[part 14 of 22: package /Cluster]
AUTOSAR XML (schema 4-3-0)
package /Cluster  (continued)
  9 x lin cluster, all with baudrate=19200, protocol-name=LIN, protocol-version=2.0:  (continued)
    E3V_SAM_LIN9
      lin physical channel CHNL: comm-connectors=CN_E3V_SAM_LIN9
        frame MasterReq_XIX_E3V_SAM_LIN9: id 0x3C, from SAM, frame-length=8, lin-checksum=CLASSIC
          n pdu MasterReq_XIX_E3V_SAM_LIN9: length=8
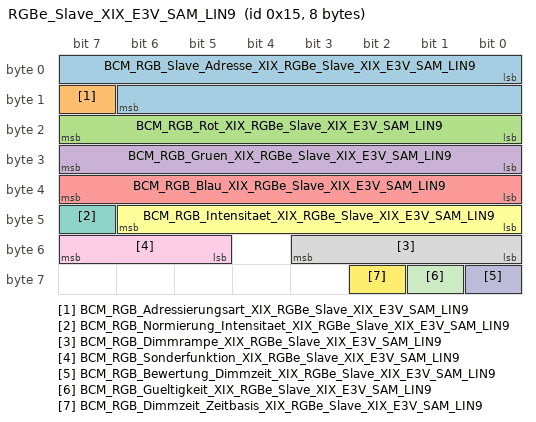
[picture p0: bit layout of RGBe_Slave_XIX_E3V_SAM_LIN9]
        frame RGBe_Slave_XIX_E3V_SAM_LIN9: id 0x15, from SAM, frame-length=8, lin-checksum=ENHANCED
          pdu RGBe_Slave_XIX_E3V_SAM_LIN9: length=8, unused-bit-pattern=0
            signal BCM_RGB_Slave_Adresse_XIX_RGBe_Slave_XIX_E3V_SAM_LIN9: start 0, 15 bit, little-endian, data-type-policy=OVERRIDE, i-signal-type=PRIMITIVE, base-type=BT_BCM_RGB_Slave_Adresse, compu {phys=raw for raw 0..32767; unit Unit_None}, range phys 0..32767 Unit_None, raw 0..32767, unit=Unit_None, transfer-property=PENDING  # Auswahl der Adresse für die RGB-Slaves (Hinweis: Adressierungsart beachten)
            signal BCM_RGB_Adressierungsart_XIX_RGBe_Slave_XIX_E3V_SAM_LIN9: start 15, 1 bit, little-endian, data-type-policy=OVERRIDE, i-signal-type=PRIMITIVE, base-type=BT_BCM_RGB_Adressierungsart, compu {0=Cx0_Einzeladresse (CM_BCM_RGB_Adressierungsart_Cx0_Einzeladresse), 1=Cx1_Gruppenadresse (CM_BCM_RGB_Adressierungsart_Cx1_Gruppenadresse)}, range raw 0..1, transfer-property=PENDING  # Auswahl der Adressierungsart für die RGB-Slaves: 0 = Einzeladadresse (Wertecodierung) 1 = Gruppenadresse
            signal BCM_RGB_Rot_XIX_RGBe_Slave_XIX_E3V_SAM_LIN9: start 16, 8 bit, little-endian, data-type-policy=OVERRIDE, i-signal-type=PRIMITIVE, base-type=BT_BCM_RGB_Rot, compu {phys=raw for raw 0..255}, range phys 0..255, raw 0..255, transfer-property=PENDING  # Farbanteil "Rot"
            signal BCM_RGB_Gruen_XIX_RGBe_Slave_XIX_E3V_SAM_LIN9: start 24, 8 bit, little-endian, data-type-policy=OVERRIDE, i-signal-type=PRIMITIVE, base-type=BT_BCM_RGB_Gruen, compu {phys=raw for raw 0..255}, range phys 0..255, raw 0..255, transfer-property=PENDING  # Farbanteil "Grün"
            signal BCM_RGB_Blau_XIX_RGBe_Slave_XIX_E3V_SAM_LIN9: start 32, 8 bit, little-endian, data-type-policy=OVERRIDE, i-signal-type=PRIMITIVE, base-type=BT_BCM_RGB_Blau, compu {phys=raw for raw 0..255}, range phys 0..255, raw 0..255, transfer-property=PENDING  # Farbanteil "Blau"
            signal BCM_RGB_Intensitaet_XIX_RGBe_Slave_XIX_E3V_SAM_LIN9: start 40, 7 bit, little-endian, data-type-policy=OVERRIDE, i-signal-type=PRIMITIVE, init-value=126, base-type=BT_BCM_RGB_Intensitaet, invalid-value=Invalid_BCM_RGB_Intensitaet_XIX_RGBe_Slave_XIX_E3V_SAM_LIN9:127, compu {phys=raw for raw 0..100, 126=Cx7e_Init (CM_BCM_RGB_Intensitaet_Cx7e_Init), 127=Cx7f_Fehler (CM_BCM_RGB_Intensitaet_Cx7f_Fehler); unit Unit_PerCent}, range phys 0..100 Unit_PerCent, raw 0..127, unit=Unit_PerCent, transfer-property=PENDING  # Intensität für RGB-Slave
            signal BCM_RGB_Normierung_Intensitaet_XIX_RGBe_Slave_XIX_E3V_SAM_LIN9: start 47, 1 bit, little-endian, data-type-policy=OVERRIDE, i-signal-type=PRIMITIVE, base-type=BT_BCM_RGB_Normierung_Intensitaet, compu {0=Cx0_ohne_Normierung (CM_BCM_RGB_Normierung_Intensitaet_Cx0_ohne_Normierung) (ohne Normierung), 1=Cx1_Normierung_der_Intensitaet (CM_BCM_RGB_Normierung_Intensitaet_Cx1_Normierung_der_Intensitaet) (Normierung der Intensität)}, range raw 0..1, transfer-property=PENDING  # Normierung der Intensität für die RGB-Slaves: 0 = keine Normierung 1 = Normierung
            signal BCM_RGB_Dimmrampe_XIX_RGBe_Slave_XIX_E3V_SAM_LIN9: start 48, 4 bit, little-endian, data-type-policy=OVERRIDE, i-signal-type=PRIMITIVE, base-type=BT_BCM_RGB_Dimmrampe, compu {phys=raw*0.25 for raw 0..15; unit Unit_Secon}, range phys 0..3.75 Unit_Secon, raw 0..15, unit=Unit_Secon, transfer-property=PENDING  # Vorgabe "Dimmzeit" für RGB-Slave
            signal BCM_RGB_Sonderfunktion_XIX_RGBe_Slave_XIX_E3V_SAM_LIN9: start 53, 3 bit, little-endian, data-type-policy=OVERRIDE, i-signal-type=PRIMITIVE, init-value=0, base-type=BT_BCM_RGB_Sonderfunktion, compu {0=Cx0_keine_Sonderfunktion (CM_BCM_RGB_Sonderfunktion_Cx0_keine_Sonderfunktion) (keine Sonderfunktion), 1=Cx1_Crash (CM_BCM_RGB_Sonderfunktion_Cx1_Crash), 2=Cx2_Showroommodus (CM_BCM_RGB_Sonderfunktion_Cx2_Showroommodus), 3=Cx3_Stellgliedtest (CM_BCM_RGB_Sonderfunktion_Cx3_Stellgliedtest), 4=Cx4_Vorhalt_z_B_FAS_Warnung (CM_BCM_RGB_Sonderfunktion_Cx4_Vorhalt_z_B_FAS_Warnung) (Vorhalt (z.B. FAS-Warnung)), 5=Cx5_Vorhalt (CM_BCM_RGB_Sonderfunktion_Cx5_Vorhalt), 6=Cx6_Lauflicht_Rueckwaerts (CM_BCM_RGB_Sonderfunktion_Cx6_Lauflicht_Rueckwaerts), 7=Cx7_Lauflicht_Vorwaerts (CM_BCM_RGB_Sonderfunktion_Cx7_Lauflicht_Vorwaerts)}, range raw 0..7, transfer-property=PENDING  # Aktivierung "Sonderfunktionen" im RGB-Slave
            signal BCM_RGB_Bewertung_Dimmzeit_XIX_RGBe_Slave_XIX_E3V_SAM_LIN9: start 56, 1 bit, little-endian, data-type-policy=OVERRIDE, i-signal-type=PRIMITIVE, base-type=BT_BCM_RGB_Bewertung_Dimmzeit, compu {0=Cx0_Dimmzeit_absolut (CM_BCM_RGB_Bewertung_Dimmzeit_Cx0_Dimmzeit_absolut), 1=Cx1_Dimmzeit_relativ (CM_BCM_RGB_Bewertung_Dimmzeit_Cx1_Dimmzeit_relativ)}, range raw 0..1, transfer-property=PENDING  # Interpretation der Dimmzeit im Slave: 0 - absolute Dimmzeit (von 0% auf 100%) 1 - relative Dimmzeit (von Ist- auf die Soll-Helligkeit)
            signal BCM_RGB_Gueltigkeit_XIX_RGBe_Slave_XIX_E3V_SAM_LIN9: start 57, 1 bit, little-endian, data-type-policy=OVERRIDE, i-signal-type=PRIMITIVE, base-type=BT_BCM_RGB_Gueltigkeit, compu {0=Cx0_ungueltig (CM_BCM_RGB_Gueltigkeit_Cx0_ungueltig), 1=Cx1_gueltig (CM_BCM_RGB_Gueltigkeit_Cx1_gueltig)}, range raw 0..1, transfer-property=PENDING  # Qualifizierungsinformation (notwendig bei der Übertragung "relativer" Dimmzeiten) 0 - Signale werden vom LIN-Slave ignoriert 1 - Signale sind vom LIN-Slave umzusetzen
            signal BCM_RGB_Dimmzeit_Zeitbasis_XIX_RGBe_Slave_XIX_E3V_SAM_LIN9: start 58, 1 bit, little-endian, data-type-policy=OVERRIDE, i-signal-type=PRIMITIVE, init-value=0, base-type=BT_BCM_RGB_Dimmzeit_Zeitbasis, compu {0=Cx0_Zeitbasis_50ms (CM_BCM_RGB_Dimmzeit_Zeitbasis_Cx0_Zeitbasis_50ms), 1=Cx1_Zeitbasis_250ms (CM_BCM_RGB_Dimmzeit_Zeitbasis_Cx1_Zeitbasis_250ms)}, range raw 0..1, transfer-property=PENDING  # Umschaltung der Zeitbasis für die Berechnung der Dimmzeit zwischen 250ms (Altwert, log. Signalwert: 1) und 50ms (log. Signalwert: 0)
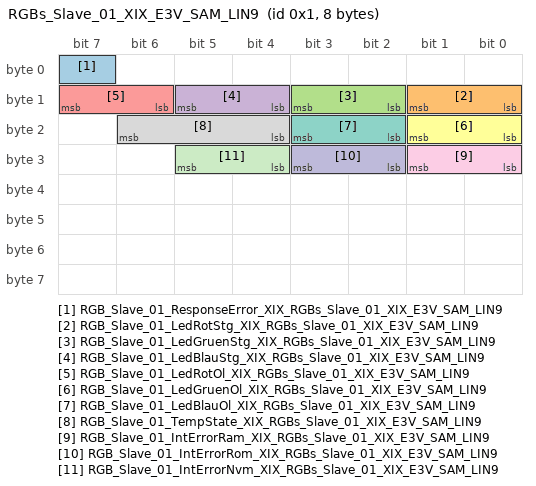
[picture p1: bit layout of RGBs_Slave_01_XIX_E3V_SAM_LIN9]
        frame RGBs_Slave_01_XIX_E3V_SAM_LIN9: id 0x1, to SAM, frame-length=8, lin-checksum=ENHANCED
          pdu RGBs_Slave_01_XIX_E3V_SAM_LIN9: length=8, unused-bit-pattern=0
            signal RGB_Slave_01_ResponseError_XIX_RGBs_Slave_01_XIX_E3V_SAM_LIN9: start 7, 1 bit, little-endian, data-type-policy=OVERRIDE, i-signal-type=PRIMITIVE, init-value=0, base-type=BT_RGB_Slave_01_ResponseError, invalid-value=Invalid_RGB_Slave_01_ResponseError_XIX_RGBs_Slave_01_XIX_E3V_SAM_LIN9:1, compu {0=Cx0_normal (CM_RGB_Slave_01_ResponseError_Cx0_normal), 1=Cx1_Fehler (CM_RGB_Slave_01_ResponseError_Cx1_Fehler)}, range raw 0..1, transfer-property=PENDING, to SAM(timeout 3.5 s)  # siehe LIN2.0-Specification (Darf nicht über ein Fehlergueltigkeitsbit abgesichtert werden!)
            signal RGB_Slave_01_LedRotStg_XIX_RGBs_Slave_01_XIX_E3V_SAM_LIN9: start 8, 2 bit, little-endian, data-type-policy=OVERRIDE, i-signal-type=PRIMITIVE, init-value=0, base-type=BT_RGB_Slave_01_LedRotStg, invalid-value=Invalid_RGB_Slave_01_LedRotStg_XIX_RGBs_Slave_01_XIX_E3V_SAM_LIN9:3, compu {0=Cx0_Init (CM_RGB_Slave_01_LedRotStg_Cx0_Init), 1=Cx1_nicht_erlaubt (CM_RGB_Slave_01_LedRotStg_Cx1_nicht_erlaubt), 2=Cx2_kein_Fehler (CM_RGB_Slave_01_LedRotStg_Cx2_kein_Fehler), 3=Cx3_Fehler (CM_RGB_Slave_01_LedRotStg_Cx3_Fehler)}, range raw 0..3, transfer-property=PENDING, to SAM(timeout 3.5 s)  # Short To Ground für Rote LED
            signal RGB_Slave_01_LedGruenStg_XIX_RGBs_Slave_01_XIX_E3V_SAM_LIN9: start 10, 2 bit, little-endian, data-type-policy=OVERRIDE, i-signal-type=PRIMITIVE, init-value=0, base-type=BT_RGB_Slave_01_LedGruenStg, invalid-value=Invalid_RGB_Slave_01_LedGruenStg_XIX_RGBs_Slave_01_XIX_E3V_SAM_LIN9:3, compu {0=Cx0_Init (CM_RGB_Slave_01_LedGruenStg_Cx0_Init), 1=Cx1_nicht_erlaubt (CM_RGB_Slave_01_LedGruenStg_Cx1_nicht_erlaubt), 2=Cx2_kein_Fehler (CM_RGB_Slave_01_LedGruenStg_Cx2_kein_Fehler), 3=Cx3_Fehler (CM_RGB_Slave_01_LedGruenStg_Cx3_Fehler)}, range raw 0..3, transfer-property=PENDING, to SAM(timeout 3.5 s)  # Short To Ground für Grüne LED
            signal RGB_Slave_01_LedBlauStg_XIX_RGBs_Slave_01_XIX_E3V_SAM_LIN9: start 12, 2 bit, little-endian, data-type-policy=OVERRIDE, i-signal-type=PRIMITIVE, init-value=0, base-type=BT_RGB_Slave_01_LedBlauStg, invalid-value=Invalid_RGB_Slave_01_LedBlauStg_XIX_RGBs_Slave_01_XIX_E3V_SAM_LIN9:3, compu {0=Cx0_Init (CM_RGB_Slave_01_LedBlauStg_Cx0_Init), 1=Cx1_nicht_erlaubt (CM_RGB_Slave_01_LedBlauStg_Cx1_nicht_erlaubt), 2=Cx2_kein_Fehler (CM_RGB_Slave_01_LedBlauStg_Cx2_kein_Fehler), 3=Cx3_Fehler (CM_RGB_Slave_01_LedBlauStg_Cx3_Fehler)}, range raw 0..3, transfer-property=PENDING, to SAM(timeout 3.5 s)  # Short To Ground für Blaue LED
            signal RGB_Slave_01_LedRotOl_XIX_RGBs_Slave_01_XIX_E3V_SAM_LIN9: start 14, 2 bit, little-endian, data-type-policy=OVERRIDE, i-signal-type=PRIMITIVE, init-value=0, base-type=BT_RGB_Slave_01_LedRotOl, invalid-value=Invalid_RGB_Slave_01_LedRotOl_XIX_RGBs_Slave_01_XIX_E3V_SAM_LIN9:3, compu {0=Cx0_Init (CM_RGB_Slave_01_LedRotOl_Cx0_Init), 1=Cx1_nicht_erlaubt (CM_RGB_Slave_01_LedRotOl_Cx1_nicht_erlaubt), 2=Cx2_kein_Fehler (CM_RGB_Slave_01_LedRotOl_Cx2_kein_Fehler), 3=Cx3_Fehler (CM_RGB_Slave_01_LedRotOl_Cx3_Fehler)}, range raw 0..3, transfer-property=PENDING, to SAM(timeout 3.5 s)  # OpenLoad für Rote LED
            signal RGB_Slave_01_LedGruenOl_XIX_RGBs_Slave_01_XIX_E3V_SAM_LIN9: start 16, 2 bit, little-endian, data-type-policy=OVERRIDE, i-signal-type=PRIMITIVE, init-value=0, base-type=BT_RGB_Slave_01_LedGruenOl, invalid-value=Invalid_RGB_Slave_01_LedGruenOl_XIX_RGBs_Slave_01_XIX_E3V_SAM_LIN9:3, compu {0=Cx0_Init (CM_RGB_Slave_01_LedGruenOl_Cx0_Init), 1=Cx1_nicht_erlaubt (CM_RGB_Slave_01_LedGruenOl_Cx1_nicht_erlaubt), 2=Cx2_kein_Fehler (CM_RGB_Slave_01_LedGruenOl_Cx2_kein_Fehler), 3=Cx3_Fehler (CM_RGB_Slave_01_LedGruenOl_Cx3_Fehler)}, range raw 0..3, transfer-property=PENDING, to SAM(timeout 3.5 s)  # OpenLoad für Rote LED
            signal RGB_Slave_01_LedBlauOl_XIX_RGBs_Slave_01_XIX_E3V_SAM_LIN9: start 18, 2 bit, little-endian, data-type-policy=OVERRIDE, i-signal-type=PRIMITIVE, init-value=0, base-type=BT_RGB_Slave_01_LedBlauOl, invalid-value=Invalid_RGB_Slave_01_LedBlauOl_XIX_RGBs_Slave_01_XIX_E3V_SAM_LIN9:3, compu {0=Cx0_Init (CM_RGB_Slave_01_LedBlauOl_Cx0_Init), 1=Cx1_nicht_erlaubt (CM_RGB_Slave_01_LedBlauOl_Cx1_nicht_erlaubt), 2=Cx2_kein_Fehler (CM_RGB_Slave_01_LedBlauOl_Cx2_kein_Fehler), 3=Cx3_Fehler (CM_RGB_Slave_01_LedBlauOl_Cx3_Fehler)}, range raw 0..3, transfer-property=PENDING, to SAM(timeout 3.5 s)  # OpenLoad für Blaue LED
            signal RGB_Slave_01_TempState_XIX_RGBs_Slave_01_XIX_E3V_SAM_LIN9: start 20, 3 bit, little-endian, data-type-policy=OVERRIDE, i-signal-type=PRIMITIVE, base-type=BT_RGB_Slave_01_TempState, compu {0=Cx0_keine_Temperaturregelung (CM_RGB_Slave_01_TempState_Cx0_keine_Temperaturregelung), 1=Cx1_Regelstufe_1 (CM_RGB_Slave_01_TempState_Cx1_Regelstufe_1), 2=Cx2_Regelstufe_2 (CM_RGB_Slave_01_TempState_Cx2_Regelstufe_2), 3=Cx3_Regelstufe_3 (CM_RGB_Slave_01_TempState_Cx3_Regelstufe_3), 4=Cx4_Regelstufe_4 (CM_RGB_Slave_01_TempState_Cx4_Regelstufe_4), 5=Cx5_Regelstufe_5 (CM_RGB_Slave_01_TempState_Cx5_Regelstufe_5), 6=Cx6_Regelstufe_6 (CM_RGB_Slave_01_TempState_Cx6_Regelstufe_6), 7=Cx7_Regelstufe_7 (CM_RGB_Slave_01_TempState_Cx7_Regelstufe_7)}, range raw 0..7, transfer-property=PENDING, to SAM(timeout 3.5 s)  # Status Temperaturregelung
            signal RGB_Slave_01_IntErrorRam_XIX_RGBs_Slave_01_XIX_E3V_SAM_LIN9: start 24, 2 bit, little-endian, data-type-policy=OVERRIDE, i-signal-type=PRIMITIVE, init-value=0, base-type=BT_RGB_Slave_01_IntErrorRam, invalid-value=Invalid_RGB_Slave_01_IntErrorRam_XIX_RGBs_Slave_01_XIX_E3V_SAM_LIN9:3, compu {0=Cx0_Init (CM_RGB_Slave_01_IntErrorRam_Cx0_Init), 1=Cx1_nicht_erlaubt (CM_RGB_Slave_01_IntErrorRam_Cx1_nicht_erlaubt), 2=Cx2_kein_Fehler (CM_RGB_Slave_01_IntErrorRam_Cx2_kein_Fehler), 3=Cx3_Fehler (CM_RGB_Slave_01_IntErrorRam_Cx3_Fehler)}, range raw 0..3, transfer-property=PENDING, to SAM(timeout 3.5 s)  # Fehler im RAM
            signal RGB_Slave_01_IntErrorRom_XIX_RGBs_Slave_01_XIX_E3V_SAM_LIN9: start 26, 2 bit, little-endian, data-type-policy=OVERRIDE, i-signal-type=PRIMITIVE, init-value=0, base-type=BT_RGB_Slave_01_IntErrorRom, invalid-value=Invalid_RGB_Slave_01_IntErrorRom_XIX_RGBs_Slave_01_XIX_E3V_SAM_LIN9:3, compu {0=Cx0_Init (CM_RGB_Slave_01_IntErrorRom_Cx0_Init), 1=Cx1_nicht_erlaubt (CM_RGB_Slave_01_IntErrorRom_Cx1_nicht_erlaubt), 2=Cx2_kein_Fehler (CM_RGB_Slave_01_IntErrorRom_Cx2_kein_Fehler), 3=Cx3_Fehler (CM_RGB_Slave_01_IntErrorRom_Cx3_Fehler)}, range raw 0..3, transfer-property=PENDING, to SAM(timeout 3.5 s)  # Fehler im ROM
            signal RGB_Slave_01_IntErrorNvm_XIX_RGBs_Slave_01_XIX_E3V_SAM_LIN9: start 28, 2 bit, little-endian, data-type-policy=OVERRIDE, i-signal-type=PRIMITIVE, init-value=0, base-type=BT_RGB_Slave_01_IntErrorNvm, invalid-value=Invalid_RGB_Slave_01_IntErrorNvm_XIX_RGBs_Slave_01_XIX_E3V_SAM_LIN9:3, compu {0=Cx0_Init (CM_RGB_Slave_01_IntErrorNvm_Cx0_Init), 1=Cx1_nicht_erlaubt (CM_RGB_Slave_01_IntErrorNvm_Cx1_nicht_erlaubt), 2=Cx2_kein_Fehler (CM_RGB_Slave_01_IntErrorNvm_Cx2_kein_Fehler), 3=Cx3_Fehler (CM_RGB_Slave_01_IntErrorNvm_Cx3_Fehler)}, range raw 0..3, transfer-property=PENDING, to SAM(timeout 3.5 s)  # Fehler im NVM
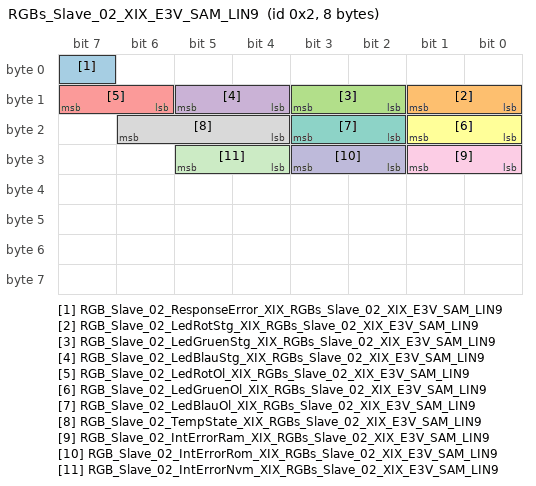
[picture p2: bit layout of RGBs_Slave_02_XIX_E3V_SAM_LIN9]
        frame RGBs_Slave_02_XIX_E3V_SAM_LIN9: id 0x2, to SAM, frame-length=8, lin-checksum=ENHANCED
          pdu RGBs_Slave_02_XIX_E3V_SAM_LIN9: length=8, unused-bit-pattern=0
            signal RGB_Slave_02_ResponseError_XIX_RGBs_Slave_02_XIX_E3V_SAM_LIN9: start 7, 1 bit, little-endian, data-type-policy=OVERRIDE, i-signal-type=PRIMITIVE, init-value=0, base-type=BT_RGB_Slave_02_ResponseError, invalid-value=Invalid_RGB_Slave_02_ResponseError_XIX_RGBs_Slave_02_XIX_E3V_SAM_LIN9:1, compu {0=Cx0_normal (CM_RGB_Slave_02_ResponseError_Cx0_normal), 1=Cx1_Fehler (CM_RGB_Slave_02_ResponseError_Cx1_Fehler)}, range raw 0..1, transfer-property=PENDING, to SAM(timeout 3.5 s)  # siehe LIN2.0-Specification (Darf nicht über ein Fehlergueltigkeitsbit abgesichtert werden!)
            signal RGB_Slave_02_LedRotStg_XIX_RGBs_Slave_02_XIX_E3V_SAM_LIN9: start 8, 2 bit, little-endian, data-type-policy=OVERRIDE, i-signal-type=PRIMITIVE, init-value=0, base-type=BT_RGB_Slave_02_LedRotStg, invalid-value=Invalid_RGB_Slave_02_LedRotStg_XIX_RGBs_Slave_02_XIX_E3V_SAM_LIN9:3, compu {0=Cx0_Init (CM_RGB_Slave_02_LedRotStg_Cx0_Init), 1=Cx1_nicht_erlaubt (CM_RGB_Slave_02_LedRotStg_Cx1_nicht_erlaubt), 2=Cx2_kein_Fehler (CM_RGB_Slave_02_LedRotStg_Cx2_kein_Fehler), 3=Cx3_Fehler (CM_RGB_Slave_02_LedRotStg_Cx3_Fehler)}, range raw 0..3, transfer-property=PENDING, to SAM(timeout 3.5 s)  # Short To Ground für Rote LED
            signal RGB_Slave_02_LedGruenStg_XIX_RGBs_Slave_02_XIX_E3V_SAM_LIN9: start 10, 2 bit, little-endian, data-type-policy=OVERRIDE, i-signal-type=PRIMITIVE, init-value=0, base-type=BT_RGB_Slave_02_LedGruenStg, invalid-value=Invalid_RGB_Slave_02_LedGruenStg_XIX_RGBs_Slave_02_XIX_E3V_SAM_LIN9:3, compu {0=Cx0_Init (CM_RGB_Slave_02_LedGruenStg_Cx0_Init), 1=Cx1_nicht_erlaubt (CM_RGB_Slave_02_LedGruenStg_Cx1_nicht_erlaubt), 2=Cx2_kein_Fehler (CM_RGB_Slave_02_LedGruenStg_Cx2_kein_Fehler), 3=Cx3_Fehler (CM_RGB_Slave_02_LedGruenStg_Cx3_Fehler)}, range raw 0..3, transfer-property=PENDING, to SAM(timeout 3.5 s)  # Short To Ground für Grüne LED
            signal RGB_Slave_02_LedBlauStg_XIX_RGBs_Slave_02_XIX_E3V_SAM_LIN9: start 12, 2 bit, little-endian, data-type-policy=OVERRIDE, i-signal-type=PRIMITIVE, init-value=0, base-type=BT_RGB_Slave_02_LedBlauStg, invalid-value=Invalid_RGB_Slave_02_LedBlauStg_XIX_RGBs_Slave_02_XIX_E3V_SAM_LIN9:3, compu {0=Cx0_Init (CM_RGB_Slave_02_LedBlauStg_Cx0_Init), 1=Cx1_nicht_erlaubt (CM_RGB_Slave_02_LedBlauStg_Cx1_nicht_erlaubt), 2=Cx2_kein_Fehler (CM_RGB_Slave_02_LedBlauStg_Cx2_kein_Fehler), 3=Cx3_Fehler (CM_RGB_Slave_02_LedBlauStg_Cx3_Fehler)}, range raw 0..3, transfer-property=PENDING, to SAM(timeout 3.5 s)  # Short To Ground für Blaue LED
            signal RGB_Slave_02_LedRotOl_XIX_RGBs_Slave_02_XIX_E3V_SAM_LIN9: start 14, 2 bit, little-endian, data-type-policy=OVERRIDE, i-signal-type=PRIMITIVE, init-value=0, base-type=BT_RGB_Slave_02_LedRotOl, invalid-value=Invalid_RGB_Slave_02_LedRotOl_XIX_RGBs_Slave_02_XIX_E3V_SAM_LIN9:3, compu {0=Cx0_Init (CM_RGB_Slave_02_LedRotOl_Cx0_Init), 1=Cx1_nicht_erlaubt (CM_RGB_Slave_02_LedRotOl_Cx1_nicht_erlaubt), 2=Cx2_kein_Fehler (CM_RGB_Slave_02_LedRotOl_Cx2_kein_Fehler), 3=Cx3_Fehler (CM_RGB_Slave_02_LedRotOl_Cx3_Fehler)}, range raw 0..3, transfer-property=PENDING, to SAM(timeout 3.5 s)  # OpenLoad für Rote LED
            signal RGB_Slave_02_LedGruenOl_XIX_RGBs_Slave_02_XIX_E3V_SAM_LIN9: start 16, 2 bit, little-endian, data-type-policy=OVERRIDE, i-signal-type=PRIMITIVE, init-value=0, base-type=BT_RGB_Slave_02_LedGruenOl, invalid-value=Invalid_RGB_Slave_02_LedGruenOl_XIX_RGBs_Slave_02_XIX_E3V_SAM_LIN9:3, compu {0=Cx0_Init (CM_RGB_Slave_02_LedGruenOl_Cx0_Init), 1=Cx1_nicht_erlaubt (CM_RGB_Slave_02_LedGruenOl_Cx1_nicht_erlaubt), 2=Cx2_kein_Fehler (CM_RGB_Slave_02_LedGruenOl_Cx2_kein_Fehler), 3=Cx3_Fehler (CM_RGB_Slave_02_LedGruenOl_Cx3_Fehler)}, range raw 0..3, transfer-property=PENDING, to SAM(timeout 3.5 s)  # OpenLoad für Rote LED
            signal RGB_Slave_02_LedBlauOl_XIX_RGBs_Slave_02_XIX_E3V_SAM_LIN9: start 18, 2 bit, little-endian, data-type-policy=OVERRIDE, i-signal-type=PRIMITIVE, init-value=0, base-type=BT_RGB_Slave_02_LedBlauOl, invalid-value=Invalid_RGB_Slave_02_LedBlauOl_XIX_RGBs_Slave_02_XIX_E3V_SAM_LIN9:3, compu {0=Cx0_Init (CM_RGB_Slave_02_LedBlauOl_Cx0_Init), 1=Cx1_nicht_erlaubt (CM_RGB_Slave_02_LedBlauOl_Cx1_nicht_erlaubt), 2=Cx2_kein_Fehler (CM_RGB_Slave_02_LedBlauOl_Cx2_kein_Fehler), 3=Cx3_Fehler (CM_RGB_Slave_02_LedBlauOl_Cx3_Fehler)}, range raw 0..3, transfer-property=PENDING, to SAM(timeout 3.5 s)  # OpenLoad für Blaue LED
            signal RGB_Slave_02_TempState_XIX_RGBs_Slave_02_XIX_E3V_SAM_LIN9: start 20, 3 bit, little-endian, data-type-policy=OVERRIDE, i-signal-type=PRIMITIVE, base-type=BT_RGB_Slave_02_TempState, compu {0=Cx0_keine_Temperaturregelung (CM_RGB_Slave_02_TempState_Cx0_keine_Temperaturregelung), 1=Cx1_Regelstufe_1 (CM_RGB_Slave_02_TempState_Cx1_Regelstufe_1), 2=Cx2_Regelstufe_2 (CM_RGB_Slave_02_TempState_Cx2_Regelstufe_2), 3=Cx3_Regelstufe_3 (CM_RGB_Slave_02_TempState_Cx3_Regelstufe_3), 4=Cx4_Regelstufe_4 (CM_RGB_Slave_02_TempState_Cx4_Regelstufe_4), 5=Cx5_Regelstufe_5 (CM_RGB_Slave_02_TempState_Cx5_Regelstufe_5), 6=Cx6_Regelstufe_6 (CM_RGB_Slave_02_TempState_Cx6_Regelstufe_6), 7=Cx7_Regelstufe_7 (CM_RGB_Slave_02_TempState_Cx7_Regelstufe_7)}, range raw 0..7, transfer-property=PENDING, to SAM(timeout 3.5 s)  # Status Temperaturregelung
            signal RGB_Slave_02_IntErrorRam_XIX_RGBs_Slave_02_XIX_E3V_SAM_LIN9: start 24, 2 bit, little-endian, data-type-policy=OVERRIDE, i-signal-type=PRIMITIVE, init-value=0, base-type=BT_RGB_Slave_02_IntErrorRam, invalid-value=Invalid_RGB_Slave_02_IntErrorRam_XIX_RGBs_Slave_02_XIX_E3V_SAM_LIN9:3, compu {0=Cx0_Init (CM_RGB_Slave_02_IntErrorRam_Cx0_Init), 1=Cx1_nicht_erlaubt (CM_RGB_Slave_02_IntErrorRam_Cx1_nicht_erlaubt), 2=Cx2_kein_Fehler (CM_RGB_Slave_02_IntErrorRam_Cx2_kein_Fehler), 3=Cx3_Fehler (CM_RGB_Slave_02_IntErrorRam_Cx3_Fehler)}, range raw 0..3, transfer-property=PENDING, to SAM(timeout 3.5 s)  # Fehler im RAM
            signal RGB_Slave_02_IntErrorRom_XIX_RGBs_Slave_02_XIX_E3V_SAM_LIN9: start 26, 2 bit, little-endian, data-type-policy=OVERRIDE, i-signal-type=PRIMITIVE, init-value=0, base-type=BT_RGB_Slave_02_IntErrorRom, invalid-value=Invalid_RGB_Slave_02_IntErrorRom_XIX_RGBs_Slave_02_XIX_E3V_SAM_LIN9:3, compu {0=Cx0_Init (CM_RGB_Slave_02_IntErrorRom_Cx0_Init), 1=Cx1_nicht_erlaubt (CM_RGB_Slave_02_IntErrorRom_Cx1_nicht_erlaubt), 2=Cx2_kein_Fehler (CM_RGB_Slave_02_IntErrorRom_Cx2_kein_Fehler), 3=Cx3_Fehler (CM_RGB_Slave_02_IntErrorRom_Cx3_Fehler)}, range raw 0..3, transfer-property=PENDING, to SAM(timeout 3.5 s)  # Fehler im ROM
            signal RGB_Slave_02_IntErrorNvm_XIX_RGBs_Slave_02_XIX_E3V_SAM_LIN9: start 28, 2 bit, little-endian, data-type-policy=OVERRIDE, i-signal-type=PRIMITIVE, init-value=0, base-type=BT_RGB_Slave_02_IntErrorNvm, invalid-value=Invalid_RGB_Slave_02_IntErrorNvm_XIX_RGBs_Slave_02_XIX_E3V_SAM_LIN9:3, compu {0=Cx0_Init (CM_RGB_Slave_02_IntErrorNvm_Cx0_Init), 1=Cx1_nicht_erlaubt (CM_RGB_Slave_02_IntErrorNvm_Cx1_nicht_erlaubt), 2=Cx2_kein_Fehler (CM_RGB_Slave_02_IntErrorNvm_Cx2_kein_Fehler), 3=Cx3_Fehler (CM_RGB_Slave_02_IntErrorNvm_Cx3_Fehler)}, range raw 0..3, transfer-property=PENDING, to SAM(timeout 3.5 s)  # Fehler im NVM
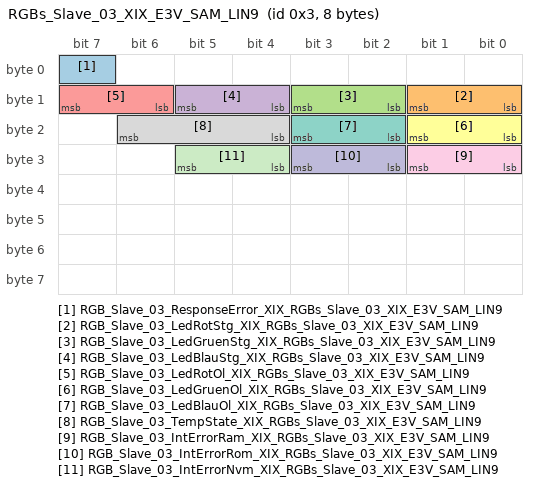
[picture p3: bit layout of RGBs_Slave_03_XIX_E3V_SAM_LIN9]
        frame RGBs_Slave_03_XIX_E3V_SAM_LIN9: id 0x3, to SAM, frame-length=8, lin-checksum=ENHANCED
          pdu RGBs_Slave_03_XIX_E3V_SAM_LIN9: length=8, unused-bit-pattern=0
            signal RGB_Slave_03_ResponseError_XIX_RGBs_Slave_03_XIX_E3V_SAM_LIN9: start 7, 1 bit, little-endian, data-type-policy=OVERRIDE, i-signal-type=PRIMITIVE, init-value=0, base-type=BT_RGB_Slave_03_ResponseError, invalid-value=Invalid_RGB_Slave_03_ResponseError_XIX_RGBs_Slave_03_XIX_E3V_SAM_LIN9:1, compu {0=Cx0_normal (CM_RGB_Slave_03_ResponseError_Cx0_normal), 1=Cx1_Fehler (CM_RGB_Slave_03_ResponseError_Cx1_Fehler)}, range raw 0..1, transfer-property=PENDING, to SAM(timeout 3.5 s)  # siehe LIN2.0-Specification (Darf nicht über ein Fehlergueltigkeitsbit abgesichtert werden!)
            signal RGB_Slave_03_LedRotStg_XIX_RGBs_Slave_03_XIX_E3V_SAM_LIN9: start 8, 2 bit, little-endian, data-type-policy=OVERRIDE, i-signal-type=PRIMITIVE, init-value=0, base-type=BT_RGB_Slave_03_LedRotStg, invalid-value=Invalid_RGB_Slave_03_LedRotStg_XIX_RGBs_Slave_03_XIX_E3V_SAM_LIN9:3, compu {0=Cx0_Init (CM_RGB_Slave_03_LedRotStg_Cx0_Init), 1=Cx1_nicht_erlaubt (CM_RGB_Slave_03_LedRotStg_Cx1_nicht_erlaubt), 2=Cx2_kein_Fehler (CM_RGB_Slave_03_LedRotStg_Cx2_kein_Fehler), 3=Cx3_Fehler (CM_RGB_Slave_03_LedRotStg_Cx3_Fehler)}, range raw 0..3, transfer-property=PENDING, to SAM(timeout 3.5 s)  # Short To Ground für Rote LED
            signal RGB_Slave_03_LedGruenStg_XIX_RGBs_Slave_03_XIX_E3V_SAM_LIN9: start 10, 2 bit, little-endian, data-type-policy=OVERRIDE, i-signal-type=PRIMITIVE, init-value=0, base-type=BT_RGB_Slave_03_LedGruenStg, invalid-value=Invalid_RGB_Slave_03_LedGruenStg_XIX_RGBs_Slave_03_XIX_E3V_SAM_LIN9:3, compu {0=Cx0_Init (CM_RGB_Slave_03_LedGruenStg_Cx0_Init), 1=Cx1_nicht_erlaubt (CM_RGB_Slave_03_LedGruenStg_Cx1_nicht_erlaubt), 2=Cx2_kein_Fehler (CM_RGB_Slave_03_LedGruenStg_Cx2_kein_Fehler), 3=Cx3_Fehler (CM_RGB_Slave_03_LedGruenStg_Cx3_Fehler)}, range raw 0..3, transfer-property=PENDING, to SAM(timeout 3.5 s)  # Short To Ground für Grüne LED
            signal RGB_Slave_03_LedBlauStg_XIX_RGBs_Slave_03_XIX_E3V_SAM_LIN9: start 12, 2 bit, little-endian, data-type-policy=OVERRIDE, i-signal-type=PRIMITIVE, init-value=0, base-type=BT_RGB_Slave_03_LedBlauStg, invalid-value=Invalid_RGB_Slave_03_LedBlauStg_XIX_RGBs_Slave_03_XIX_E3V_SAM_LIN9:3, compu {0=Cx0_Init (CM_RGB_Slave_03_LedBlauStg_Cx0_Init), 1=Cx1_nicht_erlaubt (CM_RGB_Slave_03_LedBlauStg_Cx1_nicht_erlaubt), 2=Cx2_kein_Fehler (CM_RGB_Slave_03_LedBlauStg_Cx2_kein_Fehler), 3=Cx3_Fehler (CM_RGB_Slave_03_LedBlauStg_Cx3_Fehler)}, range raw 0..3, transfer-property=PENDING, to SAM(timeout 3.5 s)  # Short To Ground für Blaue LED
            signal RGB_Slave_03_LedRotOl_XIX_RGBs_Slave_03_XIX_E3V_SAM_LIN9: start 14, 2 bit, little-endian, data-type-policy=OVERRIDE, i-signal-type=PRIMITIVE, init-value=0, base-type=BT_RGB_Slave_03_LedRotOl, invalid-value=Invalid_RGB_Slave_03_LedRotOl_XIX_RGBs_Slave_03_XIX_E3V_SAM_LIN9:3, compu {0=Cx0_Init (CM_RGB_Slave_03_LedRotOl_Cx0_Init), 1=Cx1_nicht_erlaubt (CM_RGB_Slave_03_LedRotOl_Cx1_nicht_erlaubt), 2=Cx2_kein_Fehler (CM_RGB_Slave_03_LedRotOl_Cx2_kein_Fehler), 3=Cx3_Fehler (CM_RGB_Slave_03_LedRotOl_Cx3_Fehler)}, range raw 0..3, transfer-property=PENDING, to SAM(timeout 3.5 s)  # OpenLoad für Rote LED
            signal RGB_Slave_03_LedGruenOl_XIX_RGBs_Slave_03_XIX_E3V_SAM_LIN9: start 16, 2 bit, little-endian, data-type-policy=OVERRIDE, i-signal-type=PRIMITIVE, init-value=0, base-type=BT_RGB_Slave_03_LedGruenOl, invalid-value=Invalid_RGB_Slave_03_LedGruenOl_XIX_RGBs_Slave_03_XIX_E3V_SAM_LIN9:3, compu {0=Cx0_Init (CM_RGB_Slave_03_LedGruenOl_Cx0_Init), 1=Cx1_nicht_erlaubt (CM_RGB_Slave_03_LedGruenOl_Cx1_nicht_erlaubt), 2=Cx2_kein_Fehler (CM_RGB_Slave_03_LedGruenOl_Cx2_kein_Fehler), 3=Cx3_Fehler (CM_RGB_Slave_03_LedGruenOl_Cx3_Fehler)}, range raw 0..3, transfer-property=PENDING, to SAM(timeout 3.5 s)  # OpenLoad für Rote LED
            signal RGB_Slave_03_LedBlauOl_XIX_RGBs_Slave_03_XIX_E3V_SAM_LIN9: start 18, 2 bit, little-endian, data-type-policy=OVERRIDE, i-signal-type=PRIMITIVE, init-value=0, base-type=BT_RGB_Slave_03_LedBlauOl, invalid-value=Invalid_RGB_Slave_03_LedBlauOl_XIX_RGBs_Slave_03_XIX_E3V_SAM_LIN9:3, compu {0=Cx0_Init (CM_RGB_Slave_03_LedBlauOl_Cx0_Init), 1=Cx1_nicht_erlaubt (CM_RGB_Slave_03_LedBlauOl_Cx1_nicht_erlaubt), 2=Cx2_kein_Fehler (CM_RGB_Slave_03_LedBlauOl_Cx2_kein_Fehler), 3=Cx3_Fehler (CM_RGB_Slave_03_LedBlauOl_Cx3_Fehler)}, range raw 0..3, transfer-property=PENDING, to SAM(timeout 3.5 s)  # OpenLoad für Blaue LED
            signal RGB_Slave_03_TempState_XIX_RGBs_Slave_03_XIX_E3V_SAM_LIN9: start 20, 3 bit, little-endian, data-type-policy=OVERRIDE, i-signal-type=PRIMITIVE, base-type=BT_RGB_Slave_03_TempState, compu {0=Cx0_keine_Temperaturregelung (CM_RGB_Slave_03_TempState_Cx0_keine_Temperaturregelung), 1=Cx1_Regelstufe_1 (CM_RGB_Slave_03_TempState_Cx1_Regelstufe_1), 2=Cx2_Regelstufe_2 (CM_RGB_Slave_03_TempState_Cx2_Regelstufe_2), 3=Cx3_Regelstufe_3 (CM_RGB_Slave_03_TempState_Cx3_Regelstufe_3), 4=Cx4_Regelstufe_4 (CM_RGB_Slave_03_TempState_Cx4_Regelstufe_4), 5=Cx5_Regelstufe_5 (CM_RGB_Slave_03_TempState_Cx5_Regelstufe_5), 6=Cx6_Regelstufe_6 (CM_RGB_Slave_03_TempState_Cx6_Regelstufe_6), 7=Cx7_Regelstufe_7 (CM_RGB_Slave_03_TempState_Cx7_Regelstufe_7)}, range raw 0..7, transfer-property=PENDING, to SAM(timeout 3.5 s)  # Status Temperaturregelung
            signal RGB_Slave_03_IntErrorRam_XIX_RGBs_Slave_03_XIX_E3V_SAM_LIN9: start 24, 2 bit, little-endian, data-type-policy=OVERRIDE, i-signal-type=PRIMITIVE, init-value=0, base-type=BT_RGB_Slave_03_IntErrorRam, invalid-value=Invalid_RGB_Slave_03_IntErrorRam_XIX_RGBs_Slave_03_XIX_E3V_SAM_LIN9:3, compu {0=Cx0_Init (CM_RGB_Slave_03_IntErrorRam_Cx0_Init), 1=Cx1_nicht_erlaubt (CM_RGB_Slave_03_IntErrorRam_Cx1_nicht_erlaubt), 2=Cx2_kein_Fehler (CM_RGB_Slave_03_IntErrorRam_Cx2_kein_Fehler), 3=Cx3_Fehler (CM_RGB_Slave_03_IntErrorRam_Cx3_Fehler)}, range raw 0..3, transfer-property=PENDING, to SAM(timeout 3.5 s)  # Fehler im RAM
            signal RGB_Slave_03_IntErrorRom_XIX_RGBs_Slave_03_XIX_E3V_SAM_LIN9: start 26, 2 bit, little-endian, data-type-policy=OVERRIDE, i-signal-type=PRIMITIVE, init-value=0, base-type=BT_RGB_Slave_03_IntErrorRom, invalid-value=Invalid_RGB_Slave_03_IntErrorRom_XIX_RGBs_Slave_03_XIX_E3V_SAM_LIN9:3, compu {0=Cx0_Init (CM_RGB_Slave_03_IntErrorRom_Cx0_Init), 1=Cx1_nicht_erlaubt (CM_RGB_Slave_03_IntErrorRom_Cx1_nicht_erlaubt), 2=Cx2_kein_Fehler (CM_RGB_Slave_03_IntErrorRom_Cx2_kein_Fehler), 3=Cx3_Fehler (CM_RGB_Slave_03_IntErrorRom_Cx3_Fehler)}, range raw 0..3, transfer-property=PENDING, to SAM(timeout 3.5 s)  # Fehler im ROM
            signal RGB_Slave_03_IntErrorNvm_XIX_RGBs_Slave_03_XIX_E3V_SAM_LIN9: start 28, 2 bit, little-endian, data-type-policy=OVERRIDE, i-signal-type=PRIMITIVE, init-value=0, base-type=BT_RGB_Slave_03_IntErrorNvm, invalid-value=Invalid_RGB_Slave_03_IntErrorNvm_XIX_RGBs_Slave_03_XIX_E3V_SAM_LIN9:3, compu {0=Cx0_Init (CM_RGB_Slave_03_IntErrorNvm_Cx0_Init), 1=Cx1_nicht_erlaubt (CM_RGB_Slave_03_IntErrorNvm_Cx1_nicht_erlaubt), 2=Cx2_kein_Fehler (CM_RGB_Slave_03_IntErrorNvm_Cx2_kein_Fehler), 3=Cx3_Fehler (CM_RGB_Slave_03_IntErrorNvm_Cx3_Fehler)}, range raw 0..3, transfer-property=PENDING, to SAM(timeout 3.5 s)  # Fehler im NVM
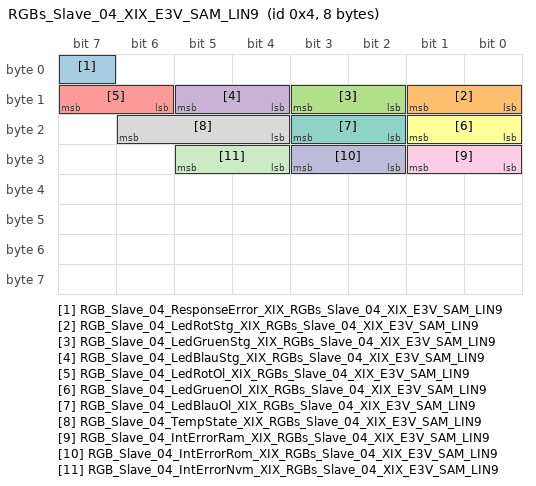
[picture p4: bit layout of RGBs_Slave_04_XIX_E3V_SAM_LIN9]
        frame RGBs_Slave_04_XIX_E3V_SAM_LIN9: id 0x4, to SAM, frame-length=8, lin-checksum=ENHANCED
          pdu RGBs_Slave_04_XIX_E3V_SAM_LIN9: length=8, unused-bit-pattern=0
            signal RGB_Slave_04_ResponseError_XIX_RGBs_Slave_04_XIX_E3V_SAM_LIN9: start 7, 1 bit, little-endian, data-type-policy=OVERRIDE, i-signal-type=PRIMITIVE, init-value=0, base-type=BT_RGB_Slave_04_ResponseError, invalid-value=Invalid_RGB_Slave_04_ResponseError_XIX_RGBs_Slave_04_XIX_E3V_SAM_LIN9:1, compu {0=Cx0_normal (CM_RGB_Slave_04_ResponseError_Cx0_normal), 1=Cx1_Fehler (CM_RGB_Slave_04_ResponseError_Cx1_Fehler)}, range raw 0..1, transfer-property=PENDING, to SAM(timeout 3.5 s)  # siehe LIN2.0-Specification (Darf nicht über ein Fehlergueltigkeitsbit abgesichtert werden!)
            signal RGB_Slave_04_LedRotStg_XIX_RGBs_Slave_04_XIX_E3V_SAM_LIN9: start 8, 2 bit, little-endian, data-type-policy=OVERRIDE, i-signal-type=PRIMITIVE, init-value=0, base-type=BT_RGB_Slave_04_LedRotStg, invalid-value=Invalid_RGB_Slave_04_LedRotStg_XIX_RGBs_Slave_04_XIX_E3V_SAM_LIN9:3, compu {0=Cx0_Init (CM_RGB_Slave_04_LedRotStg_Cx0_Init), 1=Cx1_nicht_erlaubt (CM_RGB_Slave_04_LedRotStg_Cx1_nicht_erlaubt), 2=Cx2_kein_Fehler (CM_RGB_Slave_04_LedRotStg_Cx2_kein_Fehler), 3=Cx3_Fehler (CM_RGB_Slave_04_LedRotStg_Cx3_Fehler)}, range raw 0..3, transfer-property=PENDING, to SAM(timeout 3.5 s)  # Short To Ground für Rote LED
            signal RGB_Slave_04_LedGruenStg_XIX_RGBs_Slave_04_XIX_E3V_SAM_LIN9: start 10, 2 bit, little-endian, data-type-policy=OVERRIDE, i-signal-type=PRIMITIVE, init-value=0, base-type=BT_RGB_Slave_04_LedGruenStg, invalid-value=Invalid_RGB_Slave_04_LedGruenStg_XIX_RGBs_Slave_04_XIX_E3V_SAM_LIN9:3, compu {0=Cx0_Init (CM_RGB_Slave_04_LedGruenStg_Cx0_Init), 1=Cx1_nicht_erlaubt (CM_RGB_Slave_04_LedGruenStg_Cx1_nicht_erlaubt), 2=Cx2_kein_Fehler (CM_RGB_Slave_04_LedGruenStg_Cx2_kein_Fehler), 3=Cx3_Fehler (CM_RGB_Slave_04_LedGruenStg_Cx3_Fehler)}, range raw 0..3, transfer-property=PENDING, to SAM(timeout 3.5 s)  # Short To Ground für Grüne LED
            signal RGB_Slave_04_LedBlauStg_XIX_RGBs_Slave_04_XIX_E3V_SAM_LIN9: start 12, 2 bit, little-endian, data-type-policy=OVERRIDE, i-signal-type=PRIMITIVE, init-value=0, base-type=BT_RGB_Slave_04_LedBlauStg, invalid-value=Invalid_RGB_Slave_04_LedBlauStg_XIX_RGBs_Slave_04_XIX_E3V_SAM_LIN9:3, compu {0=Cx0_Init (CM_RGB_Slave_04_LedBlauStg_Cx0_Init), 1=Cx1_nicht_erlaubt (CM_RGB_Slave_04_LedBlauStg_Cx1_nicht_erlaubt), 2=Cx2_kein_Fehler (CM_RGB_Slave_04_LedBlauStg_Cx2_kein_Fehler), 3=Cx3_Fehler (CM_RGB_Slave_04_LedBlauStg_Cx3_Fehler)}, range raw 0..3, transfer-property=PENDING, to SAM(timeout 3.5 s)  # Short To Ground für Blaue LED
            signal RGB_Slave_04_LedRotOl_XIX_RGBs_Slave_04_XIX_E3V_SAM_LIN9: start 14, 2 bit, little-endian, data-type-policy=OVERRIDE, i-signal-type=PRIMITIVE, init-value=0, base-type=BT_RGB_Slave_04_LedRotOl, invalid-value=Invalid_RGB_Slave_04_LedRotOl_XIX_RGBs_Slave_04_XIX_E3V_SAM_LIN9:3, compu {0=Cx0_Init (CM_RGB_Slave_04_LedRotOl_Cx0_Init), 1=Cx1_nicht_erlaubt (CM_RGB_Slave_04_LedRotOl_Cx1_nicht_erlaubt), 2=Cx2_kein_Fehler (CM_RGB_Slave_04_LedRotOl_Cx2_kein_Fehler), 3=Cx3_Fehler (CM_RGB_Slave_04_LedRotOl_Cx3_Fehler)}, range raw 0..3, transfer-property=PENDING, to SAM(timeout 3.5 s)  # OpenLoad für Rote LED
            signal RGB_Slave_04_LedGruenOl_XIX_RGBs_Slave_04_XIX_E3V_SAM_LIN9: start 16, 2 bit, little-endian, data-type-policy=OVERRIDE, i-signal-type=PRIMITIVE, init-value=0, base-type=BT_RGB_Slave_04_LedGruenOl, invalid-value=Invalid_RGB_Slave_04_LedGruenOl_XIX_RGBs_Slave_04_XIX_E3V_SAM_LIN9:3, compu {0=Cx0_Init (CM_RGB_Slave_04_LedGruenOl_Cx0_Init), 1=Cx1_nicht_erlaubt (CM_RGB_Slave_04_LedGruenOl_Cx1_nicht_erlaubt), 2=Cx2_kein_Fehler (CM_RGB_Slave_04_LedGruenOl_Cx2_kein_Fehler), 3=Cx3_Fehler (CM_RGB_Slave_04_LedGruenOl_Cx3_Fehler)}, range raw 0..3, transfer-property=PENDING, to SAM(timeout 3.5 s)  # OpenLoad für Rote LED
            signal RGB_Slave_04_LedBlauOl_XIX_RGBs_Slave_04_XIX_E3V_SAM_LIN9: start 18, 2 bit, little-endian, data-type-policy=OVERRIDE, i-signal-type=PRIMITIVE, init-value=0, base-type=BT_RGB_Slave_04_LedBlauOl, invalid-value=Invalid_RGB_Slave_04_LedBlauOl_XIX_RGBs_Slave_04_XIX_E3V_SAM_LIN9:3, compu {0=Cx0_Init (CM_RGB_Slave_04_LedBlauOl_Cx0_Init), 1=Cx1_nicht_erlaubt (CM_RGB_Slave_04_LedBlauOl_Cx1_nicht_erlaubt), 2=Cx2_kein_Fehler (CM_RGB_Slave_04_LedBlauOl_Cx2_kein_Fehler), 3=Cx3_Fehler (CM_RGB_Slave_04_LedBlauOl_Cx3_Fehler)}, range raw 0..3, transfer-property=PENDING, to SAM(timeout 3.5 s)  # OpenLoad für Blaue LED
            signal RGB_Slave_04_TempState_XIX_RGBs_Slave_04_XIX_E3V_SAM_LIN9: start 20, 3 bit, little-endian, data-type-policy=OVERRIDE, i-signal-type=PRIMITIVE, base-type=BT_RGB_Slave_04_TempState, compu {0=Cx0_keine_Temperaturregelung (CM_RGB_Slave_04_TempState_Cx0_keine_Temperaturregelung), 1=Cx1_Regelstufe_1 (CM_RGB_Slave_04_TempState_Cx1_Regelstufe_1), 2=Cx2_Regelstufe_2 (CM_RGB_Slave_04_TempState_Cx2_Regelstufe_2), 3=Cx3_Regelstufe_3 (CM_RGB_Slave_04_TempState_Cx3_Regelstufe_3), 4=Cx4_Regelstufe_4 (CM_RGB_Slave_04_TempState_Cx4_Regelstufe_4), 5=Cx5_Regelstufe_5 (CM_RGB_Slave_04_TempState_Cx5_Regelstufe_5), 6=Cx6_Regelstufe_6 (CM_RGB_Slave_04_TempState_Cx6_Regelstufe_6), 7=Cx7_Regelstufe_7 (CM_RGB_Slave_04_TempState_Cx7_Regelstufe_7)}, range raw 0..7, transfer-property=PENDING, to SAM(timeout 3.5 s)  # Status Temperaturregelung
            signal RGB_Slave_04_IntErrorRam_XIX_RGBs_Slave_04_XIX_E3V_SAM_LIN9: start 24, 2 bit, little-endian, data-type-policy=OVERRIDE, i-signal-type=PRIMITIVE, init-value=0, base-type=BT_RGB_Slave_04_IntErrorRam, invalid-value=Invalid_RGB_Slave_04_IntErrorRam_XIX_RGBs_Slave_04_XIX_E3V_SAM_LIN9:3, compu {0=Cx0_Init (CM_RGB_Slave_04_IntErrorRam_Cx0_Init), 1=Cx1_nicht_erlaubt (CM_RGB_Slave_04_IntErrorRam_Cx1_nicht_erlaubt), 2=Cx2_kein_Fehler (CM_RGB_Slave_04_IntErrorRam_Cx2_kein_Fehler), 3=Cx3_Fehler (CM_RGB_Slave_04_IntErrorRam_Cx3_Fehler)}, range raw 0..3, transfer-property=PENDING, to SAM(timeout 3.5 s)  # Fehler im RAM
            signal RGB_Slave_04_IntErrorRom_XIX_RGBs_Slave_04_XIX_E3V_SAM_LIN9: start 26, 2 bit, little-endian, data-type-policy=OVERRIDE, i-signal-type=PRIMITIVE, init-value=0, base-type=BT_RGB_Slave_04_IntErrorRom, invalid-value=Invalid_RGB_Slave_04_IntErrorRom_XIX_RGBs_Slave_04_XIX_E3V_SAM_LIN9:3, compu {0=Cx0_Init (CM_RGB_Slave_04_IntErrorRom_Cx0_Init), 1=Cx1_nicht_erlaubt (CM_RGB_Slave_04_IntErrorRom_Cx1_nicht_erlaubt), 2=Cx2_kein_Fehler (CM_RGB_Slave_04_IntErrorRom_Cx2_kein_Fehler), 3=Cx3_Fehler (CM_RGB_Slave_04_IntErrorRom_Cx3_Fehler)}, range raw 0..3, transfer-property=PENDING, to SAM(timeout 3.5 s)  # Fehler im ROM
            signal RGB_Slave_04_IntErrorNvm_XIX_RGBs_Slave_04_XIX_E3V_SAM_LIN9: start 28, 2 bit, little-endian, data-type-policy=OVERRIDE, i-signal-type=PRIMITIVE, init-value=0, base-type=BT_RGB_Slave_04_IntErrorNvm, invalid-value=Invalid_RGB_Slave_04_IntErrorNvm_XIX_RGBs_Slave_04_XIX_E3V_SAM_LIN9:3, compu {0=Cx0_Init (CM_RGB_Slave_04_IntErrorNvm_Cx0_Init), 1=Cx1_nicht_erlaubt (CM_RGB_Slave_04_IntErrorNvm_Cx1_nicht_erlaubt), 2=Cx2_kein_Fehler (CM_RGB_Slave_04_IntErrorNvm_Cx2_kein_Fehler), 3=Cx3_Fehler (CM_RGB_Slave_04_IntErrorNvm_Cx3_Fehler)}, range raw 0..3, transfer-property=PENDING, to SAM(timeout 3.5 s)  # Fehler im NVM
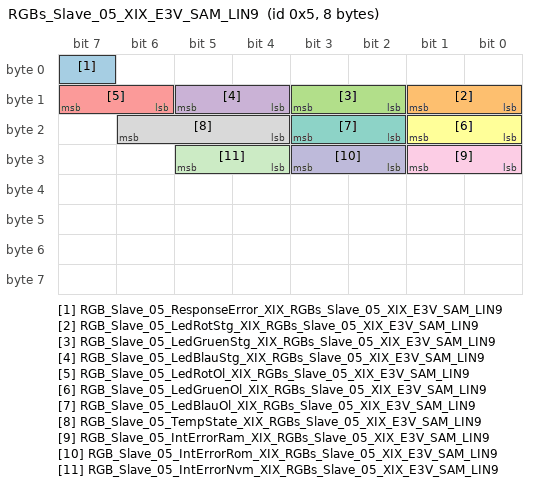
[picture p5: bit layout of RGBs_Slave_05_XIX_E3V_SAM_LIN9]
        frame RGBs_Slave_05_XIX_E3V_SAM_LIN9: id 0x5, to SAM, frame-length=8, lin-checksum=ENHANCED
          pdu RGBs_Slave_05_XIX_E3V_SAM_LIN9: length=8, unused-bit-pattern=0
            signal RGB_Slave_05_ResponseError_XIX_RGBs_Slave_05_XIX_E3V_SAM_LIN9: start 7, 1 bit, little-endian, data-type-policy=OVERRIDE, i-signal-type=PRIMITIVE, init-value=0, base-type=BT_RGB_Slave_05_ResponseError, invalid-value=Invalid_RGB_Slave_05_ResponseError_XIX_RGBs_Slave_05_XIX_E3V_SAM_LIN9:1, compu {0=Cx0_normal (CM_RGB_Slave_05_ResponseError_Cx0_normal), 1=Cx1_Fehler (CM_RGB_Slave_05_ResponseError_Cx1_Fehler)}, range raw 0..1, transfer-property=PENDING, to SAM(timeout 3.5 s)  # siehe LIN2.0-Specification (Darf nicht über ein Fehlergueltigkeitsbit abgesichtert werden!)
            signal RGB_Slave_05_LedRotStg_XIX_RGBs_Slave_05_XIX_E3V_SAM_LIN9: start 8, 2 bit, little-endian, data-type-policy=OVERRIDE, i-signal-type=PRIMITIVE, init-value=0, base-type=BT_RGB_Slave_05_LedRotStg, invalid-value=Invalid_RGB_Slave_05_LedRotStg_XIX_RGBs_Slave_05_XIX_E3V_SAM_LIN9:3, compu {0=Cx0_Init (CM_RGB_Slave_05_LedRotStg_Cx0_Init), 1=Cx1_nicht_erlaubt (CM_RGB_Slave_05_LedRotStg_Cx1_nicht_erlaubt), 2=Cx2_kein_Fehler (CM_RGB_Slave_05_LedRotStg_Cx2_kein_Fehler), 3=Cx3_Fehler (CM_RGB_Slave_05_LedRotStg_Cx3_Fehler)}, range raw 0..3, transfer-property=PENDING, to SAM(timeout 3.5 s)  # Short To Ground für Rote LED
            signal RGB_Slave_05_LedGruenStg_XIX_RGBs_Slave_05_XIX_E3V_SAM_LIN9: start 10, 2 bit, little-endian, data-type-policy=OVERRIDE, i-signal-type=PRIMITIVE, init-value=0, base-type=BT_RGB_Slave_05_LedGruenStg, invalid-value=Invalid_RGB_Slave_05_LedGruenStg_XIX_RGBs_Slave_05_XIX_E3V_SAM_LIN9:3, compu {0=Cx0_Init (CM_RGB_Slave_05_LedGruenStg_Cx0_Init), 1=Cx1_nicht_erlaubt (CM_RGB_Slave_05_LedGruenStg_Cx1_nicht_erlaubt), 2=Cx2_kein_Fehler (CM_RGB_Slave_05_LedGruenStg_Cx2_kein_Fehler), 3=Cx3_Fehler (CM_RGB_Slave_05_LedGruenStg_Cx3_Fehler)}, range raw 0..3, transfer-property=PENDING, to SAM(timeout 3.5 s)  # Short To Ground für Grüne LED
            signal RGB_Slave_05_LedBlauStg_XIX_RGBs_Slave_05_XIX_E3V_SAM_LIN9: start 12, 2 bit, little-endian, data-type-policy=OVERRIDE, i-signal-type=PRIMITIVE, init-value=0, base-type=BT_RGB_Slave_05_LedBlauStg, invalid-value=Invalid_RGB_Slave_05_LedBlauStg_XIX_RGBs_Slave_05_XIX_E3V_SAM_LIN9:3, compu {0=Cx0_Init (CM_RGB_Slave_05_LedBlauStg_Cx0_Init), 1=Cx1_nicht_erlaubt (CM_RGB_Slave_05_LedBlauStg_Cx1_nicht_erlaubt), 2=Cx2_kein_Fehler (CM_RGB_Slave_05_LedBlauStg_Cx2_kein_Fehler), 3=Cx3_Fehler (CM_RGB_Slave_05_LedBlauStg_Cx3_Fehler)}, range raw 0..3, transfer-property=PENDING, to SAM(timeout 3.5 s)  # Short To Ground für Blaue LED
            signal RGB_Slave_05_LedRotOl_XIX_RGBs_Slave_05_XIX_E3V_SAM_LIN9: start 14, 2 bit, little-endian, data-type-policy=OVERRIDE, i-signal-type=PRIMITIVE, init-value=0, base-type=BT_RGB_Slave_05_LedRotOl, invalid-value=Invalid_RGB_Slave_05_LedRotOl_XIX_RGBs_Slave_05_XIX_E3V_SAM_LIN9:3, compu {0=Cx0_Init (CM_RGB_Slave_05_LedRotOl_Cx0_Init), 1=Cx1_nicht_erlaubt (CM_RGB_Slave_05_LedRotOl_Cx1_nicht_erlaubt), 2=Cx2_kein_Fehler (CM_RGB_Slave_05_LedRotOl_Cx2_kein_Fehler), 3=Cx3_Fehler (CM_RGB_Slave_05_LedRotOl_Cx3_Fehler)}, range raw 0..3, transfer-property=PENDING, to SAM(timeout 3.5 s)  # OpenLoad für Rote LED
            signal RGB_Slave_05_LedGruenOl_XIX_RGBs_Slave_05_XIX_E3V_SAM_LIN9: start 16, 2 bit, little-endian, data-type-policy=OVERRIDE, i-signal-type=PRIMITIVE, init-value=0, base-type=BT_RGB_Slave_05_LedGruenOl, invalid-value=Invalid_RGB_Slave_05_LedGruenOl_XIX_RGBs_Slave_05_XIX_E3V_SAM_LIN9:3, compu {0=Cx0_Init (CM_RGB_Slave_05_LedGruenOl_Cx0_Init), 1=Cx1_nicht_erlaubt (CM_RGB_Slave_05_LedGruenOl_Cx1_nicht_erlaubt), 2=Cx2_kein_Fehler (CM_RGB_Slave_05_LedGruenOl_Cx2_kein_Fehler), 3=Cx3_Fehler (CM_RGB_Slave_05_LedGruenOl_Cx3_Fehler)}, range raw 0..3, transfer-property=PENDING, to SAM(timeout 3.5 s)  # OpenLoad für Rote LED
            signal RGB_Slave_05_LedBlauOl_XIX_RGBs_Slave_05_XIX_E3V_SAM_LIN9: start 18, 2 bit, little-endian, data-type-policy=OVERRIDE, i-signal-type=PRIMITIVE, init-value=0, base-type=BT_RGB_Slave_05_LedBlauOl, invalid-value=Invalid_RGB_Slave_05_LedBlauOl_XIX_RGBs_Slave_05_XIX_E3V_SAM_LIN9:3, compu {0=Cx0_Init (CM_RGB_Slave_05_LedBlauOl_Cx0_Init), 1=Cx1_nicht_erlaubt (CM_RGB_Slave_05_LedBlauOl_Cx1_nicht_erlaubt), 2=Cx2_kein_Fehler (CM_RGB_Slave_05_LedBlauOl_Cx2_kein_Fehler), 3=Cx3_Fehler (CM_RGB_Slave_05_LedBlauOl_Cx3_Fehler)}, range raw 0..3, transfer-property=PENDING, to SAM(timeout 3.5 s)  # OpenLoad für Blaue LED
            signal RGB_Slave_05_TempState_XIX_RGBs_Slave_05_XIX_E3V_SAM_LIN9: start 20, 3 bit, little-endian, data-type-policy=OVERRIDE, i-signal-type=PRIMITIVE, base-type=BT_RGB_Slave_05_TempState, compu {0=Cx0_keine_Temperaturregelung (CM_RGB_Slave_05_TempState_Cx0_keine_Temperaturregelung), 1=Cx1_Regelstufe_1 (CM_RGB_Slave_05_TempState_Cx1_Regelstufe_1), 2=Cx2_Regelstufe_2 (CM_RGB_Slave_05_TempState_Cx2_Regelstufe_2), 3=Cx3_Regelstufe_3 (CM_RGB_Slave_05_TempState_Cx3_Regelstufe_3), 4=Cx4_Regelstufe_4 (CM_RGB_Slave_05_TempState_Cx4_Regelstufe_4), 5=Cx5_Regelstufe_5 (CM_RGB_Slave_05_TempState_Cx5_Regelstufe_5), 6=Cx6_Regelstufe_6 (CM_RGB_Slave_05_TempState_Cx6_Regelstufe_6), 7=Cx7_Regelstufe_7 (CM_RGB_Slave_05_TempState_Cx7_Regelstufe_7)}, range raw 0..7, transfer-property=PENDING, to SAM(timeout 3.5 s)  # Status Temperaturregelung
            signal RGB_Slave_05_IntErrorRam_XIX_RGBs_Slave_05_XIX_E3V_SAM_LIN9: start 24, 2 bit, little-endian, data-type-policy=OVERRIDE, i-signal-type=PRIMITIVE, init-value=0, base-type=BT_RGB_Slave_05_IntErrorRam, invalid-value=Invalid_RGB_Slave_05_IntErrorRam_XIX_RGBs_Slave_05_XIX_E3V_SAM_LIN9:3, compu {0=Cx0_Init (CM_RGB_Slave_05_IntErrorRam_Cx0_Init), 1=Cx1_nicht_erlaubt (CM_RGB_Slave_05_IntErrorRam_Cx1_nicht_erlaubt), 2=Cx2_kein_Fehler (CM_RGB_Slave_05_IntErrorRam_Cx2_kein_Fehler), 3=Cx3_Fehler (CM_RGB_Slave_05_IntErrorRam_Cx3_Fehler)}, range raw 0..3, transfer-property=PENDING, to SAM(timeout 3.5 s)  # Fehler im RAM
            signal RGB_Slave_05_IntErrorRom_XIX_RGBs_Slave_05_XIX_E3V_SAM_LIN9: start 26, 2 bit, little-endian, data-type-policy=OVERRIDE, i-signal-type=PRIMITIVE, init-value=0, base-type=BT_RGB_Slave_05_IntErrorRom, invalid-value=Invalid_RGB_Slave_05_IntErrorRom_XIX_RGBs_Slave_05_XIX_E3V_SAM_LIN9:3, compu {0=Cx0_Init (CM_RGB_Slave_05_IntErrorRom_Cx0_Init), 1=Cx1_nicht_erlaubt (CM_RGB_Slave_05_IntErrorRom_Cx1_nicht_erlaubt), 2=Cx2_kein_Fehler (CM_RGB_Slave_05_IntErrorRom_Cx2_kein_Fehler), 3=Cx3_Fehler (CM_RGB_Slave_05_IntErrorRom_Cx3_Fehler)}, range raw 0..3, transfer-property=PENDING, to SAM(timeout 3.5 s)  # Fehler im ROM
            signal RGB_Slave_05_IntErrorNvm_XIX_RGBs_Slave_05_XIX_E3V_SAM_LIN9: start 28, 2 bit, little-endian, data-type-policy=OVERRIDE, i-signal-type=PRIMITIVE, init-value=0, base-type=BT_RGB_Slave_05_IntErrorNvm, invalid-value=Invalid_RGB_Slave_05_IntErrorNvm_XIX_RGBs_Slave_05_XIX_E3V_SAM_LIN9:3, compu {0=Cx0_Init (CM_RGB_Slave_05_IntErrorNvm_Cx0_Init), 1=Cx1_nicht_erlaubt (CM_RGB_Slave_05_IntErrorNvm_Cx1_nicht_erlaubt), 2=Cx2_kein_Fehler (CM_RGB_Slave_05_IntErrorNvm_Cx2_kein_Fehler), 3=Cx3_Fehler (CM_RGB_Slave_05_IntErrorNvm_Cx3_Fehler)}, range raw 0..3, transfer-property=PENDING, to SAM(timeout 3.5 s)  # Fehler im NVM
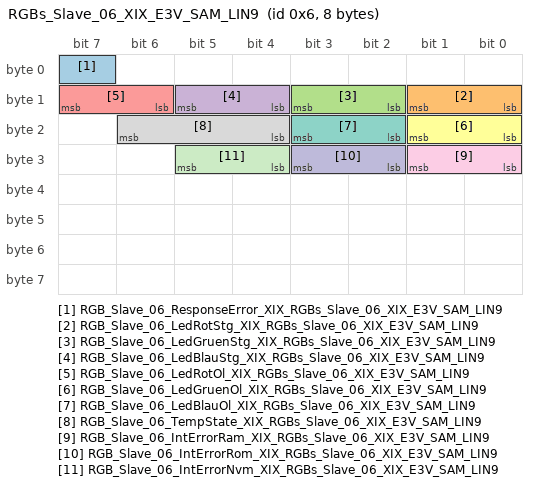
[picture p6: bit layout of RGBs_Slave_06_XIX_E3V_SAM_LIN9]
        frame RGBs_Slave_06_XIX_E3V_SAM_LIN9: id 0x6, to SAM, frame-length=8, lin-checksum=ENHANCED
          pdu RGBs_Slave_06_XIX_E3V_SAM_LIN9: length=8, unused-bit-pattern=0
            signal RGB_Slave_06_ResponseError_XIX_RGBs_Slave_06_XIX_E3V_SAM_LIN9: start 7, 1 bit, little-endian, data-type-policy=OVERRIDE, i-signal-type=PRIMITIVE, init-value=0, base-type=BT_RGB_Slave_06_ResponseError, invalid-value=Invalid_RGB_Slave_06_ResponseError_XIX_RGBs_Slave_06_XIX_E3V_SAM_LIN9:1, compu {0=Cx0_normal (CM_RGB_Slave_06_ResponseError_Cx0_normal), 1=Cx1_Fehler (CM_RGB_Slave_06_ResponseError_Cx1_Fehler)}, range raw 0..1, transfer-property=PENDING, to SAM(timeout 3.5 s)  # siehe LIN2.0-Specification (Darf nicht über ein Fehlergueltigkeitsbit abgesichtert werden!)
            signal RGB_Slave_06_LedRotStg_XIX_RGBs_Slave_06_XIX_E3V_SAM_LIN9: start 8, 2 bit, little-endian, data-type-policy=OVERRIDE, i-signal-type=PRIMITIVE, init-value=0, base-type=BT_RGB_Slave_06_LedRotStg, invalid-value=Invalid_RGB_Slave_06_LedRotStg_XIX_RGBs_Slave_06_XIX_E3V_SAM_LIN9:3, compu {0=Cx0_Init (CM_RGB_Slave_06_LedRotStg_Cx0_Init), 1=Cx1_nicht_erlaubt (CM_RGB_Slave_06_LedRotStg_Cx1_nicht_erlaubt), 2=Cx2_kein_Fehler (CM_RGB_Slave_06_LedRotStg_Cx2_kein_Fehler), 3=Cx3_Fehler (CM_RGB_Slave_06_LedRotStg_Cx3_Fehler)}, range raw 0..3, transfer-property=PENDING, to SAM(timeout 3.5 s)  # Short To Ground für Rote LED
            signal RGB_Slave_06_LedGruenStg_XIX_RGBs_Slave_06_XIX_E3V_SAM_LIN9: start 10, 2 bit, little-endian, data-type-policy=OVERRIDE, i-signal-type=PRIMITIVE, init-value=0, base-type=BT_RGB_Slave_06_LedGruenStg, invalid-value=Invalid_RGB_Slave_06_LedGruenStg_XIX_RGBs_Slave_06_XIX_E3V_SAM_LIN9:3, compu {0=Cx0_Init (CM_RGB_Slave_06_LedGruenStg_Cx0_Init), 1=Cx1_nicht_erlaubt (CM_RGB_Slave_06_LedGruenStg_Cx1_nicht_erlaubt), 2=Cx2_kein_Fehler (CM_RGB_Slave_06_LedGruenStg_Cx2_kein_Fehler), 3=Cx3_Fehler (CM_RGB_Slave_06_LedGruenStg_Cx3_Fehler)}, range raw 0..3, transfer-property=PENDING, to SAM(timeout 3.5 s)  # Short To Ground für Grüne LED
            signal RGB_Slave_06_LedBlauStg_XIX_RGBs_Slave_06_XIX_E3V_SAM_LIN9: start 12, 2 bit, little-endian, data-type-policy=OVERRIDE, i-signal-type=PRIMITIVE, init-value=0, base-type=BT_RGB_Slave_06_LedBlauStg, invalid-value=Invalid_RGB_Slave_06_LedBlauStg_XIX_RGBs_Slave_06_XIX_E3V_SAM_LIN9:3, compu {0=Cx0_Init (CM_RGB_Slave_06_LedBlauStg_Cx0_Init), 1=Cx1_nicht_erlaubt (CM_RGB_Slave_06_LedBlauStg_Cx1_nicht_erlaubt), 2=Cx2_kein_Fehler (CM_RGB_Slave_06_LedBlauStg_Cx2_kein_Fehler), 3=Cx3_Fehler (CM_RGB_Slave_06_LedBlauStg_Cx3_Fehler)}, range raw 0..3, transfer-property=PENDING, to SAM(timeout 3.5 s)  # Short To Ground für Blaue LED
            signal RGB_Slave_06_LedRotOl_XIX_RGBs_Slave_06_XIX_E3V_SAM_LIN9: start 14, 2 bit, little-endian, data-type-policy=OVERRIDE, i-signal-type=PRIMITIVE, init-value=0, base-type=BT_RGB_Slave_06_LedRotOl, invalid-value=Invalid_RGB_Slave_06_LedRotOl_XIX_RGBs_Slave_06_XIX_E3V_SAM_LIN9:3, compu {0=Cx0_Init (CM_RGB_Slave_06_LedRotOl_Cx0_Init), 1=Cx1_nicht_erlaubt (CM_RGB_Slave_06_LedRotOl_Cx1_nicht_erlaubt), 2=Cx2_kein_Fehler (CM_RGB_Slave_06_LedRotOl_Cx2_kein_Fehler), 3=Cx3_Fehler (CM_RGB_Slave_06_LedRotOl_Cx3_Fehler)}, range raw 0..3, transfer-property=PENDING, to SAM(timeout 3.5 s)  # OpenLoad für Rote LED
            signal RGB_Slave_06_LedGruenOl_XIX_RGBs_Slave_06_XIX_E3V_SAM_LIN9: start 16, 2 bit, little-endian, data-type-policy=OVERRIDE, i-signal-type=PRIMITIVE, init-value=0, base-type=BT_RGB_Slave_06_LedGruenOl, invalid-value=Invalid_RGB_Slave_06_LedGruenOl_XIX_RGBs_Slave_06_XIX_E3V_SAM_LIN9:3, compu {0=Cx0_Init (CM_RGB_Slave_06_LedGruenOl_Cx0_Init), 1=Cx1_nicht_erlaubt (CM_RGB_Slave_06_LedGruenOl_Cx1_nicht_erlaubt), 2=Cx2_kein_Fehler (CM_RGB_Slave_06_LedGruenOl_Cx2_kein_Fehler), 3=Cx3_Fehler (CM_RGB_Slave_06_LedGruenOl_Cx3_Fehler)}, range raw 0..3, transfer-property=PENDING, to SAM(timeout 3.5 s)  # OpenLoad für Rote LED
            signal RGB_Slave_06_LedBlauOl_XIX_RGBs_Slave_06_XIX_E3V_SAM_LIN9: start 18, 2 bit, little-endian, data-type-policy=OVERRIDE, i-signal-type=PRIMITIVE, init-value=0, base-type=BT_RGB_Slave_06_LedBlauOl, invalid-value=Invalid_RGB_Slave_06_LedBlauOl_XIX_RGBs_Slave_06_XIX_E3V_SAM_LIN9:3, compu {0=Cx0_Init (CM_RGB_Slave_06_LedBlauOl_Cx0_Init), 1=Cx1_nicht_erlaubt (CM_RGB_Slave_06_LedBlauOl_Cx1_nicht_erlaubt), 2=Cx2_kein_Fehler (CM_RGB_Slave_06_LedBlauOl_Cx2_kein_Fehler), 3=Cx3_Fehler (CM_RGB_Slave_06_LedBlauOl_Cx3_Fehler)}, range raw 0..3, transfer-property=PENDING, to SAM(timeout 3.5 s)  # OpenLoad für Blaue LED
            signal RGB_Slave_06_TempState_XIX_RGBs_Slave_06_XIX_E3V_SAM_LIN9: start 20, 3 bit, little-endian, data-type-policy=OVERRIDE, i-signal-type=PRIMITIVE, base-type=BT_RGB_Slave_06_TempState, compu {0=Cx0_keine_Temperaturregelung (CM_RGB_Slave_06_TempState_Cx0_keine_Temperaturregelung), 1=Cx1_Regelstufe_1 (CM_RGB_Slave_06_TempState_Cx1_Regelstufe_1), 2=Cx2_Regelstufe_2 (CM_RGB_Slave_06_TempState_Cx2_Regelstufe_2), 3=Cx3_Regelstufe_3 (CM_RGB_Slave_06_TempState_Cx3_Regelstufe_3), 4=Cx4_Regelstufe_4 (CM_RGB_Slave_06_TempState_Cx4_Regelstufe_4), 5=Cx5_Regelstufe_5 (CM_RGB_Slave_06_TempState_Cx5_Regelstufe_5), 6=Cx6_Regelstufe_6 (CM_RGB_Slave_06_TempState_Cx6_Regelstufe_6), 7=Cx7_Regelstufe_7 (CM_RGB_Slave_06_TempState_Cx7_Regelstufe_7)}, range raw 0..7, transfer-property=PENDING, to SAM(timeout 3.5 s)  # Status Temperaturregelung
            signal RGB_Slave_06_IntErrorRam_XIX_RGBs_Slave_06_XIX_E3V_SAM_LIN9: start 24, 2 bit, little-endian, data-type-policy=OVERRIDE, i-signal-type=PRIMITIVE, init-value=0, base-type=BT_RGB_Slave_06_IntErrorRam, invalid-value=Invalid_RGB_Slave_06_IntErrorRam_XIX_RGBs_Slave_06_XIX_E3V_SAM_LIN9:3, compu {0=Cx0_Init (CM_RGB_Slave_06_IntErrorRam_Cx0_Init), 1=Cx1_nicht_erlaubt (CM_RGB_Slave_06_IntErrorRam_Cx1_nicht_erlaubt), 2=Cx2_kein_Fehler (CM_RGB_Slave_06_IntErrorRam_Cx2_kein_Fehler), 3=Cx3_Fehler (CM_RGB_Slave_06_IntErrorRam_Cx3_Fehler)}, range raw 0..3, transfer-property=PENDING, to SAM(timeout 3.5 s)  # Fehler im RAM
            signal RGB_Slave_06_IntErrorRom_XIX_RGBs_Slave_06_XIX_E3V_SAM_LIN9: start 26, 2 bit, little-endian, data-type-policy=OVERRIDE, i-signal-type=PRIMITIVE, init-value=0, base-type=BT_RGB_Slave_06_IntErrorRom, invalid-value=Invalid_RGB_Slave_06_IntErrorRom_XIX_RGBs_Slave_06_XIX_E3V_SAM_LIN9:3, compu {0=Cx0_Init (CM_RGB_Slave_06_IntErrorRom_Cx0_Init), 1=Cx1_nicht_erlaubt (CM_RGB_Slave_06_IntErrorRom_Cx1_nicht_erlaubt), 2=Cx2_kein_Fehler (CM_RGB_Slave_06_IntErrorRom_Cx2_kein_Fehler), 3=Cx3_Fehler (CM_RGB_Slave_06_IntErrorRom_Cx3_Fehler)}, range raw 0..3, transfer-property=PENDING, to SAM(timeout 3.5 s)  # Fehler im ROM
            signal RGB_Slave_06_IntErrorNvm_XIX_RGBs_Slave_06_XIX_E3V_SAM_LIN9: start 28, 2 bit, little-endian, data-type-policy=OVERRIDE, i-signal-type=PRIMITIVE, init-value=0, base-type=BT_RGB_Slave_06_IntErrorNvm, invalid-value=Invalid_RGB_Slave_06_IntErrorNvm_XIX_RGBs_Slave_06_XIX_E3V_SAM_LIN9:3, compu {0=Cx0_Init (CM_RGB_Slave_06_IntErrorNvm_Cx0_Init), 1=Cx1_nicht_erlaubt (CM_RGB_Slave_06_IntErrorNvm_Cx1_nicht_erlaubt), 2=Cx2_kein_Fehler (CM_RGB_Slave_06_IntErrorNvm_Cx2_kein_Fehler), 3=Cx3_Fehler (CM_RGB_Slave_06_IntErrorNvm_Cx3_Fehler)}, range raw 0..3, transfer-property=PENDING, to SAM(timeout 3.5 s)  # Fehler im NVM
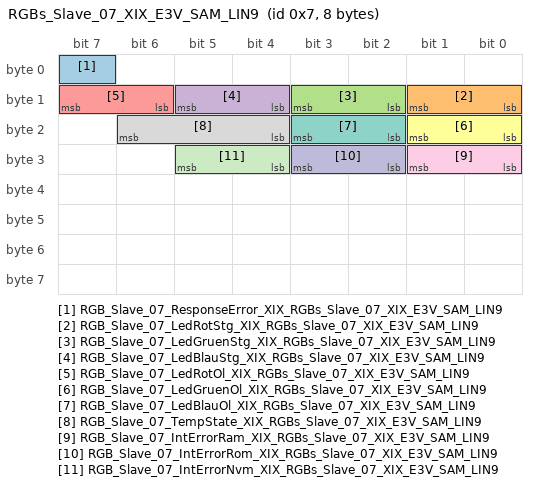
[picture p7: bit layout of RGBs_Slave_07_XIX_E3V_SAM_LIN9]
        frame RGBs_Slave_07_XIX_E3V_SAM_LIN9: id 0x7, to SAM, frame-length=8, lin-checksum=ENHANCED
          pdu RGBs_Slave_07_XIX_E3V_SAM_LIN9: length=8, unused-bit-pattern=0
            signal RGB_Slave_07_ResponseError_XIX_RGBs_Slave_07_XIX_E3V_SAM_LIN9: start 7, 1 bit, little-endian, data-type-policy=OVERRIDE, i-signal-type=PRIMITIVE, init-value=0, base-type=BT_RGB_Slave_07_ResponseError, invalid-value=Invalid_RGB_Slave_07_ResponseError_XIX_RGBs_Slave_07_XIX_E3V_SAM_LIN9:1, compu {0=Cx0_normal (CM_RGB_Slave_07_ResponseError_Cx0_normal), 1=Cx1_Fehler (CM_RGB_Slave_07_ResponseError_Cx1_Fehler)}, range raw 0..1, transfer-property=PENDING, to SAM(timeout 3.5 s)  # siehe LIN2.0-Specification (Darf nicht über ein Fehlergueltigkeitsbit abgesichtert werden!)
            signal RGB_Slave_07_LedRotStg_XIX_RGBs_Slave_07_XIX_E3V_SAM_LIN9: start 8, 2 bit, little-endian, data-type-policy=OVERRIDE, i-signal-type=PRIMITIVE, init-value=0, base-type=BT_RGB_Slave_07_LedRotStg, invalid-value=Invalid_RGB_Slave_07_LedRotStg_XIX_RGBs_Slave_07_XIX_E3V_SAM_LIN9:3, compu {0=Cx0_Init (CM_RGB_Slave_07_LedRotStg_Cx0_Init), 1=Cx1_nicht_erlaubt (CM_RGB_Slave_07_LedRotStg_Cx1_nicht_erlaubt), 2=Cx2_kein_Fehler (CM_RGB_Slave_07_LedRotStg_Cx2_kein_Fehler), 3=Cx3_Fehler (CM_RGB_Slave_07_LedRotStg_Cx3_Fehler)}, range raw 0..3, transfer-property=PENDING, to SAM(timeout 3.5 s)  # Short To Ground für Rote LED
            signal RGB_Slave_07_LedGruenStg_XIX_RGBs_Slave_07_XIX_E3V_SAM_LIN9: start 10, 2 bit, little-endian, data-type-policy=OVERRIDE, i-signal-type=PRIMITIVE, init-value=0, base-type=BT_RGB_Slave_07_LedGruenStg, invalid-value=Invalid_RGB_Slave_07_LedGruenStg_XIX_RGBs_Slave_07_XIX_E3V_SAM_LIN9:3, compu {0=Cx0_Init (CM_RGB_Slave_07_LedGruenStg_Cx0_Init), 1=Cx1_nicht_erlaubt (CM_RGB_Slave_07_LedGruenStg_Cx1_nicht_erlaubt), 2=Cx2_kein_Fehler (CM_RGB_Slave_07_LedGruenStg_Cx2_kein_Fehler), 3=Cx3_Fehler (CM_RGB_Slave_07_LedGruenStg_Cx3_Fehler)}, range raw 0..3, transfer-property=PENDING, to SAM(timeout 3.5 s)  # Short To Ground für Grüne LED
            signal RGB_Slave_07_LedBlauStg_XIX_RGBs_Slave_07_XIX_E3V_SAM_LIN9: start 12, 2 bit, little-endian, data-type-policy=OVERRIDE, i-signal-type=PRIMITIVE, init-value=0, base-type=BT_RGB_Slave_07_LedBlauStg, invalid-value=Invalid_RGB_Slave_07_LedBlauStg_XIX_RGBs_Slave_07_XIX_E3V_SAM_LIN9:3, compu {0=Cx0_Init (CM_RGB_Slave_07_LedBlauStg_Cx0_Init), 1=Cx1_nicht_erlaubt (CM_RGB_Slave_07_LedBlauStg_Cx1_nicht_erlaubt), 2=Cx2_kein_Fehler (CM_RGB_Slave_07_LedBlauStg_Cx2_kein_Fehler), 3=Cx3_Fehler (CM_RGB_Slave_07_LedBlauStg_Cx3_Fehler)}, range raw 0..3, transfer-property=PENDING, to SAM(timeout 3.5 s)  # Short To Ground für Blaue LED
            signal RGB_Slave_07_LedRotOl_XIX_RGBs_Slave_07_XIX_E3V_SAM_LIN9: start 14, 2 bit, little-endian, data-type-policy=OVERRIDE, i-signal-type=PRIMITIVE, init-value=0, base-type=BT_RGB_Slave_07_LedRotOl, invalid-value=Invalid_RGB_Slave_07_LedRotOl_XIX_RGBs_Slave_07_XIX_E3V_SAM_LIN9:3, compu {0=Cx0_Init (CM_RGB_Slave_07_LedRotOl_Cx0_Init), 1=Cx1_nicht_erlaubt (CM_RGB_Slave_07_LedRotOl_Cx1_nicht_erlaubt), 2=Cx2_kein_Fehler (CM_RGB_Slave_07_LedRotOl_Cx2_kein_Fehler), 3=Cx3_Fehler (CM_RGB_Slave_07_LedRotOl_Cx3_Fehler)}, range raw 0..3, transfer-property=PENDING, to SAM(timeout 3.5 s)  # OpenLoad für Rote LED
            signal RGB_Slave_07_LedGruenOl_XIX_RGBs_Slave_07_XIX_E3V_SAM_LIN9: start 16, 2 bit, little-endian, data-type-policy=OVERRIDE, i-signal-type=PRIMITIVE, init-value=0, base-type=BT_RGB_Slave_07_LedGruenOl, invalid-value=Invalid_RGB_Slave_07_LedGruenOl_XIX_RGBs_Slave_07_XIX_E3V_SAM_LIN9:3, compu {0=Cx0_Init (CM_RGB_Slave_07_LedGruenOl_Cx0_Init), 1=Cx1_nicht_erlaubt (CM_RGB_Slave_07_LedGruenOl_Cx1_nicht_erlaubt), 2=Cx2_kein_Fehler (CM_RGB_Slave_07_LedGruenOl_Cx2_kein_Fehler), 3=Cx3_Fehler (CM_RGB_Slave_07_LedGruenOl_Cx3_Fehler)}, range raw 0..3, transfer-property=PENDING, to SAM(timeout 3.5 s)  # OpenLoad für Rote LED
            signal RGB_Slave_07_LedBlauOl_XIX_RGBs_Slave_07_XIX_E3V_SAM_LIN9: start 18, 2 bit, little-endian, data-type-policy=OVERRIDE, i-signal-type=PRIMITIVE, init-value=0, base-type=BT_RGB_Slave_07_LedBlauOl, invalid-value=Invalid_RGB_Slave_07_LedBlauOl_XIX_RGBs_Slave_07_XIX_E3V_SAM_LIN9:3, compu {0=Cx0_Init (CM_RGB_Slave_07_LedBlauOl_Cx0_Init), 1=Cx1_nicht_erlaubt (CM_RGB_Slave_07_LedBlauOl_Cx1_nicht_erlaubt), 2=Cx2_kein_Fehler (CM_RGB_Slave_07_LedBlauOl_Cx2_kein_Fehler), 3=Cx3_Fehler (CM_RGB_Slave_07_LedBlauOl_Cx3_Fehler)}, range raw 0..3, transfer-property=PENDING, to SAM(timeout 3.5 s)  # OpenLoad für Blaue LED
            signal RGB_Slave_07_TempState_XIX_RGBs_Slave_07_XIX_E3V_SAM_LIN9: start 20, 3 bit, little-endian, data-type-policy=OVERRIDE, i-signal-type=PRIMITIVE, base-type=BT_RGB_Slave_07_TempState, compu {0=Cx0_keine_Temperaturregelung (CM_RGB_Slave_07_TempState_Cx0_keine_Temperaturregelung), 1=Cx1_Regelstufe_1 (CM_RGB_Slave_07_TempState_Cx1_Regelstufe_1), 2=Cx2_Regelstufe_2 (CM_RGB_Slave_07_TempState_Cx2_Regelstufe_2), 3=Cx3_Regelstufe_3 (CM_RGB_Slave_07_TempState_Cx3_Regelstufe_3), 4=Cx4_Regelstufe_4 (CM_RGB_Slave_07_TempState_Cx4_Regelstufe_4), 5=Cx5_Regelstufe_5 (CM_RGB_Slave_07_TempState_Cx5_Regelstufe_5), 6=Cx6_Regelstufe_6 (CM_RGB_Slave_07_TempState_Cx6_Regelstufe_6), 7=Cx7_Regelstufe_7 (CM_RGB_Slave_07_TempState_Cx7_Regelstufe_7)}, range raw 0..7, transfer-property=PENDING, to SAM(timeout 3.5 s)  # Status Temperaturregelung
            signal RGB_Slave_07_IntErrorRam_XIX_RGBs_Slave_07_XIX_E3V_SAM_LIN9: start 24, 2 bit, little-endian, data-type-policy=OVERRIDE, i-signal-type=PRIMITIVE, init-value=0, base-type=BT_RGB_Slave_07_IntErrorRam, invalid-value=Invalid_RGB_Slave_07_IntErrorRam_XIX_RGBs_Slave_07_XIX_E3V_SAM_LIN9:3, compu {0=Cx0_Init (CM_RGB_Slave_07_IntErrorRam_Cx0_Init), 1=Cx1_nicht_erlaubt (CM_RGB_Slave_07_IntErrorRam_Cx1_nicht_erlaubt), 2=Cx2_kein_Fehler (CM_RGB_Slave_07_IntErrorRam_Cx2_kein_Fehler), 3=Cx3_Fehler (CM_RGB_Slave_07_IntErrorRam_Cx3_Fehler)}, range raw 0..3, transfer-property=PENDING, to SAM(timeout 3.5 s)  # Fehler im RAM
            signal RGB_Slave_07_IntErrorRom_XIX_RGBs_Slave_07_XIX_E3V_SAM_LIN9: start 26, 2 bit, little-endian, data-type-policy=OVERRIDE, i-signal-type=PRIMITIVE, init-value=0, base-type=BT_RGB_Slave_07_IntErrorRom, invalid-value=Invalid_RGB_Slave_07_IntErrorRom_XIX_RGBs_Slave_07_XIX_E3V_SAM_LIN9:3, compu {0=Cx0_Init (CM_RGB_Slave_07_IntErrorRom_Cx0_Init), 1=Cx1_nicht_erlaubt (CM_RGB_Slave_07_IntErrorRom_Cx1_nicht_erlaubt), 2=Cx2_kein_Fehler (CM_RGB_Slave_07_IntErrorRom_Cx2_kein_Fehler), 3=Cx3_Fehler (CM_RGB_Slave_07_IntErrorRom_Cx3_Fehler)}, range raw 0..3, transfer-property=PENDING, to SAM(timeout 3.5 s)  # Fehler im ROM
            signal RGB_Slave_07_IntErrorNvm_XIX_RGBs_Slave_07_XIX_E3V_SAM_LIN9: start 28, 2 bit, little-endian, data-type-policy=OVERRIDE, i-signal-type=PRIMITIVE, init-value=0, base-type=BT_RGB_Slave_07_IntErrorNvm, invalid-value=Invalid_RGB_Slave_07_IntErrorNvm_XIX_RGBs_Slave_07_XIX_E3V_SAM_LIN9:3, compu {0=Cx0_Init (CM_RGB_Slave_07_IntErrorNvm_Cx0_Init), 1=Cx1_nicht_erlaubt (CM_RGB_Slave_07_IntErrorNvm_Cx1_nicht_erlaubt), 2=Cx2_kein_Fehler (CM_RGB_Slave_07_IntErrorNvm_Cx2_kein_Fehler), 3=Cx3_Fehler (CM_RGB_Slave_07_IntErrorNvm_Cx3_Fehler)}, range raw 0..3, transfer-property=PENDING, to SAM(timeout 3.5 s)  # Fehler im NVM
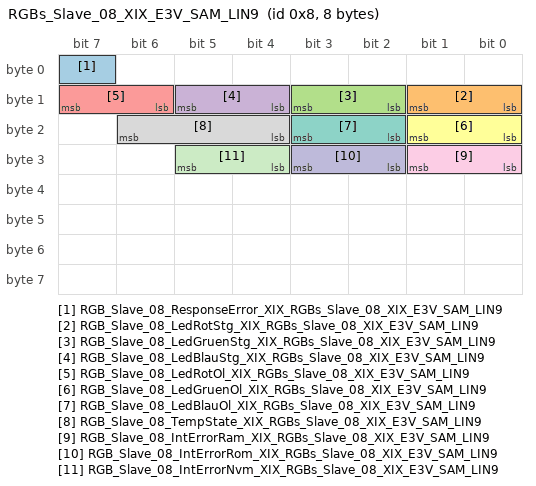
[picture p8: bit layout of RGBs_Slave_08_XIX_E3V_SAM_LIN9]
        frame RGBs_Slave_08_XIX_E3V_SAM_LIN9: id 0x8, to SAM, frame-length=8, lin-checksum=ENHANCED
          pdu RGBs_Slave_08_XIX_E3V_SAM_LIN9: length=8, unused-bit-pattern=0
            signal RGB_Slave_08_ResponseError_XIX_RGBs_Slave_08_XIX_E3V_SAM_LIN9: start 7, 1 bit, little-endian, data-type-policy=OVERRIDE, i-signal-type=PRIMITIVE, init-value=0, base-type=BT_RGB_Slave_08_ResponseError, invalid-value=Invalid_RGB_Slave_08_ResponseError_XIX_RGBs_Slave_08_XIX_E3V_SAM_LIN9:1, compu {0=Cx0_normal (CM_RGB_Slave_08_ResponseError_Cx0_normal), 1=Cx1_Fehler (CM_RGB_Slave_08_ResponseError_Cx1_Fehler)}, range raw 0..1, transfer-property=PENDING, to SAM(timeout 3.5 s)  # siehe LIN2.0-Specification (Darf nicht über ein Fehlergueltigkeitsbit abgesichtert werden!)
            signal RGB_Slave_08_LedRotStg_XIX_RGBs_Slave_08_XIX_E3V_SAM_LIN9: start 8, 2 bit, little-endian, data-type-policy=OVERRIDE, i-signal-type=PRIMITIVE, init-value=0, base-type=BT_RGB_Slave_08_LedRotStg, invalid-value=Invalid_RGB_Slave_08_LedRotStg_XIX_RGBs_Slave_08_XIX_E3V_SAM_LIN9:3, compu {0=Cx0_Init (CM_RGB_Slave_08_LedRotStg_Cx0_Init), 1=Cx1_nicht_erlaubt (CM_RGB_Slave_08_LedRotStg_Cx1_nicht_erlaubt), 2=Cx2_kein_Fehler (CM_RGB_Slave_08_LedRotStg_Cx2_kein_Fehler), 3=Cx3_Fehler (CM_RGB_Slave_08_LedRotStg_Cx3_Fehler)}, range raw 0..3, transfer-property=PENDING, to SAM(timeout 3.5 s)  # Short To Ground für Rote LED
            signal RGB_Slave_08_LedGruenStg_XIX_RGBs_Slave_08_XIX_E3V_SAM_LIN9: start 10, 2 bit, little-endian, data-type-policy=OVERRIDE, i-signal-type=PRIMITIVE, init-value=0, base-type=BT_RGB_Slave_08_LedGruenStg, invalid-value=Invalid_RGB_Slave_08_LedGruenStg_XIX_RGBs_Slave_08_XIX_E3V_SAM_LIN9:3, compu {0=Cx0_Init (CM_RGB_Slave_08_LedGruenStg_Cx0_Init), 1=Cx1_nicht_erlaubt (CM_RGB_Slave_08_LedGruenStg_Cx1_nicht_erlaubt), 2=Cx2_kein_Fehler (CM_RGB_Slave_08_LedGruenStg_Cx2_kein_Fehler), 3=Cx3_Fehler (CM_RGB_Slave_08_LedGruenStg_Cx3_Fehler)}, range raw 0..3, transfer-property=PENDING, to SAM(timeout 3.5 s)  # Short To Ground für Grüne LED
            signal RGB_Slave_08_LedBlauStg_XIX_RGBs_Slave_08_XIX_E3V_SAM_LIN9: start 12, 2 bit, little-endian, data-type-policy=OVERRIDE, i-signal-type=PRIMITIVE, init-value=0, base-type=BT_RGB_Slave_08_LedBlauStg, invalid-value=Invalid_RGB_Slave_08_LedBlauStg_XIX_RGBs_Slave_08_XIX_E3V_SAM_LIN9:3, compu {0=Cx0_Init (CM_RGB_Slave_08_LedBlauStg_Cx0_Init), 1=Cx1_nicht_erlaubt (CM_RGB_Slave_08_LedBlauStg_Cx1_nicht_erlaubt), 2=Cx2_kein_Fehler (CM_RGB_Slave_08_LedBlauStg_Cx2_kein_Fehler), 3=Cx3_Fehler (CM_RGB_Slave_08_LedBlauStg_Cx3_Fehler)}, range raw 0..3, transfer-property=PENDING, to SAM(timeout 3.5 s)  # Short To Ground für Blaue LED
            signal RGB_Slave_08_LedRotOl_XIX_RGBs_Slave_08_XIX_E3V_SAM_LIN9: start 14, 2 bit, little-endian, data-type-policy=OVERRIDE, i-signal-type=PRIMITIVE, init-value=0, base-type=BT_RGB_Slave_08_LedRotOl, invalid-value=Invalid_RGB_Slave_08_LedRotOl_XIX_RGBs_Slave_08_XIX_E3V_SAM_LIN9:3, compu {0=Cx0_Init (CM_RGB_Slave_08_LedRotOl_Cx0_Init), 1=Cx1_nicht_erlaubt (CM_RGB_Slave_08_LedRotOl_Cx1_nicht_erlaubt), 2=Cx2_kein_Fehler (CM_RGB_Slave_08_LedRotOl_Cx2_kein_Fehler), 3=Cx3_Fehler (CM_RGB_Slave_08_LedRotOl_Cx3_Fehler)}, range raw 0..3, transfer-property=PENDING, to SAM(timeout 3.5 s)  # OpenLoad für Rote LED
            signal RGB_Slave_08_LedGruenOl_XIX_RGBs_Slave_08_XIX_E3V_SAM_LIN9: start 16, 2 bit, little-endian, data-type-policy=OVERRIDE, i-signal-type=PRIMITIVE, init-value=0, base-type=BT_RGB_Slave_08_LedGruenOl, invalid-value=Invalid_RGB_Slave_08_LedGruenOl_XIX_RGBs_Slave_08_XIX_E3V_SAM_LIN9:3, compu {0=Cx0_Init (CM_RGB_Slave_08_LedGruenOl_Cx0_Init), 1=Cx1_nicht_erlaubt (CM_RGB_Slave_08_LedGruenOl_Cx1_nicht_erlaubt), 2=Cx2_kein_Fehler (CM_RGB_Slave_08_LedGruenOl_Cx2_kein_Fehler), 3=Cx3_Fehler (CM_RGB_Slave_08_LedGruenOl_Cx3_Fehler)}, range raw 0..3, transfer-property=PENDING, to SAM(timeout 3.5 s)  # OpenLoad für Rote LED
            signal RGB_Slave_08_LedBlauOl_XIX_RGBs_Slave_08_XIX_E3V_SAM_LIN9: start 18, 2 bit, little-endian, data-type-policy=OVERRIDE, i-signal-type=PRIMITIVE, init-value=0, base-type=BT_RGB_Slave_08_LedBlauOl, invalid-value=Invalid_RGB_Slave_08_LedBlauOl_XIX_RGBs_Slave_08_XIX_E3V_SAM_LIN9:3, compu {0=Cx0_Init (CM_RGB_Slave_08_LedBlauOl_Cx0_Init), 1=Cx1_nicht_erlaubt (CM_RGB_Slave_08_LedBlauOl_Cx1_nicht_erlaubt), 2=Cx2_kein_Fehler (CM_RGB_Slave_08_LedBlauOl_Cx2_kein_Fehler), 3=Cx3_Fehler (CM_RGB_Slave_08_LedBlauOl_Cx3_Fehler)}, range raw 0..3, transfer-property=PENDING, to SAM(timeout 3.5 s)  # OpenLoad für Blaue LED
            signal RGB_Slave_08_TempState_XIX_RGBs_Slave_08_XIX_E3V_SAM_LIN9: start 20, 3 bit, little-endian, data-type-policy=OVERRIDE, i-signal-type=PRIMITIVE, base-type=BT_RGB_Slave_08_TempState, compu {0=Cx0_keine_Temperaturregelung (CM_RGB_Slave_08_TempState_Cx0_keine_Temperaturregelung), 1=Cx1_Regelstufe_1 (CM_RGB_Slave_08_TempState_Cx1_Regelstufe_1), 2=Cx2_Regelstufe_2 (CM_RGB_Slave_08_TempState_Cx2_Regelstufe_2), 3=Cx3_Regelstufe_3 (CM_RGB_Slave_08_TempState_Cx3_Regelstufe_3), 4=Cx4_Regelstufe_4 (CM_RGB_Slave_08_TempState_Cx4_Regelstufe_4), 5=Cx5_Regelstufe_5 (CM_RGB_Slave_08_TempState_Cx5_Regelstufe_5), 6=Cx6_Regelstufe_6 (CM_RGB_Slave_08_TempState_Cx6_Regelstufe_6), 7=Cx7_Regelstufe_7 (CM_RGB_Slave_08_TempState_Cx7_Regelstufe_7)}, range raw 0..7, transfer-property=PENDING, to SAM(timeout 3.5 s)  # Status Temperaturregelung
            signal RGB_Slave_08_IntErrorRam_XIX_RGBs_Slave_08_XIX_E3V_SAM_LIN9: start 24, 2 bit, little-endian, data-type-policy=OVERRIDE, i-signal-type=PRIMITIVE, init-value=0, base-type=BT_RGB_Slave_08_IntErrorRam, invalid-value=Invalid_RGB_Slave_08_IntErrorRam_XIX_RGBs_Slave_08_XIX_E3V_SAM_LIN9:3, compu {0=Cx0_Init (CM_RGB_Slave_08_IntErrorRam_Cx0_Init), 1=Cx1_nicht_erlaubt (CM_RGB_Slave_08_IntErrorRam_Cx1_nicht_erlaubt), 2=Cx2_kein_Fehler (CM_RGB_Slave_08_IntErrorRam_Cx2_kein_Fehler), 3=Cx3_Fehler (CM_RGB_Slave_08_IntErrorRam_Cx3_Fehler)}, range raw 0..3, transfer-property=PENDING, to SAM(timeout 3.5 s)  # Fehler im RAM
            signal RGB_Slave_08_IntErrorRom_XIX_RGBs_Slave_08_XIX_E3V_SAM_LIN9: start 26, 2 bit, little-endian, data-type-policy=OVERRIDE, i-signal-type=PRIMITIVE, init-value=0, base-type=BT_RGB_Slave_08_IntErrorRom, invalid-value=Invalid_RGB_Slave_08_IntErrorRom_XIX_RGBs_Slave_08_XIX_E3V_SAM_LIN9:3, compu {0=Cx0_Init (CM_RGB_Slave_08_IntErrorRom_Cx0_Init), 1=Cx1_nicht_erlaubt (CM_RGB_Slave_08_IntErrorRom_Cx1_nicht_erlaubt), 2=Cx2_kein_Fehler (CM_RGB_Slave_08_IntErrorRom_Cx2_kein_Fehler), 3=Cx3_Fehler (CM_RGB_Slave_08_IntErrorRom_Cx3_Fehler)}, range raw 0..3, transfer-property=PENDING, to SAM(timeout 3.5 s)  # Fehler im ROM
            signal RGB_Slave_08_IntErrorNvm_XIX_RGBs_Slave_08_XIX_E3V_SAM_LIN9: start 28, 2 bit, little-endian, data-type-policy=OVERRIDE, i-signal-type=PRIMITIVE, init-value=0, base-type=BT_RGB_Slave_08_IntErrorNvm, invalid-value=Invalid_RGB_Slave_08_IntErrorNvm_XIX_RGBs_Slave_08_XIX_E3V_SAM_LIN9:3, compu {0=Cx0_Init (CM_RGB_Slave_08_IntErrorNvm_Cx0_Init), 1=Cx1_nicht_erlaubt (CM_RGB_Slave_08_IntErrorNvm_Cx1_nicht_erlaubt), 2=Cx2_kein_Fehler (CM_RGB_Slave_08_IntErrorNvm_Cx2_kein_Fehler), 3=Cx3_Fehler (CM_RGB_Slave_08_IntErrorNvm_Cx3_Fehler)}, range raw 0..3, transfer-property=PENDING, to SAM(timeout 3.5 s)  # Fehler im NVM
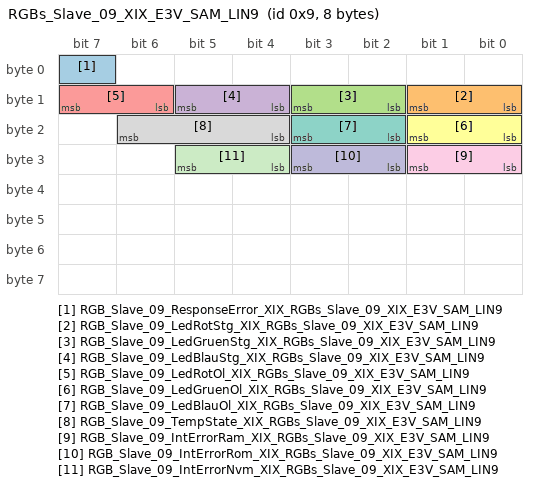
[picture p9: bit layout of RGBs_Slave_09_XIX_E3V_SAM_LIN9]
        frame RGBs_Slave_09_XIX_E3V_SAM_LIN9: id 0x9, to SAM, frame-length=8, lin-checksum=ENHANCED
          pdu RGBs_Slave_09_XIX_E3V_SAM_LIN9: length=8, unused-bit-pattern=0
            signal RGB_Slave_09_ResponseError_XIX_RGBs_Slave_09_XIX_E3V_SAM_LIN9: start 7, 1 bit, little-endian, data-type-policy=OVERRIDE, i-signal-type=PRIMITIVE, init-value=0, base-type=BT_RGB_Slave_09_ResponseError, invalid-value=Invalid_RGB_Slave_09_ResponseError_XIX_RGBs_Slave_09_XIX_E3V_SAM_LIN9:1, compu {0=Cx0_normal (CM_RGB_Slave_09_ResponseError_Cx0_normal), 1=Cx1_Fehler (CM_RGB_Slave_09_ResponseError_Cx1_Fehler)}, range raw 0..1, transfer-property=PENDING, to SAM(timeout 3.5 s)  # siehe LIN2.0-Specification (Darf nicht über ein Fehlergueltigkeitsbit abgesichtert werden!)
            signal RGB_Slave_09_LedRotStg_XIX_RGBs_Slave_09_XIX_E3V_SAM_LIN9: start 8, 2 bit, little-endian, data-type-policy=OVERRIDE, i-signal-type=PRIMITIVE, init-value=0, base-type=BT_RGB_Slave_09_LedRotStg, invalid-value=Invalid_RGB_Slave_09_LedRotStg_XIX_RGBs_Slave_09_XIX_E3V_SAM_LIN9:3, compu {0=Cx0_Init (CM_RGB_Slave_09_LedRotStg_Cx0_Init), 1=Cx1_nicht_erlaubt (CM_RGB_Slave_09_LedRotStg_Cx1_nicht_erlaubt), 2=Cx2_kein_Fehler (CM_RGB_Slave_09_LedRotStg_Cx2_kein_Fehler), 3=Cx3_Fehler (CM_RGB_Slave_09_LedRotStg_Cx3_Fehler)}, range raw 0..3, transfer-property=PENDING, to SAM(timeout 3.5 s)  # Short To Ground für Rote LED
            signal RGB_Slave_09_LedGruenStg_XIX_RGBs_Slave_09_XIX_E3V_SAM_LIN9: start 10, 2 bit, little-endian, data-type-policy=OVERRIDE, i-signal-type=PRIMITIVE, init-value=0, base-type=BT_RGB_Slave_09_LedGruenStg, invalid-value=Invalid_RGB_Slave_09_LedGruenStg_XIX_RGBs_Slave_09_XIX_E3V_SAM_LIN9:3, compu {0=Cx0_Init (CM_RGB_Slave_09_LedGruenStg_Cx0_Init), 1=Cx1_nicht_erlaubt (CM_RGB_Slave_09_LedGruenStg_Cx1_nicht_erlaubt), 2=Cx2_kein_Fehler (CM_RGB_Slave_09_LedGruenStg_Cx2_kein_Fehler), 3=Cx3_Fehler (CM_RGB_Slave_09_LedGruenStg_Cx3_Fehler)}, range raw 0..3, transfer-property=PENDING, to SAM(timeout 3.5 s)  # Short To Ground für Grüne LED
            signal RGB_Slave_09_LedBlauStg_XIX_RGBs_Slave_09_XIX_E3V_SAM_LIN9: start 12, 2 bit, little-endian, data-type-policy=OVERRIDE, i-signal-type=PRIMITIVE, init-value=0, base-type=BT_RGB_Slave_09_LedBlauStg, invalid-value=Invalid_RGB_Slave_09_LedBlauStg_XIX_RGBs_Slave_09_XIX_E3V_SAM_LIN9:3, compu {0=Cx0_Init (CM_RGB_Slave_09_LedBlauStg_Cx0_Init), 1=Cx1_nicht_erlaubt (CM_RGB_Slave_09_LedBlauStg_Cx1_nicht_erlaubt), 2=Cx2_kein_Fehler (CM_RGB_Slave_09_LedBlauStg_Cx2_kein_Fehler), 3=Cx3_Fehler (CM_RGB_Slave_09_LedBlauStg_Cx3_Fehler)}, range raw 0..3, transfer-property=PENDING, to SAM(timeout 3.5 s)  # Short To Ground für Blaue LED
            signal RGB_Slave_09_LedRotOl_XIX_RGBs_Slave_09_XIX_E3V_SAM_LIN9: start 14, 2 bit, little-endian, data-type-policy=OVERRIDE, i-signal-type=PRIMITIVE, init-value=0, base-type=BT_RGB_Slave_09_LedRotOl, invalid-value=Invalid_RGB_Slave_09_LedRotOl_XIX_RGBs_Slave_09_XIX_E3V_SAM_LIN9:3, compu {0=Cx0_Init (CM_RGB_Slave_09_LedRotOl_Cx0_Init), 1=Cx1_nicht_erlaubt (CM_RGB_Slave_09_LedRotOl_Cx1_nicht_erlaubt), 2=Cx2_kein_Fehler (CM_RGB_Slave_09_LedRotOl_Cx2_kein_Fehler), 3=Cx3_Fehler (CM_RGB_Slave_09_LedRotOl_Cx3_Fehler)}, range raw 0..3, transfer-property=PENDING, to SAM(timeout 3.5 s)  # OpenLoad für Rote LED
            signal RGB_Slave_09_LedGruenOl_XIX_RGBs_Slave_09_XIX_E3V_SAM_LIN9: start 16, 2 bit, little-endian, data-type-policy=OVERRIDE, i-signal-type=PRIMITIVE, init-value=0, base-type=BT_RGB_Slave_09_LedGruenOl, invalid-value=Invalid_RGB_Slave_09_LedGruenOl_XIX_RGBs_Slave_09_XIX_E3V_SAM_LIN9:3, compu {0=Cx0_Init (CM_RGB_Slave_09_LedGruenOl_Cx0_Init), 1=Cx1_nicht_erlaubt (CM_RGB_Slave_09_LedGruenOl_Cx1_nicht_erlaubt), 2=Cx2_kein_Fehler (CM_RGB_Slave_09_LedGruenOl_Cx2_kein_Fehler), 3=Cx3_Fehler (CM_RGB_Slave_09_LedGruenOl_Cx3_Fehler)}, range raw 0..3, transfer-property=PENDING, to SAM(timeout 3.5 s)  # OpenLoad für Rote LED
            signal RGB_Slave_09_LedBlauOl_XIX_RGBs_Slave_09_XIX_E3V_SAM_LIN9: start 18, 2 bit, little-endian, data-type-policy=OVERRIDE, i-signal-type=PRIMITIVE, init-value=0, base-type=BT_RGB_Slave_09_LedBlauOl, invalid-value=Invalid_RGB_Slave_09_LedBlauOl_XIX_RGBs_Slave_09_XIX_E3V_SAM_LIN9:3, compu {0=Cx0_Init (CM_RGB_Slave_09_LedBlauOl_Cx0_Init), 1=Cx1_nicht_erlaubt (CM_RGB_Slave_09_LedBlauOl_Cx1_nicht_erlaubt), 2=Cx2_kein_Fehler (CM_RGB_Slave_09_LedBlauOl_Cx2_kein_Fehler), 3=Cx3_Fehler (CM_RGB_Slave_09_LedBlauOl_Cx3_Fehler)}, range raw 0..3, transfer-property=PENDING, to SAM(timeout 3.5 s)  # OpenLoad für Blaue LED
            signal RGB_Slave_09_TempState_XIX_RGBs_Slave_09_XIX_E3V_SAM_LIN9: start 20, 3 bit, little-endian, data-type-policy=OVERRIDE, i-signal-type=PRIMITIVE, base-type=BT_RGB_Slave_09_TempState, compu {0=Cx0_keine_Temperaturregelung (CM_RGB_Slave_09_TempState_Cx0_keine_Temperaturregelung), 1=Cx1_Regelstufe_1 (CM_RGB_Slave_09_TempState_Cx1_Regelstufe_1), 2=Cx2_Regelstufe_2 (CM_RGB_Slave_09_TempState_Cx2_Regelstufe_2), 3=Cx3_Regelstufe_3 (CM_RGB_Slave_09_TempState_Cx3_Regelstufe_3), 4=Cx4_Regelstufe_4 (CM_RGB_Slave_09_TempState_Cx4_Regelstufe_4), 5=Cx5_Regelstufe_5 (CM_RGB_Slave_09_TempState_Cx5_Regelstufe_5), 6=Cx6_Regelstufe_6 (CM_RGB_Slave_09_TempState_Cx6_Regelstufe_6), 7=Cx7_Regelstufe_7 (CM_RGB_Slave_09_TempState_Cx7_Regelstufe_7)}, range raw 0..7, transfer-property=PENDING, to SAM(timeout 3.5 s)  # Status Temperaturregelung
            signal RGB_Slave_09_IntErrorRam_XIX_RGBs_Slave_09_XIX_E3V_SAM_LIN9: start 24, 2 bit, little-endian, data-type-policy=OVERRIDE, i-signal-type=PRIMITIVE, init-value=0, base-type=BT_RGB_Slave_09_IntErrorRam, invalid-value=Invalid_RGB_Slave_09_IntErrorRam_XIX_RGBs_Slave_09_XIX_E3V_SAM_LIN9:3, compu {0=Cx0_Init (CM_RGB_Slave_09_IntErrorRam_Cx0_Init), 1=Cx1_nicht_erlaubt (CM_RGB_Slave_09_IntErrorRam_Cx1_nicht_erlaubt), 2=Cx2_kein_Fehler (CM_RGB_Slave_09_IntErrorRam_Cx2_kein_Fehler), 3=Cx3_Fehler (CM_RGB_Slave_09_IntErrorRam_Cx3_Fehler)}, range raw 0..3, transfer-property=PENDING, to SAM(timeout 3.5 s)  # Fehler im RAM
            signal RGB_Slave_09_IntErrorRom_XIX_RGBs_Slave_09_XIX_E3V_SAM_LIN9: start 26, 2 bit, little-endian, data-type-policy=OVERRIDE, i-signal-type=PRIMITIVE, init-value=0, base-type=BT_RGB_Slave_09_IntErrorRom, invalid-value=Invalid_RGB_Slave_09_IntErrorRom_XIX_RGBs_Slave_09_XIX_E3V_SAM_LIN9:3, compu {0=Cx0_Init (CM_RGB_Slave_09_IntErrorRom_Cx0_Init), 1=Cx1_nicht_erlaubt (CM_RGB_Slave_09_IntErrorRom_Cx1_nicht_erlaubt), 2=Cx2_kein_Fehler (CM_RGB_Slave_09_IntErrorRom_Cx2_kein_Fehler), 3=Cx3_Fehler (CM_RGB_Slave_09_IntErrorRom_Cx3_Fehler)}, range raw 0..3, transfer-property=PENDING, to SAM(timeout 3.5 s)  # Fehler im ROM
            signal RGB_Slave_09_IntErrorNvm_XIX_RGBs_Slave_09_XIX_E3V_SAM_LIN9: start 28, 2 bit, little-endian, data-type-policy=OVERRIDE, i-signal-type=PRIMITIVE, init-value=0, base-type=BT_RGB_Slave_09_IntErrorNvm, invalid-value=Invalid_RGB_Slave_09_IntErrorNvm_XIX_RGBs_Slave_09_XIX_E3V_SAM_LIN9:3, compu {0=Cx0_Init (CM_RGB_Slave_09_IntErrorNvm_Cx0_Init), 1=Cx1_nicht_erlaubt (CM_RGB_Slave_09_IntErrorNvm_Cx1_nicht_erlaubt), 2=Cx2_kein_Fehler (CM_RGB_Slave_09_IntErrorNvm_Cx2_kein_Fehler), 3=Cx3_Fehler (CM_RGB_Slave_09_IntErrorNvm_Cx3_Fehler)}, range raw 0..3, transfer-property=PENDING, to SAM(timeout 3.5 s)  # Fehler im NVM
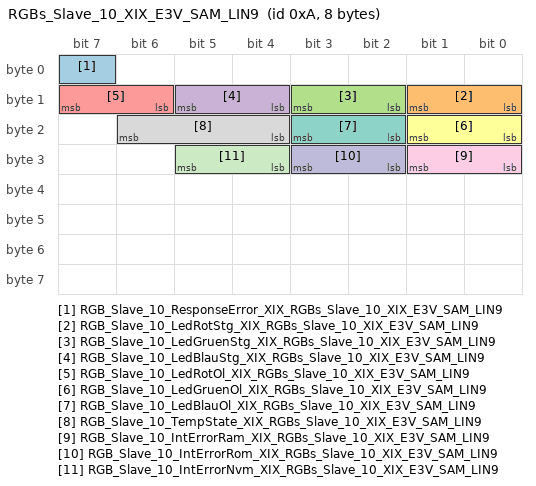
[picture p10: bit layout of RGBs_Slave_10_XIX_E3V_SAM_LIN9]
        frame RGBs_Slave_10_XIX_E3V_SAM_LIN9: id 0xA, to SAM, frame-length=8, lin-checksum=ENHANCED
          pdu RGBs_Slave_10_XIX_E3V_SAM_LIN9: length=8, unused-bit-pattern=0
            signal RGB_Slave_10_ResponseError_XIX_RGBs_Slave_10_XIX_E3V_SAM_LIN9: start 7, 1 bit, little-endian, data-type-policy=OVERRIDE, i-signal-type=PRIMITIVE, init-value=0, base-type=BT_RGB_Slave_10_ResponseError, invalid-value=Invalid_RGB_Slave_10_ResponseError_XIX_RGBs_Slave_10_XIX_E3V_SAM_LIN9:1, compu {0=Cx0_normal (CM_RGB_Slave_10_ResponseError_Cx0_normal), 1=Cx1_Fehler (CM_RGB_Slave_10_ResponseError_Cx1_Fehler)}, range raw 0..1, transfer-property=PENDING, to SAM(timeout 3.5 s)  # siehe LIN2.0-Specification (Darf nicht über ein Fehlergueltigkeitsbit abgesichtert werden!)
            signal RGB_Slave_10_LedRotStg_XIX_RGBs_Slave_10_XIX_E3V_SAM_LIN9: start 8, 2 bit, little-endian, data-type-policy=OVERRIDE, i-signal-type=PRIMITIVE, init-value=0, base-type=BT_RGB_Slave_10_LedRotStg, invalid-value=Invalid_RGB_Slave_10_LedRotStg_XIX_RGBs_Slave_10_XIX_E3V_SAM_LIN9:3, compu {0=Cx0_Init (CM_RGB_Slave_10_LedRotStg_Cx0_Init), 1=Cx1_nicht_erlaubt (CM_RGB_Slave_10_LedRotStg_Cx1_nicht_erlaubt), 2=Cx2_kein_Fehler (CM_RGB_Slave_10_LedRotStg_Cx2_kein_Fehler), 3=Cx3_Fehler (CM_RGB_Slave_10_LedRotStg_Cx3_Fehler)}, range raw 0..3, transfer-property=PENDING, to SAM(timeout 3.5 s)  # Short To Ground für Rote LED
            signal RGB_Slave_10_LedGruenStg_XIX_RGBs_Slave_10_XIX_E3V_SAM_LIN9: start 10, 2 bit, little-endian, data-type-policy=OVERRIDE, i-signal-type=PRIMITIVE, init-value=0, base-type=BT_RGB_Slave_10_LedGruenStg, invalid-value=Invalid_RGB_Slave_10_LedGruenStg_XIX_RGBs_Slave_10_XIX_E3V_SAM_LIN9:3, compu {0=Cx0_Init (CM_RGB_Slave_10_LedGruenStg_Cx0_Init), 1=Cx1_nicht_erlaubt (CM_RGB_Slave_10_LedGruenStg_Cx1_nicht_erlaubt), 2=Cx2_kein_Fehler (CM_RGB_Slave_10_LedGruenStg_Cx2_kein_Fehler), 3=Cx3_Fehler (CM_RGB_Slave_10_LedGruenStg_Cx3_Fehler)}, range raw 0..3, transfer-property=PENDING, to SAM(timeout 3.5 s)  # Short To Ground für Grüne LED
            signal RGB_Slave_10_LedBlauStg_XIX_RGBs_Slave_10_XIX_E3V_SAM_LIN9: start 12, 2 bit, little-endian, data-type-policy=OVERRIDE, i-signal-type=PRIMITIVE, init-value=0, base-type=BT_RGB_Slave_10_LedBlauStg, invalid-value=Invalid_RGB_Slave_10_LedBlauStg_XIX_RGBs_Slave_10_XIX_E3V_SAM_LIN9:3, compu {0=Cx0_Init (CM_RGB_Slave_10_LedBlauStg_Cx0_Init), 1=Cx1_nicht_erlaubt (CM_RGB_Slave_10_LedBlauStg_Cx1_nicht_erlaubt), 2=Cx2_kein_Fehler (CM_RGB_Slave_10_LedBlauStg_Cx2_kein_Fehler), 3=Cx3_Fehler (CM_RGB_Slave_10_LedBlauStg_Cx3_Fehler)}, range raw 0..3, transfer-property=PENDING, to SAM(timeout 3.5 s)  # Short To Ground für Blaue LED
            signal RGB_Slave_10_LedRotOl_XIX_RGBs_Slave_10_XIX_E3V_SAM_LIN9: start 14, 2 bit, little-endian, data-type-policy=OVERRIDE, i-signal-type=PRIMITIVE, init-value=0, base-type=BT_RGB_Slave_10_LedRotOl, invalid-value=Invalid_RGB_Slave_10_LedRotOl_XIX_RGBs_Slave_10_XIX_E3V_SAM_LIN9:3, compu {0=Cx0_Init (CM_RGB_Slave_10_LedRotOl_Cx0_Init), 1=Cx1_nicht_erlaubt (CM_RGB_Slave_10_LedRotOl_Cx1_nicht_erlaubt), 2=Cx2_kein_Fehler (CM_RGB_Slave_10_LedRotOl_Cx2_kein_Fehler), 3=Cx3_Fehler (CM_RGB_Slave_10_LedRotOl_Cx3_Fehler)}, range raw 0..3, transfer-property=PENDING, to SAM(timeout 3.5 s)  # OpenLoad für Rote LED
            signal RGB_Slave_10_LedGruenOl_XIX_RGBs_Slave_10_XIX_E3V_SAM_LIN9: start 16, 2 bit, little-endian, data-type-policy=OVERRIDE, i-signal-type=PRIMITIVE, init-value=0, base-type=BT_RGB_Slave_10_LedGruenOl, invalid-value=Invalid_RGB_Slave_10_LedGruenOl_XIX_RGBs_Slave_10_XIX_E3V_SAM_LIN9:3, compu {0=Cx0_Init (CM_RGB_Slave_10_LedGruenOl_Cx0_Init), 1=Cx1_nicht_erlaubt (CM_RGB_Slave_10_LedGruenOl_Cx1_nicht_erlaubt), 2=Cx2_kein_Fehler (CM_RGB_Slave_10_LedGruenOl_Cx2_kein_Fehler), 3=Cx3_Fehler (CM_RGB_Slave_10_LedGruenOl_Cx3_Fehler)}, range raw 0..3, transfer-property=PENDING, to SAM(timeout 3.5 s)  # OpenLoad für Rote LED
            signal RGB_Slave_10_LedBlauOl_XIX_RGBs_Slave_10_XIX_E3V_SAM_LIN9: start 18, 2 bit, little-endian, data-type-policy=OVERRIDE, i-signal-type=PRIMITIVE, init-value=0, base-type=BT_RGB_Slave_10_LedBlauOl, invalid-value=Invalid_RGB_Slave_10_LedBlauOl_XIX_RGBs_Slave_10_XIX_E3V_SAM_LIN9:3, compu {0=Cx0_Init (CM_RGB_Slave_10_LedBlauOl_Cx0_Init), 1=Cx1_nicht_erlaubt (CM_RGB_Slave_10_LedBlauOl_Cx1_nicht_erlaubt), 2=Cx2_kein_Fehler (CM_RGB_Slave_10_LedBlauOl_Cx2_kein_Fehler), 3=Cx3_Fehler (CM_RGB_Slave_10_LedBlauOl_Cx3_Fehler)}, range raw 0..3, transfer-property=PENDING, to SAM(timeout 3.5 s)  # OpenLoad für Blaue LED
            signal RGB_Slave_10_TempState_XIX_RGBs_Slave_10_XIX_E3V_SAM_LIN9: start 20, 3 bit, little-endian, data-type-policy=OVERRIDE, i-signal-type=PRIMITIVE, base-type=BT_RGB_Slave_10_TempState, compu {0=Cx0_keine_Temperaturregelung (CM_RGB_Slave_10_TempState_Cx0_keine_Temperaturregelung), 1=Cx1_Regelstufe_1 (CM_RGB_Slave_10_TempState_Cx1_Regelstufe_1), 2=Cx2_Regelstufe_2 (CM_RGB_Slave_10_TempState_Cx2_Regelstufe_2), 3=Cx3_Regelstufe_3 (CM_RGB_Slave_10_TempState_Cx3_Regelstufe_3), 4=Cx4_Regelstufe_4 (CM_RGB_Slave_10_TempState_Cx4_Regelstufe_4), 5=Cx5_Regelstufe_5 (CM_RGB_Slave_10_TempState_Cx5_Regelstufe_5), 6=Cx6_Regelstufe_6 (CM_RGB_Slave_10_TempState_Cx6_Regelstufe_6), 7=Cx7_Regelstufe_7 (CM_RGB_Slave_10_TempState_Cx7_Regelstufe_7)}, range raw 0..7, transfer-property=PENDING, to SAM(timeout 3.5 s)  # Status Temperaturregelung
            signal RGB_Slave_10_IntErrorRam_XIX_RGBs_Slave_10_XIX_E3V_SAM_LIN9: start 24, 2 bit, little-endian, data-type-policy=OVERRIDE, i-signal-type=PRIMITIVE, init-value=0, base-type=BT_RGB_Slave_10_IntErrorRam, invalid-value=Invalid_RGB_Slave_10_IntErrorRam_XIX_RGBs_Slave_10_XIX_E3V_SAM_LIN9:3, compu {0=Cx0_Init (CM_RGB_Slave_10_IntErrorRam_Cx0_Init), 1=Cx1_nicht_erlaubt (CM_RGB_Slave_10_IntErrorRam_Cx1_nicht_erlaubt), 2=Cx2_kein_Fehler (CM_RGB_Slave_10_IntErrorRam_Cx2_kein_Fehler), 3=Cx3_Fehler (CM_RGB_Slave_10_IntErrorRam_Cx3_Fehler)}, range raw 0..3, transfer-property=PENDING, to SAM(timeout 3.5 s)  # Fehler im RAM
            signal RGB_Slave_10_IntErrorRom_XIX_RGBs_Slave_10_XIX_E3V_SAM_LIN9: start 26, 2 bit, little-endian, data-type-policy=OVERRIDE, i-signal-type=PRIMITIVE, init-value=0, base-type=BT_RGB_Slave_10_IntErrorRom, invalid-value=Invalid_RGB_Slave_10_IntErrorRom_XIX_RGBs_Slave_10_XIX_E3V_SAM_LIN9:3, compu {0=Cx0_Init (CM_RGB_Slave_10_IntErrorRom_Cx0_Init), 1=Cx1_nicht_erlaubt (CM_RGB_Slave_10_IntErrorRom_Cx1_nicht_erlaubt), 2=Cx2_kein_Fehler (CM_RGB_Slave_10_IntErrorRom_Cx2_kein_Fehler), 3=Cx3_Fehler (CM_RGB_Slave_10_IntErrorRom_Cx3_Fehler)}, range raw 0..3, transfer-property=PENDING, to SAM(timeout 3.5 s)  # Fehler im ROM
            signal RGB_Slave_10_IntErrorNvm_XIX_RGBs_Slave_10_XIX_E3V_SAM_LIN9: start 28, 2 bit, little-endian, data-type-policy=OVERRIDE, i-signal-type=PRIMITIVE, init-value=0, base-type=BT_RGB_Slave_10_IntErrorNvm, invalid-value=Invalid_RGB_Slave_10_IntErrorNvm_XIX_RGBs_Slave_10_XIX_E3V_SAM_LIN9:3, compu {0=Cx0_Init (CM_RGB_Slave_10_IntErrorNvm_Cx0_Init), 1=Cx1_nicht_erlaubt (CM_RGB_Slave_10_IntErrorNvm_Cx1_nicht_erlaubt), 2=Cx2_kein_Fehler (CM_RGB_Slave_10_IntErrorNvm_Cx2_kein_Fehler), 3=Cx3_Fehler (CM_RGB_Slave_10_IntErrorNvm_Cx3_Fehler)}, range raw 0..3, transfer-property=PENDING, to SAM(timeout 3.5 s)  # Fehler im NVM
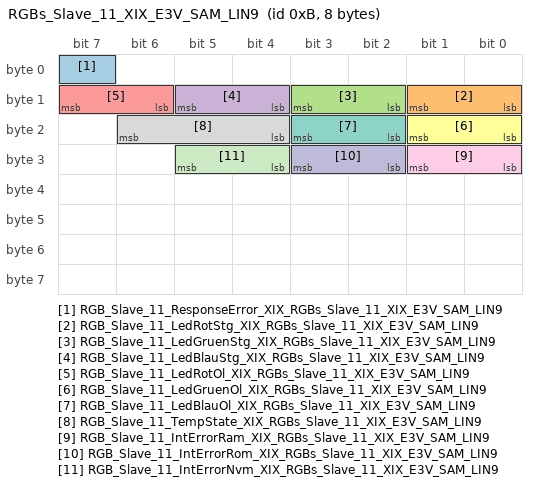
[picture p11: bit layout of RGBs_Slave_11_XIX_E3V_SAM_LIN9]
        frame RGBs_Slave_11_XIX_E3V_SAM_LIN9: id 0xB, to SAM, frame-length=8, lin-checksum=ENHANCED
          pdu RGBs_Slave_11_XIX_E3V_SAM_LIN9: length=8, unused-bit-pattern=0
            signal RGB_Slave_11_ResponseError_XIX_RGBs_Slave_11_XIX_E3V_SAM_LIN9: start 7, 1 bit, little-endian, data-type-policy=OVERRIDE, i-signal-type=PRIMITIVE, init-value=0, base-type=BT_RGB_Slave_11_ResponseError, invalid-value=Invalid_RGB_Slave_11_ResponseError_XIX_RGBs_Slave_11_XIX_E3V_SAM_LIN9:1, compu {0=Cx0_normal (CM_RGB_Slave_11_ResponseError_Cx0_normal), 1=Cx1_Fehler (CM_RGB_Slave_11_ResponseError_Cx1_Fehler)}, range raw 0..1, transfer-property=PENDING, to SAM(timeout 3.5 s)  # siehe LIN2.0-Specification (Darf nicht über ein Fehlergueltigkeitsbit abgesichtert werden!)
            signal RGB_Slave_11_LedRotStg_XIX_RGBs_Slave_11_XIX_E3V_SAM_LIN9: start 8, 2 bit, little-endian, data-type-policy=OVERRIDE, i-signal-type=PRIMITIVE, init-value=0, base-type=BT_RGB_Slave_11_LedRotStg, invalid-value=Invalid_RGB_Slave_11_LedRotStg_XIX_RGBs_Slave_11_XIX_E3V_SAM_LIN9:3, compu {0=Cx0_Init (CM_RGB_Slave_11_LedRotStg_Cx0_Init), 1=Cx1_nicht_erlaubt (CM_RGB_Slave_11_LedRotStg_Cx1_nicht_erlaubt), 2=Cx2_kein_Fehler (CM_RGB_Slave_11_LedRotStg_Cx2_kein_Fehler), 3=Cx3_Fehler (CM_RGB_Slave_11_LedRotStg_Cx3_Fehler)}, range raw 0..3, transfer-property=PENDING, to SAM(timeout 3.5 s)  # Short To Ground für Rote LED
            signal RGB_Slave_11_LedGruenStg_XIX_RGBs_Slave_11_XIX_E3V_SAM_LIN9: start 10, 2 bit, little-endian, data-type-policy=OVERRIDE, i-signal-type=PRIMITIVE, init-value=0, base-type=BT_RGB_Slave_11_LedGruenStg, invalid-value=Invalid_RGB_Slave_11_LedGruenStg_XIX_RGBs_Slave_11_XIX_E3V_SAM_LIN9:3, compu {0=Cx0_Init (CM_RGB_Slave_11_LedGruenStg_Cx0_Init), 1=Cx1_nicht_erlaubt (CM_RGB_Slave_11_LedGruenStg_Cx1_nicht_erlaubt), 2=Cx2_kein_Fehler (CM_RGB_Slave_11_LedGruenStg_Cx2_kein_Fehler), 3=Cx3_Fehler (CM_RGB_Slave_11_LedGruenStg_Cx3_Fehler)}, range raw 0..3, transfer-property=PENDING, to SAM(timeout 3.5 s)  # Short To Ground für Grüne LED
            signal RGB_Slave_11_LedBlauStg_XIX_RGBs_Slave_11_XIX_E3V_SAM_LIN9: start 12, 2 bit, little-endian, data-type-policy=OVERRIDE, i-signal-type=PRIMITIVE, init-value=0, base-type=BT_RGB_Slave_11_LedBlauStg, invalid-value=Invalid_RGB_Slave_11_LedBlauStg_XIX_RGBs_Slave_11_XIX_E3V_SAM_LIN9:3, compu {0=Cx0_Init (CM_RGB_Slave_11_LedBlauStg_Cx0_Init), 1=Cx1_nicht_erlaubt (CM_RGB_Slave_11_LedBlauStg_Cx1_nicht_erlaubt), 2=Cx2_kein_Fehler (CM_RGB_Slave_11_LedBlauStg_Cx2_kein_Fehler), 3=Cx3_Fehler (CM_RGB_Slave_11_LedBlauStg_Cx3_Fehler)}, range raw 0..3, transfer-property=PENDING, to SAM(timeout 3.5 s)  # Short To Ground für Blaue LED
            signal RGB_Slave_11_LedRotOl_XIX_RGBs_Slave_11_XIX_E3V_SAM_LIN9: start 14, 2 bit, little-endian, data-type-policy=OVERRIDE, i-signal-type=PRIMITIVE, init-value=0, base-type=BT_RGB_Slave_11_LedRotOl, invalid-value=Invalid_RGB_Slave_11_LedRotOl_XIX_RGBs_Slave_11_XIX_E3V_SAM_LIN9:3, compu {0=Cx0_Init (CM_RGB_Slave_11_LedRotOl_Cx0_Init), 1=Cx1_nicht_erlaubt (CM_RGB_Slave_11_LedRotOl_Cx1_nicht_erlaubt), 2=Cx2_kein_Fehler (CM_RGB_Slave_11_LedRotOl_Cx2_kein_Fehler), 3=Cx3_Fehler (CM_RGB_Slave_11_LedRotOl_Cx3_Fehler)}, range raw 0..3, transfer-property=PENDING, to SAM(timeout 3.5 s)  # OpenLoad für Rote LED
            signal RGB_Slave_11_LedGruenOl_XIX_RGBs_Slave_11_XIX_E3V_SAM_LIN9: start 16, 2 bit, little-endian, data-type-policy=OVERRIDE, i-signal-type=PRIMITIVE, init-value=0, base-type=BT_RGB_Slave_11_LedGruenOl, invalid-value=Invalid_RGB_Slave_11_LedGruenOl_XIX_RGBs_Slave_11_XIX_E3V_SAM_LIN9:3, compu {0=Cx0_Init (CM_RGB_Slave_11_LedGruenOl_Cx0_Init), 1=Cx1_nicht_erlaubt (CM_RGB_Slave_11_LedGruenOl_Cx1_nicht_erlaubt), 2=Cx2_kein_Fehler (CM_RGB_Slave_11_LedGruenOl_Cx2_kein_Fehler), 3=Cx3_Fehler (CM_RGB_Slave_11_LedGruenOl_Cx3_Fehler)}, range raw 0..3, transfer-property=PENDING, to SAM(timeout 3.5 s)  # OpenLoad für Rote LED
            signal RGB_Slave_11_LedBlauOl_XIX_RGBs_Slave_11_XIX_E3V_SAM_LIN9: start 18, 2 bit, little-endian, data-type-policy=OVERRIDE, i-signal-type=PRIMITIVE, init-value=0, base-type=BT_RGB_Slave_11_LedBlauOl, invalid-value=Invalid_RGB_Slave_11_LedBlauOl_XIX_RGBs_Slave_11_XIX_E3V_SAM_LIN9:3, compu {0=Cx0_Init (CM_RGB_Slave_11_LedBlauOl_Cx0_Init), 1=Cx1_nicht_erlaubt (CM_RGB_Slave_11_LedBlauOl_Cx1_nicht_erlaubt), 2=Cx2_kein_Fehler (CM_RGB_Slave_11_LedBlauOl_Cx2_kein_Fehler), 3=Cx3_Fehler (CM_RGB_Slave_11_LedBlauOl_Cx3_Fehler)}, range raw 0..3, transfer-property=PENDING, to SAM(timeout 3.5 s)  # OpenLoad für Blaue LED
            signal RGB_Slave_11_TempState_XIX_RGBs_Slave_11_XIX_E3V_SAM_LIN9: start 20, 3 bit, little-endian, data-type-policy=OVERRIDE, i-signal-type=PRIMITIVE, base-type=BT_RGB_Slave_11_TempState, compu {0=Cx0_keine_Temperaturregelung (CM_RGB_Slave_11_TempState_Cx0_keine_Temperaturregelung), 1=Cx1_Regelstufe_1 (CM_RGB_Slave_11_TempState_Cx1_Regelstufe_1), 2=Cx2_Regelstufe_2 (CM_RGB_Slave_11_TempState_Cx2_Regelstufe_2), 3=Cx3_Regelstufe_3 (CM_RGB_Slave_11_TempState_Cx3_Regelstufe_3), 4=Cx4_Regelstufe_4 (CM_RGB_Slave_11_TempState_Cx4_Regelstufe_4), 5=Cx5_Regelstufe_5 (CM_RGB_Slave_11_TempState_Cx5_Regelstufe_5), 6=Cx6_Regelstufe_6 (CM_RGB_Slave_11_TempState_Cx6_Regelstufe_6), 7=Cx7_Regelstufe_7 (CM_RGB_Slave_11_TempState_Cx7_Regelstufe_7)}, range raw 0..7, transfer-property=PENDING, to SAM(timeout 3.5 s)  # Status Temperaturregelung
            signal RGB_Slave_11_IntErrorRam_XIX_RGBs_Slave_11_XIX_E3V_SAM_LIN9: start 24, 2 bit, little-endian, data-type-policy=OVERRIDE, i-signal-type=PRIMITIVE, init-value=0, base-type=BT_RGB_Slave_11_IntErrorRam, invalid-value=Invalid_RGB_Slave_11_IntErrorRam_XIX_RGBs_Slave_11_XIX_E3V_SAM_LIN9:3, compu {0=Cx0_Init (CM_RGB_Slave_11_IntErrorRam_Cx0_Init), 1=Cx1_nicht_erlaubt (CM_RGB_Slave_11_IntErrorRam_Cx1_nicht_erlaubt), 2=Cx2_kein_Fehler (CM_RGB_Slave_11_IntErrorRam_Cx2_kein_Fehler), 3=Cx3_Fehler (CM_RGB_Slave_11_IntErrorRam_Cx3_Fehler)}, range raw 0..3, transfer-property=PENDING, to SAM(timeout 3.5 s)  # Fehler im RAM
            signal RGB_Slave_11_IntErrorRom_XIX_RGBs_Slave_11_XIX_E3V_SAM_LIN9: start 26, 2 bit, little-endian, data-type-policy=OVERRIDE, i-signal-type=PRIMITIVE, init-value=0, base-type=BT_RGB_Slave_11_IntErrorRom, invalid-value=Invalid_RGB_Slave_11_IntErrorRom_XIX_RGBs_Slave_11_XIX_E3V_SAM_LIN9:3, compu {0=Cx0_Init (CM_RGB_Slave_11_IntErrorRom_Cx0_Init), 1=Cx1_nicht_erlaubt (CM_RGB_Slave_11_IntErrorRom_Cx1_nicht_erlaubt), 2=Cx2_kein_Fehler (CM_RGB_Slave_11_IntErrorRom_Cx2_kein_Fehler), 3=Cx3_Fehler (CM_RGB_Slave_11_IntErrorRom_Cx3_Fehler)}, range raw 0..3, transfer-property=PENDING, to SAM(timeout 3.5 s)  # Fehler im ROM
            signal RGB_Slave_11_IntErrorNvm_XIX_RGBs_Slave_11_XIX_E3V_SAM_LIN9: start 28, 2 bit, little-endian, data-type-policy=OVERRIDE, i-signal-type=PRIMITIVE, init-value=0, base-type=BT_RGB_Slave_11_IntErrorNvm, invalid-value=Invalid_RGB_Slave_11_IntErrorNvm_XIX_RGBs_Slave_11_XIX_E3V_SAM_LIN9:3, compu {0=Cx0_Init (CM_RGB_Slave_11_IntErrorNvm_Cx0_Init), 1=Cx1_nicht_erlaubt (CM_RGB_Slave_11_IntErrorNvm_Cx1_nicht_erlaubt), 2=Cx2_kein_Fehler (CM_RGB_Slave_11_IntErrorNvm_Cx2_kein_Fehler), 3=Cx3_Fehler (CM_RGB_Slave_11_IntErrorNvm_Cx3_Fehler)}, range raw 0..3, transfer-property=PENDING, to SAM(timeout 3.5 s)  # Fehler im NVM
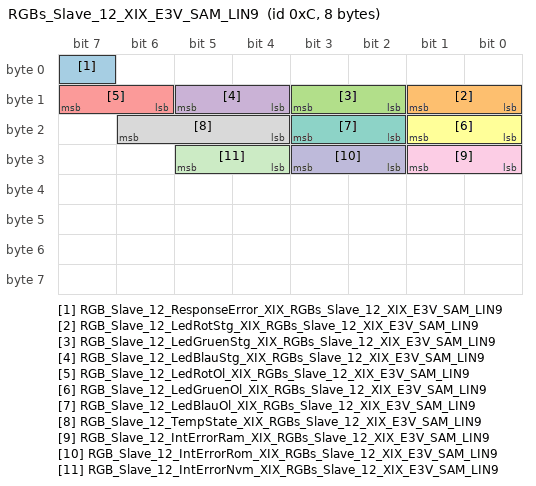
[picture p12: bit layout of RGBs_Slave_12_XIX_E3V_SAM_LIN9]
        frame RGBs_Slave_12_XIX_E3V_SAM_LIN9: id 0xC, to SAM, frame-length=8, lin-checksum=ENHANCED
          pdu RGBs_Slave_12_XIX_E3V_SAM_LIN9: length=8, unused-bit-pattern=0
            signal RGB_Slave_12_ResponseError_XIX_RGBs_Slave_12_XIX_E3V_SAM_LIN9: start 7, 1 bit, little-endian, data-type-policy=OVERRIDE, i-signal-type=PRIMITIVE, init-value=0, base-type=BT_RGB_Slave_12_ResponseError, invalid-value=Invalid_RGB_Slave_12_ResponseError_XIX_RGBs_Slave_12_XIX_E3V_SAM_LIN9:1, compu {0=Cx0_normal (CM_RGB_Slave_12_ResponseError_Cx0_normal), 1=Cx1_Fehler (CM_RGB_Slave_12_ResponseError_Cx1_Fehler)}, range raw 0..1, transfer-property=PENDING, to SAM(timeout 3.5 s)  # siehe LIN2.0-Specification (Darf nicht über ein Fehlergueltigkeitsbit abgesichtert werden!)
            signal RGB_Slave_12_LedRotStg_XIX_RGBs_Slave_12_XIX_E3V_SAM_LIN9: start 8, 2 bit, little-endian, data-type-policy=OVERRIDE, i-signal-type=PRIMITIVE, init-value=0, base-type=BT_RGB_Slave_12_LedRotStg, invalid-value=Invalid_RGB_Slave_12_LedRotStg_XIX_RGBs_Slave_12_XIX_E3V_SAM_LIN9:3, compu {0=Cx0_Init (CM_RGB_Slave_12_LedRotStg_Cx0_Init), 1=Cx1_nicht_erlaubt (CM_RGB_Slave_12_LedRotStg_Cx1_nicht_erlaubt), 2=Cx2_kein_Fehler (CM_RGB_Slave_12_LedRotStg_Cx2_kein_Fehler), 3=Cx3_Fehler (CM_RGB_Slave_12_LedRotStg_Cx3_Fehler)}, range raw 0..3, transfer-property=PENDING, to SAM(timeout 3.5 s)  # Short To Ground für Rote LED
            signal RGB_Slave_12_LedGruenStg_XIX_RGBs_Slave_12_XIX_E3V_SAM_LIN9: start 10, 2 bit, little-endian, data-type-policy=OVERRIDE, i-signal-type=PRIMITIVE, init-value=0, base-type=BT_RGB_Slave_12_LedGruenStg, invalid-value=Invalid_RGB_Slave_12_LedGruenStg_XIX_RGBs_Slave_12_XIX_E3V_SAM_LIN9:3, compu {0=Cx0_Init (CM_RGB_Slave_12_LedGruenStg_Cx0_Init), 1=Cx1_nicht_erlaubt (CM_RGB_Slave_12_LedGruenStg_Cx1_nicht_erlaubt), 2=Cx2_kein_Fehler (CM_RGB_Slave_12_LedGruenStg_Cx2_kein_Fehler), 3=Cx3_Fehler (CM_RGB_Slave_12_LedGruenStg_Cx3_Fehler)}, range raw 0..3, transfer-property=PENDING, to SAM(timeout 3.5 s)  # Short To Ground für Grüne LED
            signal RGB_Slave_12_LedBlauStg_XIX_RGBs_Slave_12_XIX_E3V_SAM_LIN9: start 12, 2 bit, little-endian, data-type-policy=OVERRIDE, i-signal-type=PRIMITIVE, init-value=0, base-type=BT_RGB_Slave_12_LedBlauStg, invalid-value=Invalid_RGB_Slave_12_LedBlauStg_XIX_RGBs_Slave_12_XIX_E3V_SAM_LIN9:3, compu {0=Cx0_Init (CM_RGB_Slave_12_LedBlauStg_Cx0_Init), 1=Cx1_nicht_erlaubt (CM_RGB_Slave_12_LedBlauStg_Cx1_nicht_erlaubt), 2=Cx2_kein_Fehler (CM_RGB_Slave_12_LedBlauStg_Cx2_kein_Fehler), 3=Cx3_Fehler (CM_RGB_Slave_12_LedBlauStg_Cx3_Fehler)}, range raw 0..3, transfer-property=PENDING, to SAM(timeout 3.5 s)  # Short To Ground für Blaue LED
            signal RGB_Slave_12_LedRotOl_XIX_RGBs_Slave_12_XIX_E3V_SAM_LIN9: start 14, 2 bit, little-endian, data-type-policy=OVERRIDE, i-signal-type=PRIMITIVE, init-value=0, base-type=BT_RGB_Slave_12_LedRotOl, invalid-value=Invalid_RGB_Slave_12_LedRotOl_XIX_RGBs_Slave_12_XIX_E3V_SAM_LIN9:3, compu {0=Cx0_Init (CM_RGB_Slave_12_LedRotOl_Cx0_Init), 1=Cx1_nicht_erlaubt (CM_RGB_Slave_12_LedRotOl_Cx1_nicht_erlaubt), 2=Cx2_kein_Fehler (CM_RGB_Slave_12_LedRotOl_Cx2_kein_Fehler), 3=Cx3_Fehler (CM_RGB_Slave_12_LedRotOl_Cx3_Fehler)}, range raw 0..3, transfer-property=PENDING, to SAM(timeout 3.5 s)  # OpenLoad für Rote LED
            signal RGB_Slave_12_LedGruenOl_XIX_RGBs_Slave_12_XIX_E3V_SAM_LIN9: start 16, 2 bit, little-endian, data-type-policy=OVERRIDE, i-signal-type=PRIMITIVE, init-value=0, base-type=BT_RGB_Slave_12_LedGruenOl, invalid-value=Invalid_RGB_Slave_12_LedGruenOl_XIX_RGBs_Slave_12_XIX_E3V_SAM_LIN9:3, compu {0=Cx0_Init (CM_RGB_Slave_12_LedGruenOl_Cx0_Init), 1=Cx1_nicht_erlaubt (CM_RGB_Slave_12_LedGruenOl_Cx1_nicht_erlaubt), 2=Cx2_kein_Fehler (CM_RGB_Slave_12_LedGruenOl_Cx2_kein_Fehler), 3=Cx3_Fehler (CM_RGB_Slave_12_LedGruenOl_Cx3_Fehler)}, range raw 0..3, transfer-property=PENDING, to SAM(timeout 3.5 s)  # OpenLoad für Rote LED
            signal RGB_Slave_12_LedBlauOl_XIX_RGBs_Slave_12_XIX_E3V_SAM_LIN9: start 18, 2 bit, little-endian, data-type-policy=OVERRIDE, i-signal-type=PRIMITIVE, init-value=0, base-type=BT_RGB_Slave_12_LedBlauOl, invalid-value=Invalid_RGB_Slave_12_LedBlauOl_XIX_RGBs_Slave_12_XIX_E3V_SAM_LIN9:3, compu {0=Cx0_Init (CM_RGB_Slave_12_LedBlauOl_Cx0_Init), 1=Cx1_nicht_erlaubt (CM_RGB_Slave_12_LedBlauOl_Cx1_nicht_erlaubt), 2=Cx2_kein_Fehler (CM_RGB_Slave_12_LedBlauOl_Cx2_kein_Fehler), 3=Cx3_Fehler (CM_RGB_Slave_12_LedBlauOl_Cx3_Fehler)}, range raw 0..3, transfer-property=PENDING, to SAM(timeout 3.5 s)  # OpenLoad für Blaue LED
            signal RGB_Slave_12_TempState_XIX_RGBs_Slave_12_XIX_E3V_SAM_LIN9: start 20, 3 bit, little-endian, data-type-policy=OVERRIDE, i-signal-type=PRIMITIVE, base-type=BT_RGB_Slave_12_TempState, compu {0=Cx0_keine_Temperaturregelung (CM_RGB_Slave_12_TempState_Cx0_keine_Temperaturregelung), 1=Cx1_Regelstufe_1 (CM_RGB_Slave_12_TempState_Cx1_Regelstufe_1), 2=Cx2_Regelstufe_2 (CM_RGB_Slave_12_TempState_Cx2_Regelstufe_2), 3=Cx3_Regelstufe_3 (CM_RGB_Slave_12_TempState_Cx3_Regelstufe_3), 4=Cx4_Regelstufe_4 (CM_RGB_Slave_12_TempState_Cx4_Regelstufe_4), 5=Cx5_Regelstufe_5 (CM_RGB_Slave_12_TempState_Cx5_Regelstufe_5), 6=Cx6_Regelstufe_6 (CM_RGB_Slave_12_TempState_Cx6_Regelstufe_6), 7=Cx7_Regelstufe_7 (CM_RGB_Slave_12_TempState_Cx7_Regelstufe_7)}, range raw 0..7, transfer-property=PENDING, to SAM(timeout 3.5 s)  # Status Temperaturregelung
            signal RGB_Slave_12_IntErrorRam_XIX_RGBs_Slave_12_XIX_E3V_SAM_LIN9: start 24, 2 bit, little-endian, data-type-policy=OVERRIDE, i-signal-type=PRIMITIVE, init-value=0, base-type=BT_RGB_Slave_12_IntErrorRam, invalid-value=Invalid_RGB_Slave_12_IntErrorRam_XIX_RGBs_Slave_12_XIX_E3V_SAM_LIN9:3, compu {0=Cx0_Init (CM_RGB_Slave_12_IntErrorRam_Cx0_Init), 1=Cx1_nicht_erlaubt (CM_RGB_Slave_12_IntErrorRam_Cx1_nicht_erlaubt), 2=Cx2_kein_Fehler (CM_RGB_Slave_12_IntErrorRam_Cx2_kein_Fehler), 3=Cx3_Fehler (CM_RGB_Slave_12_IntErrorRam_Cx3_Fehler)}, range raw 0..3, transfer-property=PENDING, to SAM(timeout 3.5 s)  # Fehler im RAM
            signal RGB_Slave_12_IntErrorRom_XIX_RGBs_Slave_12_XIX_E3V_SAM_LIN9: start 26, 2 bit, little-endian, data-type-policy=OVERRIDE, i-signal-type=PRIMITIVE, init-value=0, base-type=BT_RGB_Slave_12_IntErrorRom, invalid-value=Invalid_RGB_Slave_12_IntErrorRom_XIX_RGBs_Slave_12_XIX_E3V_SAM_LIN9:3, compu {0=Cx0_Init (CM_RGB_Slave_12_IntErrorRom_Cx0_Init), 1=Cx1_nicht_erlaubt (CM_RGB_Slave_12_IntErrorRom_Cx1_nicht_erlaubt), 2=Cx2_kein_Fehler (CM_RGB_Slave_12_IntErrorRom_Cx2_kein_Fehler), 3=Cx3_Fehler (CM_RGB_Slave_12_IntErrorRom_Cx3_Fehler)}, range raw 0..3, transfer-property=PENDING, to SAM(timeout 3.5 s)  # Fehler im ROM
            signal RGB_Slave_12_IntErrorNvm_XIX_RGBs_Slave_12_XIX_E3V_SAM_LIN9: start 28, 2 bit, little-endian, data-type-policy=OVERRIDE, i-signal-type=PRIMITIVE, init-value=0, base-type=BT_RGB_Slave_12_IntErrorNvm, invalid-value=Invalid_RGB_Slave_12_IntErrorNvm_XIX_RGBs_Slave_12_XIX_E3V_SAM_LIN9:3, compu {0=Cx0_Init (CM_RGB_Slave_12_IntErrorNvm_Cx0_Init), 1=Cx1_nicht_erlaubt (CM_RGB_Slave_12_IntErrorNvm_Cx1_nicht_erlaubt), 2=Cx2_kein_Fehler (CM_RGB_Slave_12_IntErrorNvm_Cx2_kein_Fehler), 3=Cx3_Fehler (CM_RGB_Slave_12_IntErrorNvm_Cx3_Fehler)}, range raw 0..3, transfer-property=PENDING, to SAM(timeout 3.5 s)  # Fehler im NVM
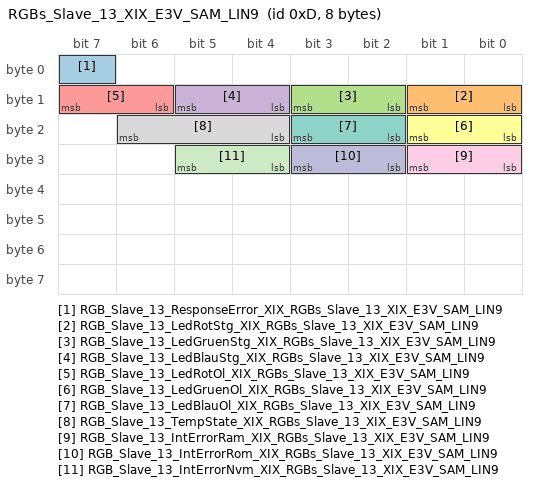
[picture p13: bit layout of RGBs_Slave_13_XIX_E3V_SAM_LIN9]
        frame RGBs_Slave_13_XIX_E3V_SAM_LIN9: id 0xD, to SAM, frame-length=8, lin-checksum=ENHANCED
          pdu RGBs_Slave_13_XIX_E3V_SAM_LIN9: length=8, unused-bit-pattern=0
            signal RGB_Slave_13_ResponseError_XIX_RGBs_Slave_13_XIX_E3V_SAM_LIN9: start 7, 1 bit, little-endian, data-type-policy=OVERRIDE, i-signal-type=PRIMITIVE, init-value=0, base-type=BT_RGB_Slave_13_ResponseError, invalid-value=Invalid_RGB_Slave_13_ResponseError_XIX_RGBs_Slave_13_XIX_E3V_SAM_LIN9:1, compu {0=Cx0_normal (CM_RGB_Slave_13_ResponseError_Cx0_normal), 1=Cx1_Fehler (CM_RGB_Slave_13_ResponseError_Cx1_Fehler)}, range raw 0..1, transfer-property=PENDING, to SAM(timeout 3.5 s)  # siehe LIN2.0-Specification (Darf nicht über ein Fehlergueltigkeitsbit abgesichtert werden!)
            signal RGB_Slave_13_LedRotStg_XIX_RGBs_Slave_13_XIX_E3V_SAM_LIN9: start 8, 2 bit, little-endian, data-type-policy=OVERRIDE, i-signal-type=PRIMITIVE, init-value=0, base-type=BT_RGB_Slave_13_LedRotStg, invalid-value=Invalid_RGB_Slave_13_LedRotStg_XIX_RGBs_Slave_13_XIX_E3V_SAM_LIN9:3, compu {0=Cx0_Init (CM_RGB_Slave_13_LedRotStg_Cx0_Init), 1=Cx1_nicht_erlaubt (CM_RGB_Slave_13_LedRotStg_Cx1_nicht_erlaubt), 2=Cx2_kein_Fehler (CM_RGB_Slave_13_LedRotStg_Cx2_kein_Fehler), 3=Cx3_Fehler (CM_RGB_Slave_13_LedRotStg_Cx3_Fehler)}, range raw 0..3, transfer-property=PENDING, to SAM(timeout 3.5 s)  # Short To Ground für Rote LED
            signal RGB_Slave_13_LedGruenStg_XIX_RGBs_Slave_13_XIX_E3V_SAM_LIN9: start 10, 2 bit, little-endian, data-type-policy=OVERRIDE, i-signal-type=PRIMITIVE, init-value=0, base-type=BT_RGB_Slave_13_LedGruenStg, invalid-value=Invalid_RGB_Slave_13_LedGruenStg_XIX_RGBs_Slave_13_XIX_E3V_SAM_LIN9:3, compu {0=Cx0_Init (CM_RGB_Slave_13_LedGruenStg_Cx0_Init), 1=Cx1_nicht_erlaubt (CM_RGB_Slave_13_LedGruenStg_Cx1_nicht_erlaubt), 2=Cx2_kein_Fehler (CM_RGB_Slave_13_LedGruenStg_Cx2_kein_Fehler), 3=Cx3_Fehler (CM_RGB_Slave_13_LedGruenStg_Cx3_Fehler)}, range raw 0..3, transfer-property=PENDING, to SAM(timeout 3.5 s)  # Short To Ground für Grüne LED
            signal RGB_Slave_13_LedBlauStg_XIX_RGBs_Slave_13_XIX_E3V_SAM_LIN9: start 12, 2 bit, little-endian, data-type-policy=OVERRIDE, i-signal-type=PRIMITIVE, init-value=0, base-type=BT_RGB_Slave_13_LedBlauStg, invalid-value=Invalid_RGB_Slave_13_LedBlauStg_XIX_RGBs_Slave_13_XIX_E3V_SAM_LIN9:3, compu {0=Cx0_Init (CM_RGB_Slave_13_LedBlauStg_Cx0_Init), 1=Cx1_nicht_erlaubt (CM_RGB_Slave_13_LedBlauStg_Cx1_nicht_erlaubt), 2=Cx2_kein_Fehler (CM_RGB_Slave_13_LedBlauStg_Cx2_kein_Fehler), 3=Cx3_Fehler (CM_RGB_Slave_13_LedBlauStg_Cx3_Fehler)}, range raw 0..3, transfer-property=PENDING, to SAM(timeout 3.5 s)  # Short To Ground für Blaue LED
            signal RGB_Slave_13_LedRotOl_XIX_RGBs_Slave_13_XIX_E3V_SAM_LIN9: start 14, 2 bit, little-endian, data-type-policy=OVERRIDE, i-signal-type=PRIMITIVE, init-value=0, base-type=BT_RGB_Slave_13_LedRotOl, invalid-value=Invalid_RGB_Slave_13_LedRotOl_XIX_RGBs_Slave_13_XIX_E3V_SAM_LIN9:3, compu {0=Cx0_Init (CM_RGB_Slave_13_LedRotOl_Cx0_Init), 1=Cx1_nicht_erlaubt (CM_RGB_Slave_13_LedRotOl_Cx1_nicht_erlaubt), 2=Cx2_kein_Fehler (CM_RGB_Slave_13_LedRotOl_Cx2_kein_Fehler), 3=Cx3_Fehler (CM_RGB_Slave_13_LedRotOl_Cx3_Fehler)}, range raw 0..3, transfer-property=PENDING, to SAM(timeout 3.5 s)  # OpenLoad für Rote LED
            signal RGB_Slave_13_LedGruenOl_XIX_RGBs_Slave_13_XIX_E3V_SAM_LIN9: start 16, 2 bit, little-endian, data-type-policy=OVERRIDE, i-signal-type=PRIMITIVE, init-value=0, base-type=BT_RGB_Slave_13_LedGruenOl, invalid-value=Invalid_RGB_Slave_13_LedGruenOl_XIX_RGBs_Slave_13_XIX_E3V_SAM_LIN9:3, compu {0=Cx0_Init (CM_RGB_Slave_13_LedGruenOl_Cx0_Init), 1=Cx1_nicht_erlaubt (CM_RGB_Slave_13_LedGruenOl_Cx1_nicht_erlaubt), 2=Cx2_kein_Fehler (CM_RGB_Slave_13_LedGruenOl_Cx2_kein_Fehler), 3=Cx3_Fehler (CM_RGB_Slave_13_LedGruenOl_Cx3_Fehler)}, range raw 0..3, transfer-property=PENDING, to SAM(timeout 3.5 s)  # OpenLoad für Rote LED
            signal RGB_Slave_13_LedBlauOl_XIX_RGBs_Slave_13_XIX_E3V_SAM_LIN9: start 18, 2 bit, little-endian, data-type-policy=OVERRIDE, i-signal-type=PRIMITIVE, init-value=0, base-type=BT_RGB_Slave_13_LedBlauOl, invalid-value=Invalid_RGB_Slave_13_LedBlauOl_XIX_RGBs_Slave_13_XIX_E3V_SAM_LIN9:3, compu {0=Cx0_Init (CM_RGB_Slave_13_LedBlauOl_Cx0_Init), 1=Cx1_nicht_erlaubt (CM_RGB_Slave_13_LedBlauOl_Cx1_nicht_erlaubt), 2=Cx2_kein_Fehler (CM_RGB_Slave_13_LedBlauOl_Cx2_kein_Fehler), 3=Cx3_Fehler (CM_RGB_Slave_13_LedBlauOl_Cx3_Fehler)}, range raw 0..3, transfer-property=PENDING, to SAM(timeout 3.5 s)  # OpenLoad für Blaue LED
            signal RGB_Slave_13_TempState_XIX_RGBs_Slave_13_XIX_E3V_SAM_LIN9: start 20, 3 bit, little-endian, data-type-policy=OVERRIDE, i-signal-type=PRIMITIVE, base-type=BT_RGB_Slave_13_TempState, compu {0=Cx0_keine_Temperaturregelung (CM_RGB_Slave_13_TempState_Cx0_keine_Temperaturregelung), 1=Cx1_Regelstufe_1 (CM_RGB_Slave_13_TempState_Cx1_Regelstufe_1), 2=Cx2_Regelstufe_2 (CM_RGB_Slave_13_TempState_Cx2_Regelstufe_2), 3=Cx3_Regelstufe_3 (CM_RGB_Slave_13_TempState_Cx3_Regelstufe_3), 4=Cx4_Regelstufe_4 (CM_RGB_Slave_13_TempState_Cx4_Regelstufe_4), 5=Cx5_Regelstufe_5 (CM_RGB_Slave_13_TempState_Cx5_Regelstufe_5), 6=Cx6_Regelstufe_6 (CM_RGB_Slave_13_TempState_Cx6_Regelstufe_6), 7=Cx7_Regelstufe_7 (CM_RGB_Slave_13_TempState_Cx7_Regelstufe_7)}, range raw 0..7, transfer-property=PENDING, to SAM(timeout 3.5 s)  # Status Temperaturregelung
            signal RGB_Slave_13_IntErrorRam_XIX_RGBs_Slave_13_XIX_E3V_SAM_LIN9: start 24, 2 bit, little-endian, data-type-policy=OVERRIDE, i-signal-type=PRIMITIVE, init-value=0, base-type=BT_RGB_Slave_13_IntErrorRam, invalid-value=Invalid_RGB_Slave_13_IntErrorRam_XIX_RGBs_Slave_13_XIX_E3V_SAM_LIN9:3, compu {0=Cx0_Init (CM_RGB_Slave_13_IntErrorRam_Cx0_Init), 1=Cx1_nicht_erlaubt (CM_RGB_Slave_13_IntErrorRam_Cx1_nicht_erlaubt), 2=Cx2_kein_Fehler (CM_RGB_Slave_13_IntErrorRam_Cx2_kein_Fehler), 3=Cx3_Fehler (CM_RGB_Slave_13_IntErrorRam_Cx3_Fehler)}, range raw 0..3, transfer-property=PENDING, to SAM(timeout 3.5 s)  # Fehler im RAM
            signal RGB_Slave_13_IntErrorRom_XIX_RGBs_Slave_13_XIX_E3V_SAM_LIN9: start 26, 2 bit, little-endian, data-type-policy=OVERRIDE, i-signal-type=PRIMITIVE, init-value=0, base-type=BT_RGB_Slave_13_IntErrorRom, invalid-value=Invalid_RGB_Slave_13_IntErrorRom_XIX_RGBs_Slave_13_XIX_E3V_SAM_LIN9:3, compu {0=Cx0_Init (CM_RGB_Slave_13_IntErrorRom_Cx0_Init), 1=Cx1_nicht_erlaubt (CM_RGB_Slave_13_IntErrorRom_Cx1_nicht_erlaubt), 2=Cx2_kein_Fehler (CM_RGB_Slave_13_IntErrorRom_Cx2_kein_Fehler), 3=Cx3_Fehler (CM_RGB_Slave_13_IntErrorRom_Cx3_Fehler)}, range raw 0..3, transfer-property=PENDING, to SAM(timeout 3.5 s)  # Fehler im ROM
            signal RGB_Slave_13_IntErrorNvm_XIX_RGBs_Slave_13_XIX_E3V_SAM_LIN9: start 28, 2 bit, little-endian, data-type-policy=OVERRIDE, i-signal-type=PRIMITIVE, init-value=0, base-type=BT_RGB_Slave_13_IntErrorNvm, invalid-value=Invalid_RGB_Slave_13_IntErrorNvm_XIX_RGBs_Slave_13_XIX_E3V_SAM_LIN9:3, compu {0=Cx0_Init (CM_RGB_Slave_13_IntErrorNvm_Cx0_Init), 1=Cx1_nicht_erlaubt (CM_RGB_Slave_13_IntErrorNvm_Cx1_nicht_erlaubt), 2=Cx2_kein_Fehler (CM_RGB_Slave_13_IntErrorNvm_Cx2_kein_Fehler), 3=Cx3_Fehler (CM_RGB_Slave_13_IntErrorNvm_Cx3_Fehler)}, range raw 0..3, transfer-property=PENDING, to SAM(timeout 3.5 s)  # Fehler im NVM
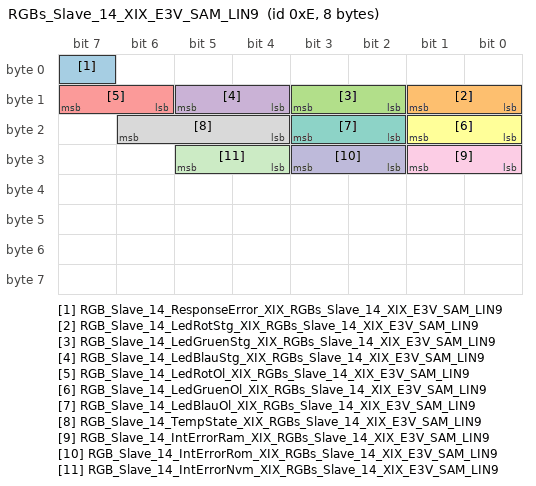
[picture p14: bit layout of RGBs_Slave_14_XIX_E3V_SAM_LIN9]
        frame RGBs_Slave_14_XIX_E3V_SAM_LIN9: id 0xE, to SAM, frame-length=8, lin-checksum=ENHANCED
          pdu RGBs_Slave_14_XIX_E3V_SAM_LIN9: length=8, unused-bit-pattern=0
            signal RGB_Slave_14_ResponseError_XIX_RGBs_Slave_14_XIX_E3V_SAM_LIN9: start 7, 1 bit, little-endian, data-type-policy=OVERRIDE, i-signal-type=PRIMITIVE, init-value=0, base-type=BT_RGB_Slave_14_ResponseError, invalid-value=Invalid_RGB_Slave_14_ResponseError_XIX_RGBs_Slave_14_XIX_E3V_SAM_LIN9:1, compu {0=Cx0_normal (CM_RGB_Slave_14_ResponseError_Cx0_normal), 1=Cx1_Fehler (CM_RGB_Slave_14_ResponseError_Cx1_Fehler)}, range raw 0..1, transfer-property=PENDING, to SAM(timeout 3.5 s)  # siehe LIN2.0-Specification (Darf nicht über ein Fehlergueltigkeitsbit abgesichtert werden!)
            signal RGB_Slave_14_LedRotStg_XIX_RGBs_Slave_14_XIX_E3V_SAM_LIN9: start 8, 2 bit, little-endian, data-type-policy=OVERRIDE, i-signal-type=PRIMITIVE, init-value=0, base-type=BT_RGB_Slave_14_LedRotStg, invalid-value=Invalid_RGB_Slave_14_LedRotStg_XIX_RGBs_Slave_14_XIX_E3V_SAM_LIN9:3, compu {0=Cx0_Init (CM_RGB_Slave_14_LedRotStg_Cx0_Init), 1=Cx1_nicht_erlaubt (CM_RGB_Slave_14_LedRotStg_Cx1_nicht_erlaubt), 2=Cx2_kein_Fehler (CM_RGB_Slave_14_LedRotStg_Cx2_kein_Fehler), 3=Cx3_Fehler (CM_RGB_Slave_14_LedRotStg_Cx3_Fehler)}, range raw 0..3, transfer-property=PENDING, to SAM(timeout 3.5 s)  # Short To Ground für Rote LED
            signal RGB_Slave_14_LedGruenStg_XIX_RGBs_Slave_14_XIX_E3V_SAM_LIN9: start 10, 2 bit, little-endian, data-type-policy=OVERRIDE, i-signal-type=PRIMITIVE, init-value=0, base-type=BT_RGB_Slave_14_LedGruenStg, invalid-value=Invalid_RGB_Slave_14_LedGruenStg_XIX_RGBs_Slave_14_XIX_E3V_SAM_LIN9:3, compu {0=Cx0_Init (CM_RGB_Slave_14_LedGruenStg_Cx0_Init), 1=Cx1_nicht_erlaubt (CM_RGB_Slave_14_LedGruenStg_Cx1_nicht_erlaubt), 2=Cx2_kein_Fehler (CM_RGB_Slave_14_LedGruenStg_Cx2_kein_Fehler), 3=Cx3_Fehler (CM_RGB_Slave_14_LedGruenStg_Cx3_Fehler)}, range raw 0..3, transfer-property=PENDING, to SAM(timeout 3.5 s)  # Short To Ground für Grüne LED
            signal RGB_Slave_14_LedBlauStg_XIX_RGBs_Slave_14_XIX_E3V_SAM_LIN9: start 12, 2 bit, little-endian, data-type-policy=OVERRIDE, i-signal-type=PRIMITIVE, init-value=0, base-type=BT_RGB_Slave_14_LedBlauStg, invalid-value=Invalid_RGB_Slave_14_LedBlauStg_XIX_RGBs_Slave_14_XIX_E3V_SAM_LIN9:3, compu {0=Cx0_Init (CM_RGB_Slave_14_LedBlauStg_Cx0_Init), 1=Cx1_nicht_erlaubt (CM_RGB_Slave_14_LedBlauStg_Cx1_nicht_erlaubt), 2=Cx2_kein_Fehler (CM_RGB_Slave_14_LedBlauStg_Cx2_kein_Fehler), 3=Cx3_Fehler (CM_RGB_Slave_14_LedBlauStg_Cx3_Fehler)}, range raw 0..3, transfer-property=PENDING, to SAM(timeout 3.5 s)  # Short To Ground für Blaue LED
            signal RGB_Slave_14_LedRotOl_XIX_RGBs_Slave_14_XIX_E3V_SAM_LIN9: start 14, 2 bit, little-endian, data-type-policy=OVERRIDE, i-signal-type=PRIMITIVE, init-value=0, base-type=BT_RGB_Slave_14_LedRotOl, invalid-value=Invalid_RGB_Slave_14_LedRotOl_XIX_RGBs_Slave_14_XIX_E3V_SAM_LIN9:3, compu {0=Cx0_Init (CM_RGB_Slave_14_LedRotOl_Cx0_Init), 1=Cx1_nicht_erlaubt (CM_RGB_Slave_14_LedRotOl_Cx1_nicht_erlaubt), 2=Cx2_kein_Fehler (CM_RGB_Slave_14_LedRotOl_Cx2_kein_Fehler), 3=Cx3_Fehler (CM_RGB_Slave_14_LedRotOl_Cx3_Fehler)}, range raw 0..3, transfer-property=PENDING, to SAM(timeout 3.5 s)  # OpenLoad für Rote LED
            signal RGB_Slave_14_LedGruenOl_XIX_RGBs_Slave_14_XIX_E3V_SAM_LIN9: start 16, 2 bit, little-endian, data-type-policy=OVERRIDE, i-signal-type=PRIMITIVE, init-value=0, base-type=BT_RGB_Slave_14_LedGruenOl, invalid-value=Invalid_RGB_Slave_14_LedGruenOl_XIX_RGBs_Slave_14_XIX_E3V_SAM_LIN9:3, compu {0=Cx0_Init (CM_RGB_Slave_14_LedGruenOl_Cx0_Init), 1=Cx1_nicht_erlaubt (CM_RGB_Slave_14_LedGruenOl_Cx1_nicht_erlaubt), 2=Cx2_kein_Fehler (CM_RGB_Slave_14_LedGruenOl_Cx2_kein_Fehler), 3=Cx3_Fehler (CM_RGB_Slave_14_LedGruenOl_Cx3_Fehler)}, range raw 0..3, transfer-property=PENDING, to SAM(timeout 3.5 s)  # OpenLoad für Rote LED
            signal RGB_Slave_14_LedBlauOl_XIX_RGBs_Slave_14_XIX_E3V_SAM_LIN9: start 18, 2 bit, little-endian, data-type-policy=OVERRIDE, i-signal-type=PRIMITIVE, init-value=0, base-type=BT_RGB_Slave_14_LedBlauOl, invalid-value=Invalid_RGB_Slave_14_LedBlauOl_XIX_RGBs_Slave_14_XIX_E3V_SAM_LIN9:3, compu {0=Cx0_Init (CM_RGB_Slave_14_LedBlauOl_Cx0_Init), 1=Cx1_nicht_erlaubt (CM_RGB_Slave_14_LedBlauOl_Cx1_nicht_erlaubt), 2=Cx2_kein_Fehler (CM_RGB_Slave_14_LedBlauOl_Cx2_kein_Fehler), 3=Cx3_Fehler (CM_RGB_Slave_14_LedBlauOl_Cx3_Fehler)}, range raw 0..3, transfer-property=PENDING, to SAM(timeout 3.5 s)  # OpenLoad für Blaue LED
            signal RGB_Slave_14_TempState_XIX_RGBs_Slave_14_XIX_E3V_SAM_LIN9: start 20, 3 bit, little-endian, data-type-policy=OVERRIDE, i-signal-type=PRIMITIVE, base-type=BT_RGB_Slave_14_TempState, compu {0=Cx0_keine_Temperaturregelung (CM_RGB_Slave_14_TempState_Cx0_keine_Temperaturregelung), 1=Cx1_Regelstufe_1 (CM_RGB_Slave_14_TempState_Cx1_Regelstufe_1), 2=Cx2_Regelstufe_2 (CM_RGB_Slave_14_TempState_Cx2_Regelstufe_2), 3=Cx3_Regelstufe_3 (CM_RGB_Slave_14_TempState_Cx3_Regelstufe_3), 4=Cx4_Regelstufe_4 (CM_RGB_Slave_14_TempState_Cx4_Regelstufe_4), 5=Cx5_Regelstufe_5 (CM_RGB_Slave_14_TempState_Cx5_Regelstufe_5), 6=Cx6_Regelstufe_6 (CM_RGB_Slave_14_TempState_Cx6_Regelstufe_6), 7=Cx7_Regelstufe_7 (CM_RGB_Slave_14_TempState_Cx7_Regelstufe_7)}, range raw 0..7, transfer-property=PENDING, to SAM(timeout 3.5 s)  # Status Temperaturregelung
            signal RGB_Slave_14_IntErrorRam_XIX_RGBs_Slave_14_XIX_E3V_SAM_LIN9: start 24, 2 bit, little-endian, data-type-policy=OVERRIDE, i-signal-type=PRIMITIVE, init-value=0, base-type=BT_RGB_Slave_14_IntErrorRam, invalid-value=Invalid_RGB_Slave_14_IntErrorRam_XIX_RGBs_Slave_14_XIX_E3V_SAM_LIN9:3, compu {0=Cx0_Init (CM_RGB_Slave_14_IntErrorRam_Cx0_Init), 1=Cx1_nicht_erlaubt (CM_RGB_Slave_14_IntErrorRam_Cx1_nicht_erlaubt), 2=Cx2_kein_Fehler (CM_RGB_Slave_14_IntErrorRam_Cx2_kein_Fehler), 3=Cx3_Fehler (CM_RGB_Slave_14_IntErrorRam_Cx3_Fehler)}, range raw 0..3, transfer-property=PENDING, to SAM(timeout 3.5 s)  # Fehler im RAM
            signal RGB_Slave_14_IntErrorRom_XIX_RGBs_Slave_14_XIX_E3V_SAM_LIN9: start 26, 2 bit, little-endian, data-type-policy=OVERRIDE, i-signal-type=PRIMITIVE, init-value=0, base-type=BT_RGB_Slave_14_IntErrorRom, invalid-value=Invalid_RGB_Slave_14_IntErrorRom_XIX_RGBs_Slave_14_XIX_E3V_SAM_LIN9:3, compu {0=Cx0_Init (CM_RGB_Slave_14_IntErrorRom_Cx0_Init), 1=Cx1_nicht_erlaubt (CM_RGB_Slave_14_IntErrorRom_Cx1_nicht_erlaubt), 2=Cx2_kein_Fehler (CM_RGB_Slave_14_IntErrorRom_Cx2_kein_Fehler), 3=Cx3_Fehler (CM_RGB_Slave_14_IntErrorRom_Cx3_Fehler)}, range raw 0..3, transfer-property=PENDING, to SAM(timeout 3.5 s)  # Fehler im ROM
            signal RGB_Slave_14_IntErrorNvm_XIX_RGBs_Slave_14_XIX_E3V_SAM_LIN9: start 28, 2 bit, little-endian, data-type-policy=OVERRIDE, i-signal-type=PRIMITIVE, init-value=0, base-type=BT_RGB_Slave_14_IntErrorNvm, invalid-value=Invalid_RGB_Slave_14_IntErrorNvm_XIX_RGBs_Slave_14_XIX_E3V_SAM_LIN9:3, compu {0=Cx0_Init (CM_RGB_Slave_14_IntErrorNvm_Cx0_Init), 1=Cx1_nicht_erlaubt (CM_RGB_Slave_14_IntErrorNvm_Cx1_nicht_erlaubt), 2=Cx2_kein_Fehler (CM_RGB_Slave_14_IntErrorNvm_Cx2_kein_Fehler), 3=Cx3_Fehler (CM_RGB_Slave_14_IntErrorNvm_Cx3_Fehler)}, range raw 0..3, transfer-property=PENDING, to SAM(timeout 3.5 s)  # Fehler im NVM
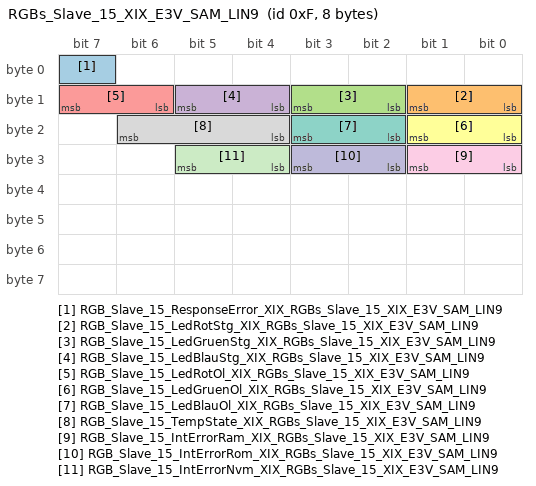
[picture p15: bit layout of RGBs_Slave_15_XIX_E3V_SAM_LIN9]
        frame RGBs_Slave_15_XIX_E3V_SAM_LIN9: id 0xF, to SAM, frame-length=8, lin-checksum=ENHANCED
          pdu RGBs_Slave_15_XIX_E3V_SAM_LIN9: length=8, unused-bit-pattern=0
            signal RGB_Slave_15_ResponseError_XIX_RGBs_Slave_15_XIX_E3V_SAM_LIN9: start 7, 1 bit, little-endian, data-type-policy=OVERRIDE, i-signal-type=PRIMITIVE, init-value=0, base-type=BT_RGB_Slave_15_ResponseError, invalid-value=Invalid_RGB_Slave_15_ResponseError_XIX_RGBs_Slave_15_XIX_E3V_SAM_LIN9:1, compu {0=Cx0_normal (CM_RGB_Slave_15_ResponseError_Cx0_normal), 1=Cx1_Fehler (CM_RGB_Slave_15_ResponseError_Cx1_Fehler)}, range raw 0..1, transfer-property=PENDING, to SAM(timeout 3.5 s)  # siehe LIN2.0-Specification (Darf nicht über ein Fehlergueltigkeitsbit abgesichtert werden!)
            signal RGB_Slave_15_LedRotStg_XIX_RGBs_Slave_15_XIX_E3V_SAM_LIN9: start 8, 2 bit, little-endian, data-type-policy=OVERRIDE, i-signal-type=PRIMITIVE, init-value=0, base-type=BT_RGB_Slave_15_LedRotStg, invalid-value=Invalid_RGB_Slave_15_LedRotStg_XIX_RGBs_Slave_15_XIX_E3V_SAM_LIN9:3, compu {0=Cx0_Init (CM_RGB_Slave_15_LedRotStg_Cx0_Init), 1=Cx1_nicht_erlaubt (CM_RGB_Slave_15_LedRotStg_Cx1_nicht_erlaubt), 2=Cx2_kein_Fehler (CM_RGB_Slave_15_LedRotStg_Cx2_kein_Fehler), 3=Cx3_Fehler (CM_RGB_Slave_15_LedRotStg_Cx3_Fehler)}, range raw 0..3, transfer-property=PENDING, to SAM(timeout 3.5 s)  # Short To Ground für Rote LED
            signal RGB_Slave_15_LedGruenStg_XIX_RGBs_Slave_15_XIX_E3V_SAM_LIN9: start 10, 2 bit, little-endian, data-type-policy=OVERRIDE, i-signal-type=PRIMITIVE, init-value=0, base-type=BT_RGB_Slave_15_LedGruenStg, invalid-value=Invalid_RGB_Slave_15_LedGruenStg_XIX_RGBs_Slave_15_XIX_E3V_SAM_LIN9:3, compu {0=Cx0_Init (CM_RGB_Slave_15_LedGruenStg_Cx0_Init), 1=Cx1_nicht_erlaubt (CM_RGB_Slave_15_LedGruenStg_Cx1_nicht_erlaubt), 2=Cx2_kein_Fehler (CM_RGB_Slave_15_LedGruenStg_Cx2_kein_Fehler), 3=Cx3_Fehler (CM_RGB_Slave_15_LedGruenStg_Cx3_Fehler)}, range raw 0..3, transfer-property=PENDING, to SAM(timeout 3.5 s)  # Short To Ground für Grüne LED
            signal RGB_Slave_15_LedBlauStg_XIX_RGBs_Slave_15_XIX_E3V_SAM_LIN9: start 12, 2 bit, little-endian, data-type-policy=OVERRIDE, i-signal-type=PRIMITIVE, init-value=0, base-type=BT_RGB_Slave_15_LedBlauStg, invalid-value=Invalid_RGB_Slave_15_LedBlauStg_XIX_RGBs_Slave_15_XIX_E3V_SAM_LIN9:3, compu {0=Cx0_Init (CM_RGB_Slave_15_LedBlauStg_Cx0_Init), 1=Cx1_nicht_erlaubt (CM_RGB_Slave_15_LedBlauStg_Cx1_nicht_erlaubt), 2=Cx2_kein_Fehler (CM_RGB_Slave_15_LedBlauStg_Cx2_kein_Fehler), 3=Cx3_Fehler (CM_RGB_Slave_15_LedBlauStg_Cx3_Fehler)}, range raw 0..3, transfer-property=PENDING, to SAM(timeout 3.5 s)  # Short To Ground für Blaue LED
            signal RGB_Slave_15_LedRotOl_XIX_RGBs_Slave_15_XIX_E3V_SAM_LIN9: start 14, 2 bit, little-endian, data-type-policy=OVERRIDE, i-signal-type=PRIMITIVE, init-value=0, base-type=BT_RGB_Slave_15_LedRotOl, invalid-value=Invalid_RGB_Slave_15_LedRotOl_XIX_RGBs_Slave_15_XIX_E3V_SAM_LIN9:3, compu {0=Cx0_Init (CM_RGB_Slave_15_LedRotOl_Cx0_Init), 1=Cx1_nicht_erlaubt (CM_RGB_Slave_15_LedRotOl_Cx1_nicht_erlaubt), 2=Cx2_kein_Fehler (CM_RGB_Slave_15_LedRotOl_Cx2_kein_Fehler), 3=Cx3_Fehler (CM_RGB_Slave_15_LedRotOl_Cx3_Fehler)}, range raw 0..3, transfer-property=PENDING, to SAM(timeout 3.5 s)  # OpenLoad für Rote LED
            signal RGB_Slave_15_LedGruenOl_XIX_RGBs_Slave_15_XIX_E3V_SAM_LIN9: start 16, 2 bit, little-endian, data-type-policy=OVERRIDE, i-signal-type=PRIMITIVE, init-value=0, base-type=BT_RGB_Slave_15_LedGruenOl, invalid-value=Invalid_RGB_Slave_15_LedGruenOl_XIX_RGBs_Slave_15_XIX_E3V_SAM_LIN9:3, compu {0=Cx0_Init (CM_RGB_Slave_15_LedGruenOl_Cx0_Init), 1=Cx1_nicht_erlaubt (CM_RGB_Slave_15_LedGruenOl_Cx1_nicht_erlaubt), 2=Cx2_kein_Fehler (CM_RGB_Slave_15_LedGruenOl_Cx2_kein_Fehler), 3=Cx3_Fehler (CM_RGB_Slave_15_LedGruenOl_Cx3_Fehler)}, range raw 0..3, transfer-property=PENDING, to SAM(timeout 3.5 s)  # OpenLoad für Rote LED
            signal RGB_Slave_15_LedBlauOl_XIX_RGBs_Slave_15_XIX_E3V_SAM_LIN9: start 18, 2 bit, little-endian, data-type-policy=OVERRIDE, i-signal-type=PRIMITIVE, init-value=0, base-type=BT_RGB_Slave_15_LedBlauOl, invalid-value=Invalid_RGB_Slave_15_LedBlauOl_XIX_RGBs_Slave_15_XIX_E3V_SAM_LIN9:3, compu {0=Cx0_Init (CM_RGB_Slave_15_LedBlauOl_Cx0_Init), 1=Cx1_nicht_erlaubt (CM_RGB_Slave_15_LedBlauOl_Cx1_nicht_erlaubt), 2=Cx2_kein_Fehler (CM_RGB_Slave_15_LedBlauOl_Cx2_kein_Fehler), 3=Cx3_Fehler (CM_RGB_Slave_15_LedBlauOl_Cx3_Fehler)}, range raw 0..3, transfer-property=PENDING, to SAM(timeout 3.5 s)  # OpenLoad für Blaue LED
            signal RGB_Slave_15_TempState_XIX_RGBs_Slave_15_XIX_E3V_SAM_LIN9: start 20, 3 bit, little-endian, data-type-policy=OVERRIDE, i-signal-type=PRIMITIVE, base-type=BT_RGB_Slave_15_TempState, compu {0=Cx0_keine_Temperaturregelung (CM_RGB_Slave_15_TempState_Cx0_keine_Temperaturregelung), 1=Cx1_Regelstufe_1 (CM_RGB_Slave_15_TempState_Cx1_Regelstufe_1), 2=Cx2_Regelstufe_2 (CM_RGB_Slave_15_TempState_Cx2_Regelstufe_2), 3=Cx3_Regelstufe_3 (CM_RGB_Slave_15_TempState_Cx3_Regelstufe_3), 4=Cx4_Regelstufe_4 (CM_RGB_Slave_15_TempState_Cx4_Regelstufe_4), 5=Cx5_Regelstufe_5 (CM_RGB_Slave_15_TempState_Cx5_Regelstufe_5), 6=Cx6_Regelstufe_6 (CM_RGB_Slave_15_TempState_Cx6_Regelstufe_6), 7=Cx7_Regelstufe_7 (CM_RGB_Slave_15_TempState_Cx7_Regelstufe_7)}, range raw 0..7, transfer-property=PENDING, to SAM(timeout 3.5 s)  # Status Temperaturregelung
            signal RGB_Slave_15_IntErrorRam_XIX_RGBs_Slave_15_XIX_E3V_SAM_LIN9: start 24, 2 bit, little-endian, data-type-policy=OVERRIDE, i-signal-type=PRIMITIVE, init-value=0, base-type=BT_RGB_Slave_15_IntErrorRam, invalid-value=Invalid_RGB_Slave_15_IntErrorRam_XIX_RGBs_Slave_15_XIX_E3V_SAM_LIN9:3, compu {0=Cx0_Init (CM_RGB_Slave_15_IntErrorRam_Cx0_Init), 1=Cx1_nicht_erlaubt (CM_RGB_Slave_15_IntErrorRam_Cx1_nicht_erlaubt), 2=Cx2_kein_Fehler (CM_RGB_Slave_15_IntErrorRam_Cx2_kein_Fehler), 3=Cx3_Fehler (CM_RGB_Slave_15_IntErrorRam_Cx3_Fehler)}, range raw 0..3, transfer-property=PENDING, to SAM(timeout 3.5 s)  # Fehler im RAM
            signal RGB_Slave_15_IntErrorRom_XIX_RGBs_Slave_15_XIX_E3V_SAM_LIN9: start 26, 2 bit, little-endian, data-type-policy=OVERRIDE, i-signal-type=PRIMITIVE, init-value=0, base-type=BT_RGB_Slave_15_IntErrorRom, invalid-value=Invalid_RGB_Slave_15_IntErrorRom_XIX_RGBs_Slave_15_XIX_E3V_SAM_LIN9:3, compu {0=Cx0_Init (CM_RGB_Slave_15_IntErrorRom_Cx0_Init), 1=Cx1_nicht_erlaubt (CM_RGB_Slave_15_IntErrorRom_Cx1_nicht_erlaubt), 2=Cx2_kein_Fehler (CM_RGB_Slave_15_IntErrorRom_Cx2_kein_Fehler), 3=Cx3_Fehler (CM_RGB_Slave_15_IntErrorRom_Cx3_Fehler)}, range raw 0..3, transfer-property=PENDING, to SAM(timeout 3.5 s)  # Fehler im ROM
            signal RGB_Slave_15_IntErrorNvm_XIX_RGBs_Slave_15_XIX_E3V_SAM_LIN9: start 28, 2 bit, little-endian, data-type-policy=OVERRIDE, i-signal-type=PRIMITIVE, init-value=0, base-type=BT_RGB_Slave_15_IntErrorNvm, invalid-value=Invalid_RGB_Slave_15_IntErrorNvm_XIX_RGBs_Slave_15_XIX_E3V_SAM_LIN9:3, compu {0=Cx0_Init (CM_RGB_Slave_15_IntErrorNvm_Cx0_Init), 1=Cx1_nicht_erlaubt (CM_RGB_Slave_15_IntErrorNvm_Cx1_nicht_erlaubt), 2=Cx2_kein_Fehler (CM_RGB_Slave_15_IntErrorNvm_Cx2_kein_Fehler), 3=Cx3_Fehler (CM_RGB_Slave_15_IntErrorNvm_Cx3_Fehler)}, range raw 0..3, transfer-property=PENDING, to SAM(timeout 3.5 s)  # Fehler im NVM
        frame SlaveResp_XIX_E3V_SAM_LIN9: id 0x3D, to SAM, frame-length=8, lin-checksum=CLASSIC
          n pdu SlaveResp_XIX_E3V_SAM_LIN9: length=8
        lin schedule table DiagRequest: resume-position=CONTINUE-AT-IT-POSITION, run-mode=RUN-ONCE, application-entry{delay=0.01, position-in-table=0, frame-triggering=CHNL/FT_MasterReq}
        lin schedule table DiagResponse: resume-position=CONTINUE-AT-IT-POSITION, run-mode=RUN-ONCE, application-entry{delay=0.01, position-in-table=0, frame-triggering=CHNL/FT_SlaveResp}
        lin schedule table ST1: resume-position=CONTINUE-AT-IT-POSITION, run-mode=RUN-CONTINUOUS
          table-entrys:
            delay=0.01, position-in-table={0..8}, frame-triggering=CHNL/FT_RGBe_Slave
            delay=0.01, position-in-table=9, frame-triggering=CHNL/FT_RGBs_Slave_01
            delay=0.01, position-in-table={10..18}, frame-triggering=CHNL/FT_RGBe_Slave
            delay=0.01, position-in-table=19, frame-triggering=CHNL/FT_RGBs_Slave_02
            delay=0.01, position-in-table={20..28}, frame-triggering=CHNL/FT_RGBe_Slave
            delay=0.01, position-in-table=29, frame-triggering=CHNL/FT_RGBs_Slave_03
            delay=0.01, position-in-table={30..38}, frame-triggering=CHNL/FT_RGBe_Slave
            delay=0.01, position-in-table=39, frame-triggering=CHNL/FT_RGBs_Slave_04
            delay=0.01, position-in-table={40..48}, frame-triggering=CHNL/FT_RGBe_Slave
            delay=0.01, position-in-table=49, frame-triggering=CHNL/FT_RGBs_Slave_05
            delay=0.01, position-in-table={50..58}, frame-triggering=CHNL/FT_RGBe_Slave
            delay=0.01, position-in-table=59, frame-triggering=CHNL/FT_RGBs_Slave_06
            delay=0.01, position-in-table={60..68}, frame-triggering=CHNL/FT_RGBe_Slave
            delay=0.01, position-in-table=69, frame-triggering=CHNL/FT_RGBs_Slave_07
            delay=0.01, position-in-table={70..78}, frame-triggering=CHNL/FT_RGBe_Slave
            delay=0.01, position-in-table=79, frame-triggering=CHNL/FT_RGBs_Slave_08
            delay=0.01, position-in-table={80..88}, frame-triggering=CHNL/FT_RGBe_Slave
            delay=0.01, position-in-table=89, frame-triggering=CHNL/FT_RGBs_Slave_09
            delay=0.01, position-in-table={90..98}, frame-triggering=CHNL/FT_RGBe_Slave
            delay=0.01, position-in-table=99, frame-triggering=CHNL/FT_RGBs_Slave_10
            delay=0.01, position-in-table={100..108}, frame-triggering=CHNL/FT_RGBe_Slave
            delay=0.01, position-in-table=109, frame-triggering=CHNL/FT_RGBs_Slave_11
            delay=0.01, position-in-table={110..118}, frame-triggering=CHNL/FT_RGBe_Slave
            delay=0.01, position-in-table=119, frame-triggering=CHNL/FT_RGBs_Slave_12
            delay=0.01, position-in-table={120..128}, frame-triggering=CHNL/FT_RGBe_Slave
            delay=0.01, position-in-table=129, frame-triggering=CHNL/FT_RGBs_Slave_13
            delay=0.01, position-in-table={130..138}, frame-triggering=CHNL/FT_RGBe_Slave
            delay=0.01, position-in-table=139, frame-triggering=CHNL/FT_RGBs_Slave_14
            delay=0.01, position-in-table={140..148}, frame-triggering=CHNL/FT_RGBe_Slave
            delay=0.01, position-in-table=149, frame-triggering=CHNL/FT_RGBs_Slave_15
